VERSION "created by canmatrix"

NS_ :

BS_:

BU_: TCM iBooster HCU CIM SCM Right_Hand_Control Left_Hand_Control GPS VCM IC_2 XM GMRS Radio_CANtool Diagnostic_Tool_Digital_Wrench Information_System_Controller_1 STEERING_CONTROLLER VEHICLE_SECURITY RADIO_Hub ABS Battery_Management_Cntrl_2 Battery_Management_Cntrl_1 Auxiliary_Power_Unit_2 Auxiliary_Power_Unit_1 Electric_Propulsion_Cntrl_Unit_4 Electric_Propulsion_Cntrl_Unit_3 Electric_Propulsion_Cntrl_Unit_2 Electric_Propulsion_Cntrl_Unit_1 ECM IC

BO_ 2566687742 AFT1PSI2: 8 Vector__XXX
 SG_ HtrRes : 40|16@1+ (0.1,0) [0.0|6425.5] "ohm" Vector__XXX
 SG_ MaxRes : 32|16@1+ (250,0) [0.0|62500.0] "kohm" Vector__XXX
 SG_ Temp : 16|16@1+ (0.03125,-273) [-273.0|1734.96875] "°C" Vector__XXX
 SG_ RegenFailedCount : 8|8@1+ (1,0) [0.0|250.0] "" Vector__XXX
 SG_ PwrSupply : 4|2@1+ (1,0) [0.0|3.0] "" Vector__XXX
 SG_ DetectionStatus : 0|4@1+ (1,0) [0.0|15.0] "" Vector__XXX

BO_ 2365348350 ELS: 8 Vector__XXX
 SG_ EngLoadShareStatus : 2|4@1+ (1,0) [0.0|15.0] "" Vector__XXX
 SG_ EngUnloadStatus : 0|2@1+ (1,0) [0.0|3.0] "" Vector__XXX

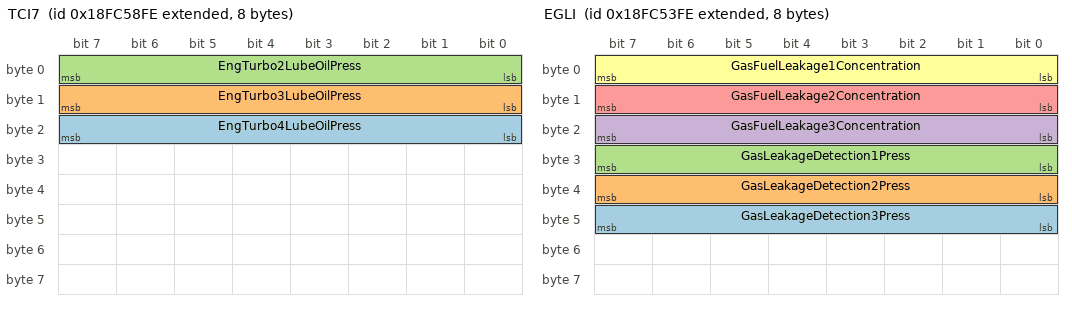
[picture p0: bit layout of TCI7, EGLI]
BO_ 2566674686 TCI7: 8 Vector__XXX
 SG_ EngTurbo4LubeOilPress : 16|8@1+ (4,0) [0.0|1000.0] "kPa" Vector__XXX
 SG_ EngTurbo3LubeOilPress : 8|8@1+ (4,0) [0.0|1000.0] "kPa" Vector__XXX
 SG_ EngTurbo2LubeOilPress : 0|8@1+ (4,0) [0.0|1000.0] "kPa" Vector__XXX

BO_ 2566674430 SCROII1: 8 Vector__XXX
 SG_ DslExhstFldQalityMalfunctionTime : 32|32@1+ (1,0) [0.0|4211081215.0] "s" Vector__XXX
 SG_ DieselExhaustFluidTank1EmptyTime : 0|32@1+ (1,0) [0.0|4211081215.0] "s" Vector__XXX

BO_ 2566674174 SCROII2: 8 Vector__XXX
 SG_ SCROperatorInducementTotalTime : 32|32@1+ (1,0) [0.0|4211081215.0] "s" Vector__XXX
 SG_ AFTSCRMalfunctionTime : 0|32@1+ (1,0) [0.0|4211081215.0] "s" Vector__XXX

BO_ 2566673406 EGLI: 8 Vector__XXX
 SG_ GasLeakageDetection3Press : 40|8@1+ (4,0) [0.0|100.0] "kPa" Vector__XXX
 SG_ GasLeakageDetection2Press : 32|8@1+ (4,0) [0.0|100.0] "kPa" Vector__XXX
 SG_ GasLeakageDetection1Press : 24|8@1+ (4,0) [0.0|100.0] "kPa" Vector__XXX
 SG_ GasFuelLeakage3Concentration : 16|8@1+ (0.5,0) [0.0|100.0] "%" Vector__XXX
 SG_ GasFuelLeakage2Concentration : 8|8@1+ (0.5,0) [0.0|100.0] "%" Vector__XXX
 SG_ GasFuelLeakage1Concentration : 0|8@1+ (0.5,0) [0.0|100.0] "%" Vector__XXX

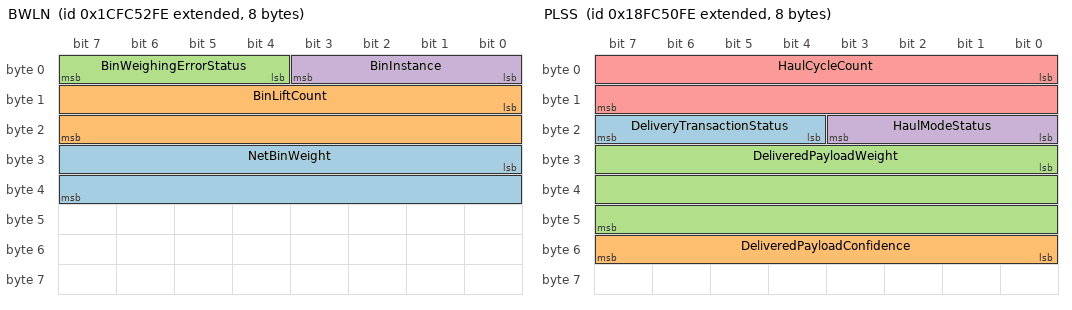
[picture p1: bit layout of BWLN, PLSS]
BO_ 2633782014 BWLN: 8 Vector__XXX
 SG_ NetBinWeight : 24|16@1+ (2,0) [0.0|128510.0] "kg" Vector__XXX
 SG_ BinLiftCount : 8|16@1+ (1,0) [0.0|64255.0] "" Vector__XXX
 SG_ BinWeighingErrorStatus : 4|4@1+ (1,0) [0.0|15.0] "" Vector__XXX
 SG_ BinInstance : 0|4@1+ (1,0) [0.0|15.0] "" Vector__XXX

BO_ 2365346302 ASC7: 8 Vector__XXX
 SG_ LiftAxle2Status : 3|3@1+ (1,0) [0.0|7.0] "" Vector__XXX
 SG_ LiftAxle1Status : 0|3@1+ (1,0) [0.0|7.0] "" Vector__XXX

BO_ 2566672638 PLSS: 8 Vector__XXX
 SG_ DeliveryTransactionStatus : 20|4@1+ (1,0) [0.0|15.0] "" Vector__XXX
 SG_ DeliveredPayloadConfidence : 48|8@1+ (0.5,0) [0.0|100.0] "%" Vector__XXX
 SG_ DeliveredPayloadWeight : 24|24@1+ (2,0) [0.0|32899070.0] "kg" Vector__XXX
 SG_ HaulModeStatus : 16|4@1+ (1,0) [0.0|15.0] "" Vector__XXX
 SG_ HaulCycleCount : 0|16@1+ (1,0) [0.0|64255.0] "" Vector__XXX

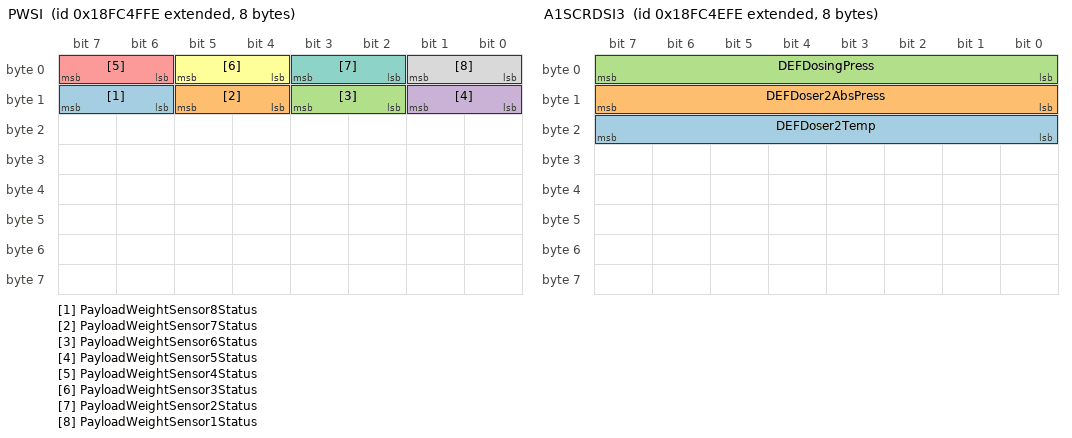
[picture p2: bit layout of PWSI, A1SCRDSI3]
BO_ 2566672382 PWSI: 8 Vector__XXX
 SG_ PayloadWeightSensor8Status : 14|2@1+ (1,0) [0.0|3.0] "" Vector__XXX
 SG_ PayloadWeightSensor7Status : 12|2@1+ (1,0) [0.0|3.0] "" Vector__XXX
 SG_ PayloadWeightSensor6Status : 10|2@1+ (1,0) [0.0|3.0] "" Vector__XXX
 SG_ PayloadWeightSensor5Status : 8|2@1+ (1,0) [0.0|3.0] "" Vector__XXX
 SG_ PayloadWeightSensor4Status : 6|2@1+ (1,0) [0.0|3.0] "" Vector__XXX
 SG_ PayloadWeightSensor3Status : 4|2@1+ (1,0) [0.0|3.0] "" Vector__XXX
 SG_ PayloadWeightSensor2Status : 2|2@1+ (1,0) [0.0|3.0] "" Vector__XXX
 SG_ PayloadWeightSensor1Status : 0|2@1+ (1,0) [0.0|3.0] "" Vector__XXX

BO_ 2566672126 A1SCRDSI3: 8 Vector__XXX
 SG_ DEFDoser2Temp : 16|8@1+ (1,-40) [-40.0|210.0] "°C" Vector__XXX
 SG_ DEFDoser2AbsPress : 8|8@1+ (8,0) [0.0|2000.0] "kPa" Vector__XXX
 SG_ DEFDosingPress : 0|8@1+ (4,0) [0.0|1000.0] "kPa" Vector__XXX

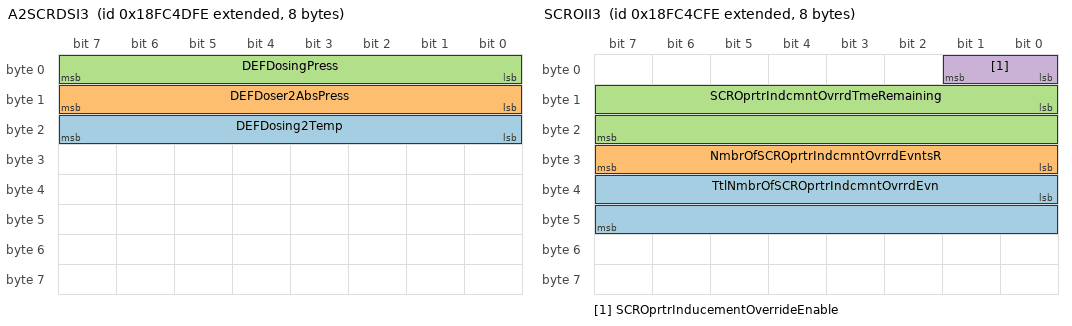
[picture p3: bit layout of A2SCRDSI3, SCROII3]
BO_ 2566671870 A2SCRDSI3: 8 Vector__XXX
 SG_ DEFDosing2Temp : 16|8@1+ (1,-40) [-40.0|210.0] "°C" Vector__XXX
 SG_ DEFDoser2AbsPress : 8|8@1+ (8,0) [0.0|2000.0] "kPa" Vector__XXX
 SG_ DEFDosingPress : 0|8@1+ (4,0) [0.0|1000.0] "kPa" Vector__XXX

BO_ 2566671614 SCROII3: 8 Vector__XXX
 SG_ TtlNmbrOfSCROprtrIndcmntOvrrdEvn : 32|16@1+ (1,0) [0.0|64255.0] "" Vector__XXX
 SG_ NmbrOfSCROprtrIndcmntOvrrdEvntsR : 24|8@1+ (1,0) [0.0|250.0] "" Vector__XXX
 SG_ SCROprtrIndcmntOvrrdTmeRemaining : 8|16@1+ (1,0) [0.0|64255.0] "s" Vector__XXX
 SG_ SCROprtrInducementOverrideEnable : 0|2@1+ (1,0) [0.0|3.0] "" Vector__XXX

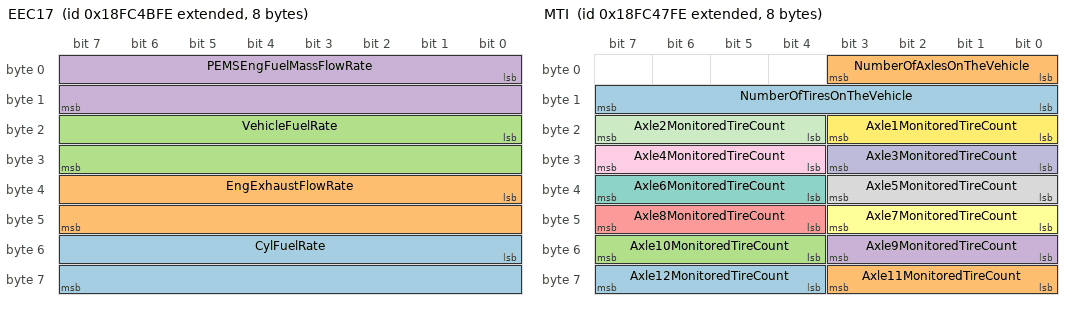
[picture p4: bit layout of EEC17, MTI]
BO_ 2566671358 EEC17: 8 Vector__XXX
 SG_ CylFuelRate : 48|16@1+ (0.03125,0) [0.0|2007.96875] "mg/stroke" Vector__XXX
 SG_ EngExhaustFlowRate : 32|16@1+ (0.2,0) [0.0|12851.0] "kg/h" Vector__XXX
 SG_ VehicleFuelRate : 16|16@1+ (0.02,0) [0.0|1285.1] "g/s" Vector__XXX
 SG_ PEMSEngFuelMassFlowRate : 0|16@1+ (0.02,0) [0.0|1285.1] "g/s" Vector__XXX

BO_ 2566671102 SCRSC: 8 Vector__XXX
 SG_ SCRSystemCleaningForcedStatus : 53|3@1+ (1,0) [0.0|7.0] "" Vector__XXX
 SG_ SCRSystmClnngAtmtcIntationConfig : 48|2@1+ (1,0) [0.0|3.0] "" Vector__XXX
 SG_ SCRSystmClnngInhbtdDTVhclSpdBlwA : 46|2@1+ (1,0) [0.0|3.0] "" Vector__XXX
 SG_ SCRSystmClnngInhbtdDTEngNtWrmdUp : 44|2@1+ (1,0) [0.0|3.0] "" Vector__XXX
 SG_ SCRSystmClnngInhbtdDTPrmnntSystm : 42|2@1+ (1,0) [0.0|3.0] "" Vector__XXX
 SG_ SCRSystmClnngInhbtdDTTmprrySystm : 40|2@1+ (1,0) [0.0|3.0] "" Vector__XXX
 SG_ SCRSystmClnngInhbtdDTSystmTmeout : 38|2@1+ (1,0) [0.0|3.0] "" Vector__XXX
 SG_ SCRSystmClnngInhbtdDTSystmFltAct : 36|2@1+ (1,0) [0.0|3.0] "" Vector__XXX
 SG_ SCRSystmClnngInhbtdDTLwExhstTemp : 34|2@1+ (1,0) [0.0|3.0] "" Vector__XXX
 SG_ SCRSystmClnngInhbtdDTPrkngBrkNtS : 32|2@1+ (1,0) [0.0|3.0] "" Vector__XXX
 SG_ SCRSystmClnngInhbtdDTVhclSpdAbvA : 30|2@1+ (1,0) [0.0|3.0] "" Vector__XXX
 SG_ SCRSystmClnngInhbtdDTOtOfNeutral : 28|2@1+ (1,0) [0.0|3.0] "" Vector__XXX
 SG_ SCRSystmClnngInhbtdDTAcclPdlOffI : 26|2@1+ (1,0) [0.0|3.0] "" Vector__XXX
 SG_ SCRSystmClnngInhbtdDeToPTOActive : 24|2@1+ (1,0) [0.0|3.0] "" Vector__XXX
 SG_ SCRSystmClnngInhbtdDTSrvcBrkActv : 22|2@1+ (1,0) [0.0|3.0] "" Vector__XXX
 SG_ SCRSystmClnngInhbtdDTCltchDsnggd : 20|2@1+ (1,0) [0.0|3.0] "" Vector__XXX
 SG_ SCRSystmClnngInhbtdDTInhbtSwitch : 18|2@1+ (1,0) [0.0|3.0] "" Vector__XXX
 SG_ SCRSystemCleaningInhibitedStatus : 16|2@1+ (1,0) [0.0|3.0] "" Vector__XXX
 SG_ SCRSystemCleaningStatus : 10|2@1+ (1,0) [0.0|3.0] "" Vector__XXX
 SG_ SCRSystemCleaningLampCmd : 0|3@1+ (1,0) [0.0|7.0] "" Vector__XXX

BO_ 2566670846 AT1HI2: 8 Vector__XXX
 SG_ SCRSysAvgDistBetweenCleanEvents : 160|32@1+ (0.125,0) [0.0|526385151.875] "km" Vector__XXX
 SG_ SCRSysAvgTimeBetweenCleanEvents : 128|32@1+ (1,0) [0.0|4211081215.0] "s" Vector__XXX
 SG_ SCRSysTotalSysCleanManReq : 96|32@1+ (1,0) [0.0|4211081215.0] "" Vector__XXX
 SG_ SCRSysTotalSysCleanInhReq : 64|32@1+ (1,0) [0.0|4211081215.0] "" Vector__XXX
 SG_ SCRSysTotalSysCleanEvents : 32|32@1+ (1,0) [0.0|4211081215.0] "" Vector__XXX
 SG_ SCRSysTotalCleanTime : 0|32@1+ (1,0) [0.0|4211081215.0] "s" Vector__XXX

BO_ 2566670590 AT2HI2: 8 Vector__XXX
 SG_ SCRSysAvgDistBetweenCleanEvents : 160|32@1+ (0.125,0) [0.0|526385151.875] "km" Vector__XXX
 SG_ SCRSysAvgTimeBetweenCleanEvents : 128|32@1+ (1,0) [0.0|4211081215.0] "s" Vector__XXX
 SG_ SCRSysTotalSysCleanManReq : 96|32@1+ (1,0) [0.0|4211081215.0] "" Vector__XXX
 SG_ SCRSysTotalSysCleanInhReq : 64|32@1+ (1,0) [0.0|4211081215.0] "" Vector__XXX
 SG_ SCRSysTotalSysCleanEvents : 32|32@1+ (1,0) [0.0|4211081215.0] "" Vector__XXX
 SG_ SCRSysTotalSysCleanTime : 0|32@1+ (1,0) [0.0|4211081215.0] "s" Vector__XXX

BO_ 2566670334 MTI: 8 Vector__XXX
 SG_ Axle12MonitoredTireCount : 60|4@1+ (1,0) [0.0|13.0] "" Vector__XXX
 SG_ Axle11MonitoredTireCount : 56|4@1+ (1,0) [0.0|13.0] "" Vector__XXX
 SG_ Axle10MonitoredTireCount : 52|4@1+ (1,0) [0.0|13.0] "" Vector__XXX
 SG_ Axle9MonitoredTireCount : 48|4@1+ (1,0) [0.0|13.0] "" Vector__XXX
 SG_ Axle8MonitoredTireCount : 44|4@1+ (1,0) [0.0|13.0] "" Vector__XXX
 SG_ Axle7MonitoredTireCount : 40|4@1+ (1,0) [0.0|13.0] "" Vector__XXX
 SG_ Axle6MonitoredTireCount : 36|4@1+ (1,0) [0.0|13.0] "" Vector__XXX
 SG_ Axle5MonitoredTireCount : 32|4@1+ (1,0) [0.0|13.0] "" Vector__XXX
 SG_ Axle4MonitoredTireCount : 28|4@1+ (1,0) [0.0|13.0] "" Vector__XXX
 SG_ Axle3MonitoredTireCount : 24|4@1+ (1,0) [0.0|13.0] "" Vector__XXX
 SG_ Axle2MonitoredTireCount : 20|4@1+ (1,0) [0.0|13.0] "" Vector__XXX
 SG_ Axle1MonitoredTireCount : 16|4@1+ (1,0) [0.0|13.0] "" Vector__XXX
 SG_ NumberOfTiresOnTheVehicle : 8|8@1+ (1,0) [0.0|250.0] "" Vector__XXX
 SG_ NumberOfAxlesOnTheVehicle : 0|4@1+ (1,0) [0.0|13.0] "" Vector__XXX

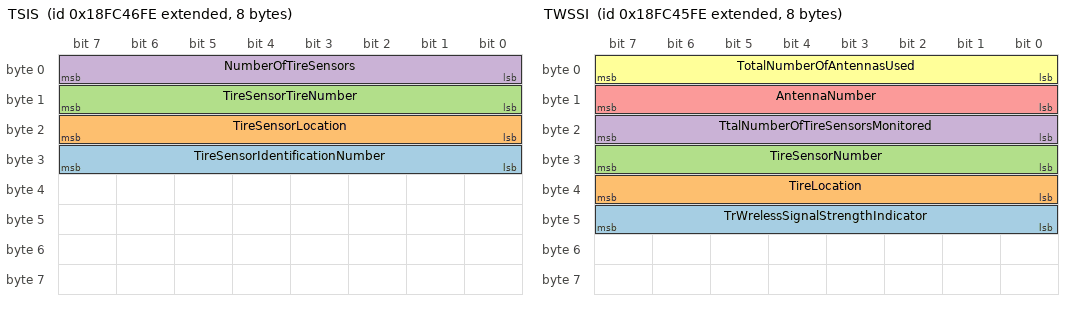
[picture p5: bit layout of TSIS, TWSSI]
BO_ 2566670078 TSIS: 8 Vector__XXX
 SG_ TireSensorIdentificationNumber : 24|8@1+ (1,0) [0.0|255.0] "" Vector__XXX
 SG_ TireSensorLocation : 16|8@1+ (1,0) [0.0|255.0] "" Vector__XXX
 SG_ TireSensorTireNumber : 8|8@1+ (1,0) [0.0|250.0] "" Vector__XXX
 SG_ NumberOfTireSensors : 0|8@1+ (1,0) [0.0|250.0] "" Vector__XXX

BO_ 2566669822 TWSSI: 8 Vector__XXX
 SG_ TrWrelessSignalStrengthIndicator : 40|8@1+ (0.5,-125) [-125.0|0.0] "dBm" Vector__XXX
 SG_ TireLocation : 32|8@1+ (1,0) [0.0|0.0] "" Vector__XXX
 SG_ TireSensorNumber : 24|8@1+ (1,0) [0.0|250.0] "" Vector__XXX
 SG_ TtalNumberOfTireSensorsMonitored : 16|8@1+ (1,0) [0.0|250.0] "" Vector__XXX
 SG_ AntennaNumber : 8|8@1+ (1,0) [0.0|250.0] "" Vector__XXX
 SG_ TotalNumberOfAntennasUsed : 0|8@1+ (1,0) [0.0|250.0] "" Vector__XXX

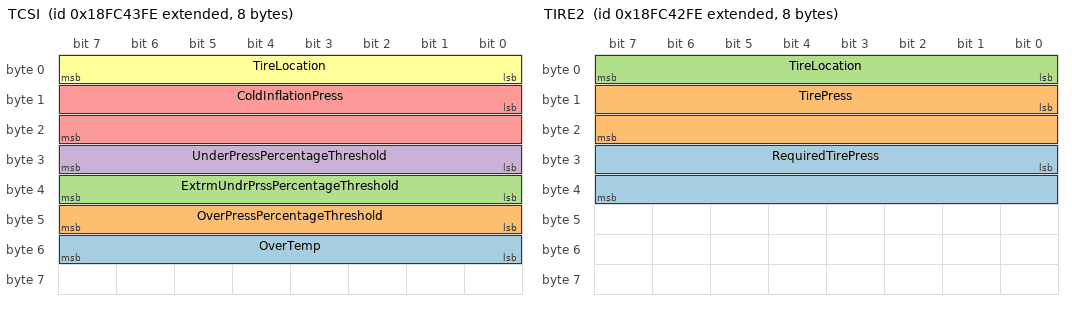
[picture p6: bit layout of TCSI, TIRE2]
BO_ 2566669310 TCSI: 8 Vector__XXX
 SG_ OverTemp : 48|8@1+ (1,-40) [-40.0|210.0] "°C" Vector__XXX
 SG_ OverPressPercentageThreshold : 40|8@1+ (0.5,0) [0.0|125.0] "%" Vector__XXX
 SG_ ExtrmUndrPrssPercentageThreshold : 32|8@1+ (0.5,0) [0.0|125.0] "%" Vector__XXX
 SG_ UnderPressPercentageThreshold : 24|8@1+ (0.5,0) [0.0|125.0] "%" Vector__XXX
 SG_ ColdInflationPress : 8|16@1+ (1,0) [0.0|64255.0] "kPa" Vector__XXX
 SG_ TireLocation : 0|8@1+ (1,0) [0.0|0.0] "" Vector__XXX

BO_ 2566669054 TIRE2: 8 Vector__XXX
 SG_ RequiredTirePress : 24|16@1+ (1,0) [0.0|64255.0] "kPa" Vector__XXX
 SG_ TirePress : 8|16@1+ (1,0) [0.0|64255.0] "kPa" Vector__XXX
 SG_ TireLocation : 0|8@1+ (1,0) [0.0|0.0] "" Vector__XXX

BO_ 2566668798 AF4: 8 Vector__XXX
 SG_ EngFl2InjctorMeteringRail1Press2 : 48|16@1+ (2,0) [0.0|128510.0] "kPa" Vector__XXX
 SG_ EngFel2InjectorMeteringRail2Temp : 40|8@1+ (1,-40) [-40.0|210.0] "°C" Vector__XXX
 SG_ EngFel2InjectorMeteringRail1Temp : 32|8@1+ (1,-40) [-40.0|210.0] "°C" Vector__XXX
 SG_ EngFl2InjectorMeteringRail2Press : 16|16@1+ (2,0) [0.0|128510.0] "kPa" Vector__XXX
 SG_ EngFl2InjectorMeteringRail1Press : 0|16@1+ (2,0) [0.0|128510.0] "kPa" Vector__XXX

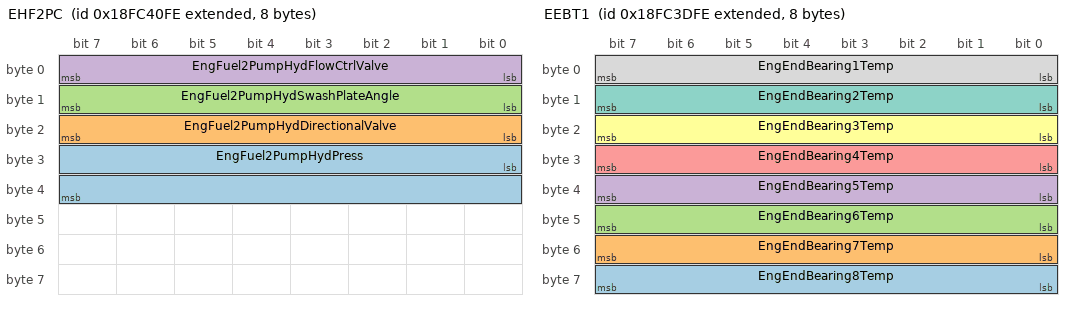
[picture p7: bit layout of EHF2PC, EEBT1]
BO_ 2566668542 EHF2PC: 8 Vector__XXX
 SG_ EngFuel2PumpHydPress : 24|16@1+ (2,0) [0.0|128510.0] "kPa" Vector__XXX
 SG_ EngFuel2PumpHydDirectionalValve : 16|8@1+ (0.4,0) [0.0|100.0] "%" Vector__XXX
 SG_ EngFuel2PumpHydSwashPlateAngle : 8|8@1+ (0.4,0) [0.0|100.0] "%" Vector__XXX
 SG_ EngFuel2PumpHydFlowCtrlValve : 0|8@1+ (0.4,0) [0.0|100.0] "%" Vector__XXX

BO_ 2566668286 ETCC2: 8 Vector__XXX
 SG_ EngStagedTurboSolenoidStatus : 0|8@1+ (0.4,0) [0.0|100.0] "%" Vector__XXX

BO_ 2566668030 HEDPI: 8 Vector__XXX
 SG_ HtExchngerDebrisPurgeApproaching : 2|2@1+ (1,0) [0.0|3.0] "" Vector__XXX
 SG_ HeatExchangerDebrisPurgeStatus : 0|2@1+ (1,0) [0.0|3.0] "" Vector__XXX

BO_ 2566667774 EEBT1: 8 Vector__XXX
 SG_ EngEndBearing8Temp : 56|8@1+ (1,-40) [-40.0|210.0] "°C" Vector__XXX
 SG_ EngEndBearing7Temp : 48|8@1+ (1,-40) [-40.0|210.0] "°C" Vector__XXX
 SG_ EngEndBearing6Temp : 40|8@1+ (1,-40) [-40.0|210.0] "°C" Vector__XXX
 SG_ EngEndBearing5Temp : 32|8@1+ (1,-40) [-40.0|210.0] "°C" Vector__XXX
 SG_ EngEndBearing4Temp : 24|8@1+ (1,-40) [-40.0|210.0] "°C" Vector__XXX
 SG_ EngEndBearing3Temp : 16|8@1+ (1,-40) [-40.0|210.0] "°C" Vector__XXX
 SG_ EngEndBearing2Temp : 8|8@1+ (1,-40) [-40.0|210.0] "°C" Vector__XXX
 SG_ EngEndBearing1Temp : 0|8@1+ (1,-40) [-40.0|210.0] "°C" Vector__XXX

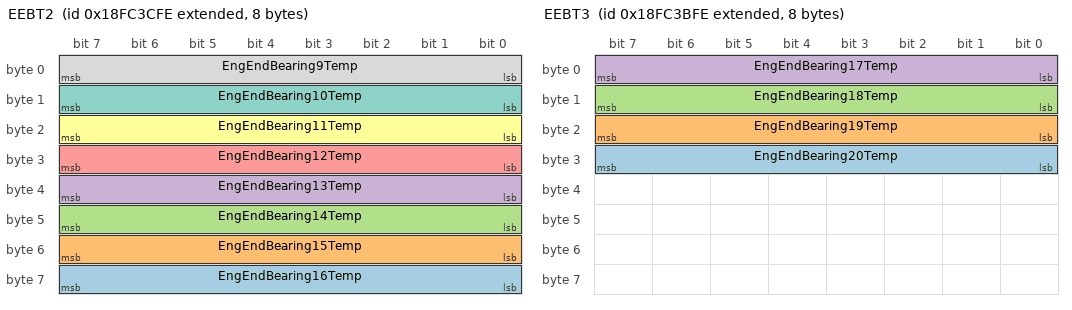
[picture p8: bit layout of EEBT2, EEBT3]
BO_ 2566667518 EEBT2: 8 Vector__XXX
 SG_ EngEndBearing16Temp : 56|8@1+ (1,-40) [-40.0|210.0] "°C" Vector__XXX
 SG_ EngEndBearing15Temp : 48|8@1+ (1,-40) [-40.0|210.0] "°C" Vector__XXX
 SG_ EngEndBearing14Temp : 40|8@1+ (1,-40) [-40.0|210.0] "°C" Vector__XXX
 SG_ EngEndBearing13Temp : 32|8@1+ (1,-40) [-40.0|210.0] "°C" Vector__XXX
 SG_ EngEndBearing12Temp : 24|8@1+ (1,-40) [-40.0|210.0] "°C" Vector__XXX
 SG_ EngEndBearing11Temp : 16|8@1+ (1,-40) [-40.0|210.0] "°C" Vector__XXX
 SG_ EngEndBearing10Temp : 8|8@1+ (1,-40) [-40.0|210.0] "°C" Vector__XXX
 SG_ EngEndBearing9Temp : 0|8@1+ (1,-40) [-40.0|210.0] "°C" Vector__XXX

BO_ 2566667262 EEBT3: 8 Vector__XXX
 SG_ EngEndBearing20Temp : 24|8@1+ (1,-40) [-40.0|210.0] "°C" Vector__XXX
 SG_ EngEndBearing19Temp : 16|8@1+ (1,-40) [-40.0|210.0] "°C" Vector__XXX
 SG_ EngEndBearing18Temp : 8|8@1+ (1,-40) [-40.0|210.0] "°C" Vector__XXX
 SG_ EngEndBearing17Temp : 0|8@1+ (1,-40) [-40.0|210.0] "°C" Vector__XXX

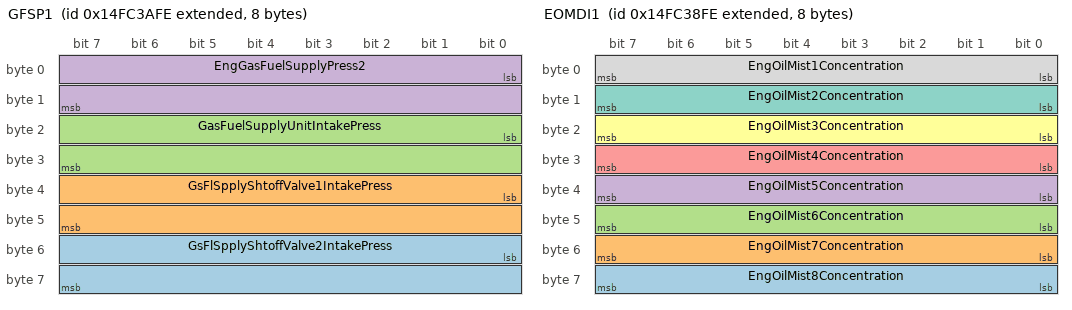
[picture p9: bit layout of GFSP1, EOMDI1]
BO_ 2499558142 GFSP1: 8 Vector__XXX
 SG_ GsFlSpplyShtoffValve2IntakePress : 48|16@1+ (0.5,0) [0.0|32127.5] "kPa" Vector__XXX
 SG_ GsFlSpplyShtoffValve1IntakePress : 32|16@1+ (0.5,0) [0.0|32127.5] "kPa" Vector__XXX
 SG_ GasFuelSupplyUnitIntakePress : 16|16@1+ (0.5,0) [0.0|32127.5] "kPa" Vector__XXX
 SG_ EngGasFuelSupplyPress2 : 0|16@1+ (0.5,0) [0.0|32127.5] "kPa" Vector__XXX

BO_ 2499557886 GFSP2: 8 Vector__XXX
 SG_ PlantInertGasSupplyOutletPress : 16|16@1+ (0.5,0) [0.0|32127.5] "kPa" Vector__XXX
 SG_ PlantGasFuelSupplyOutletPress : 0|16@1+ (0.5,0) [0.0|32127.5] "kPa" Vector__XXX

BO_ 2499557630 EOMDI1: 8 Vector__XXX
 SG_ EngOilMist8Concentration : 56|8@1+ (1,0) [0.0|250.0] "%" Vector__XXX
 SG_ EngOilMist7Concentration : 48|8@1+ (1,0) [0.0|250.0] "%" Vector__XXX
 SG_ EngOilMist6Concentration : 40|8@1+ (1,0) [0.0|250.0] "%" Vector__XXX
 SG_ EngOilMist5Concentration : 32|8@1+ (1,0) [0.0|250.0] "%" Vector__XXX
 SG_ EngOilMist4Concentration : 24|8@1+ (1,0) [0.0|250.0] "%" Vector__XXX
 SG_ EngOilMist3Concentration : 16|8@1+ (1,0) [0.0|250.0] "%" Vector__XXX
 SG_ EngOilMist2Concentration : 8|8@1+ (1,0) [0.0|250.0] "%" Vector__XXX
 SG_ EngOilMist1Concentration : 0|8@1+ (1,0) [0.0|250.0] "%" Vector__XXX

BO_ 2499557374 EOMDI2: 8 Vector__XXX
 SG_ EngOilMist10Concentration : 8|8@1+ (1,0) [0.0|250.0] "%" Vector__XXX
 SG_ EngOilMist9Concentration : 0|8@1+ (1,0) [0.0|250.0] "%" Vector__XXX

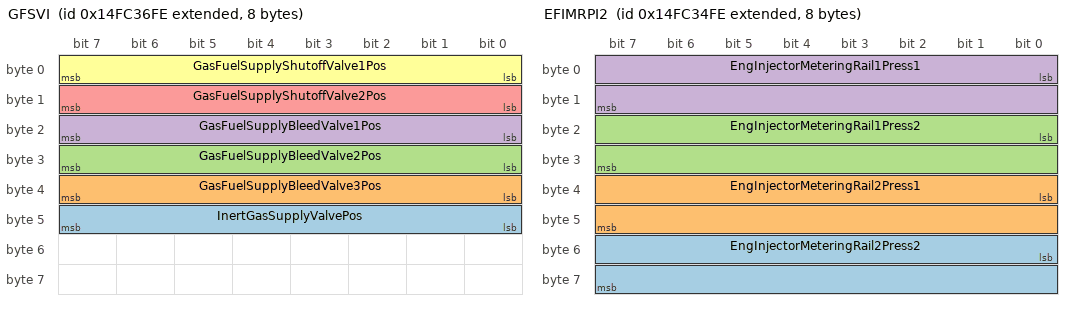
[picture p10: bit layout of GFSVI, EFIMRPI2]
BO_ 2499557118 GFSVI: 8 Vector__XXX
 SG_ InertGasSupplyValvePos : 40|8@1+ (0.4,0) [0.0|100.0] "%" Vector__XXX
 SG_ GasFuelSupplyBleedValve3Pos : 32|8@1+ (0.4,0) [0.0|100.0] "%" Vector__XXX
 SG_ GasFuelSupplyBleedValve2Pos : 24|8@1+ (0.4,0) [0.0|100.0] "%" Vector__XXX
 SG_ GasFuelSupplyBleedValve1Pos : 16|8@1+ (0.4,0) [0.0|100.0] "%" Vector__XXX
 SG_ GasFuelSupplyShutoffValve2Pos : 8|8@1+ (0.4,0) [0.0|100.0] "%" Vector__XXX
 SG_ GasFuelSupplyShutoffValve1Pos : 0|8@1+ (0.4,0) [0.0|100.0] "%" Vector__XXX

BO_ 2566665726 AT2P1I: 8 Vector__XXX
 SG_ TwoMotorSpd : 8|16@1+ (0.5,0) [0.0|32127.5] "rpm" Vector__XXX
 SG_ Htr : 0|8@1+ (0.4,0) [0.0|100.0] "%" Vector__XXX

BO_ 2499556606 EFIMRPI2: 8 Vector__XXX
 SG_ EngInjectorMeteringRail2Press2 : 48|16@1+ (5,0) [0.0|321275.0] "kPa" Vector__XXX
 SG_ EngInjectorMeteringRail2Press1 : 32|16@1+ (5,0) [0.0|321275.0] "kPa" Vector__XXX
 SG_ EngInjectorMeteringRail1Press2 : 16|16@1+ (5,0) [0.0|321275.0] "kPa" Vector__XXX
 SG_ EngInjectorMeteringRail1Press1 : 0|16@1+ (5,0) [0.0|321275.0] "kPa" Vector__XXX

BO_ 2499556350 EFIMRPI3: 8 Vector__XXX
 SG_ EngInjctrMtringRail2DesiredPress : 16|16@1+ (5,0) [0.0|321275.0] "kPa" Vector__XXX
 SG_ EngInjctrMtringRail1DesiredPress : 0|16@1+ (5,0) [0.0|321275.0] "kPa" Vector__XXX

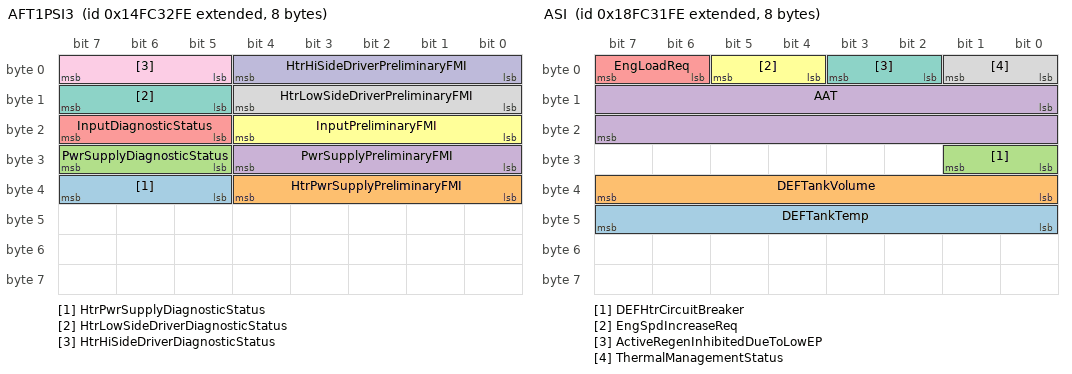
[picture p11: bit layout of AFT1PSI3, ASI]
BO_ 2499556094 AFT1PSI3: 8 Vector__XXX
 SG_ HtrPwrSupplyDiagnosticStatus : 37|3@1+ (1,0) [0.0|7.0] "" Vector__XXX
 SG_ HtrPwrSupplyPreliminaryFMI : 32|5@1+ (1,0) [0.0|31.0] "" Vector__XXX
 SG_ PwrSupplyDiagnosticStatus : 29|3@1+ (1,0) [0.0|7.0] "" Vector__XXX
 SG_ PwrSupplyPreliminaryFMI : 24|5@1+ (1,0) [0.0|31.0] "" Vector__XXX
 SG_ InputDiagnosticStatus : 21|3@1+ (1,0) [0.0|7.0] "" Vector__XXX
 SG_ InputPreliminaryFMI : 16|5@1+ (1,0) [0.0|31.0] "" Vector__XXX
 SG_ HtrLowSideDriverDiagnosticStatus : 13|3@1+ (1,0) [0.0|7.0] "" Vector__XXX
 SG_ HtrLowSideDriverPreliminaryFMI : 8|5@1+ (1,0) [0.0|31.0] "" Vector__XXX
 SG_ HtrHiSideDriverDiagnosticStatus : 5|3@1+ (1,0) [0.0|7.0] "" Vector__XXX
 SG_ HtrHiSideDriverPreliminaryFMI : 0|5@1+ (1,0) [0.0|31.0] "" Vector__XXX

BO_ 2566664702 ASI: 8 Vector__XXX
 SG_ DEFTankTemp : 40|8@1+ (1,-40) [-40.0|210.0] "°C" Vector__XXX
 SG_ DEFTankVolume : 32|8@1+ (0.4,0) [0.0|100.0] "%" Vector__XXX
 SG_ DEFHtrCircuitBreaker : 24|2@1+ (1,0) [0.0|3.0] "" Vector__XXX
 SG_ AAT : 8|16@1+ (0.03125,-273) [-273.0|1734.96875] "°C" Vector__XXX
 SG_ EngLoadReq : 6|2@1+ (1,0) [0.0|3.0] "" Vector__XXX
 SG_ EngSpdIncreaseReq : 4|2@1+ (1,0) [0.0|3.0] "" Vector__XXX
 SG_ ActiveRegenInhibitedDueToLowEP : 2|2@1+ (1,0) [0.0|3.0] "" Vector__XXX
 SG_ ThermalManagementStatus : 0|2@1+ (1,0) [0.0|3.0] "" Vector__XXX

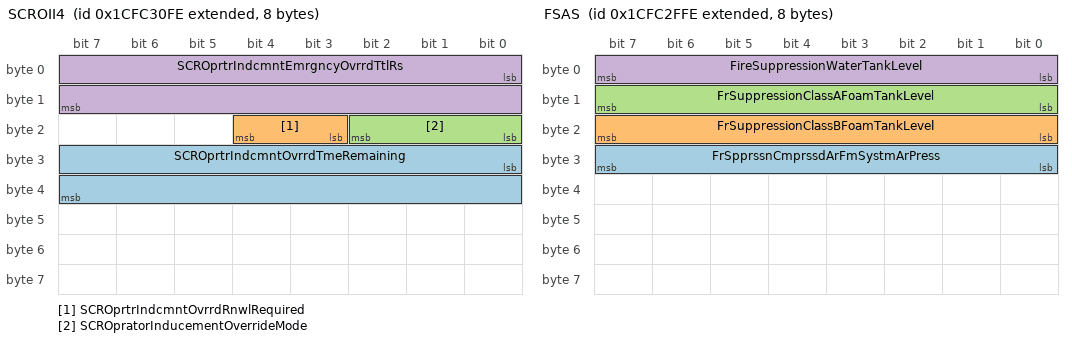
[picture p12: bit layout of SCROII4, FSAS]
BO_ 2633773310 SCROII4: 8 Vector__XXX
 SG_ SCROprtrIndcmntOvrrdTmeRemaining : 24|16@1+ (1,0) [0.0|64255.0] "min" Vector__XXX
 SG_ SCROprtrIndcmntOvrrdRnwlRequired : 19|2@1+ (1,0) [0.0|3.0] "" Vector__XXX
 SG_ SCROpratorInducementOverrideMode : 16|3@1+ (1,0) [0.0|7.0] "" Vector__XXX
 SG_ SCROprtrIndcmntEmrgncyOvrrdTtlRs : 0|16@1+ (1,0) [0.0|64255.0] "" Vector__XXX

BO_ 2633773054 FSAS: 8 Vector__XXX
 SG_ FrSpprssnCmprssdArFmSystmArPress : 24|8@1+ (8,0) [0.0|2000.0] "kPa" Vector__XXX
 SG_ FrSuppressionClassBFoamTankLevel : 16|8@1+ (0.4,0) [0.0|100.0] "%" Vector__XXX
 SG_ FrSuppressionClassAFoamTankLevel : 8|8@1+ (0.4,0) [0.0|100.0] "%" Vector__XXX
 SG_ FireSuppressionWaterTankLevel : 0|8@1+ (0.4,0) [0.0|100.0] "%" Vector__XXX

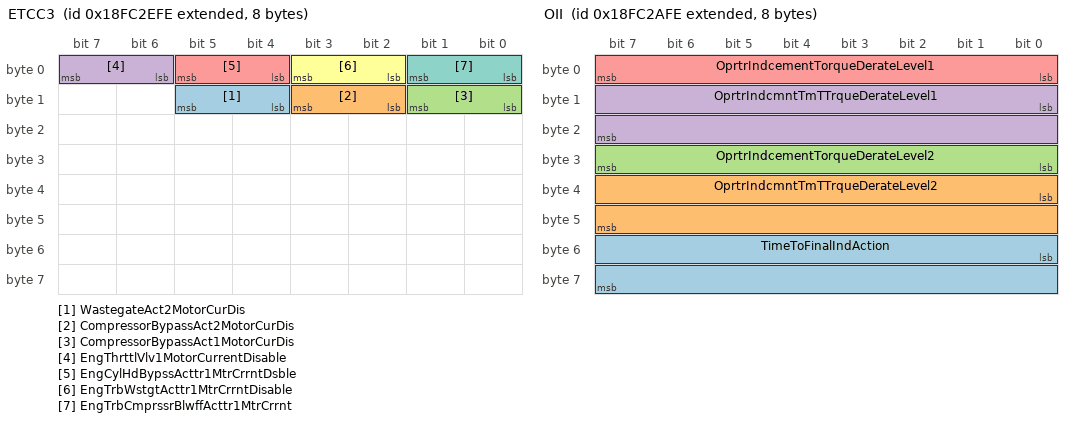
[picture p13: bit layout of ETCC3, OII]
BO_ 2566663934 ETCC3: 8 Vector__XXX
 SG_ WastegateAct2MotorCurDis : 12|2@1+ (1,0) [0.0|3.0] "" Vector__XXX
 SG_ CompressorBypassAct2MotorCurDis : 10|2@1+ (1,0) [0.0|3.0] "" Vector__XXX
 SG_ CompressorBypassAct1MotorCurDis : 8|2@1+ (1,0) [0.0|3.0] "" Vector__XXX
 SG_ EngThrttlVlv1MotorCurrentDisable : 6|2@1+ (1,0) [0.0|3.0] "" Vector__XXX
 SG_ EngCylHdBypssActtr1MtrCrrntDsble : 4|2@1+ (1,0) [0.0|3.0] "" Vector__XXX
 SG_ EngTrbWstgtActtr1MtrCrrntDisable : 2|2@1+ (1,0) [0.0|3.0] "" Vector__XXX
 SG_ EngTrbCmprssrBlwffActtr1MtrCrrnt : 0|2@1+ (1,0) [0.0|3.0] "" Vector__XXX

BO_ 2566663678 AF5: 8 Vector__XXX
 SG_ EngFl2InjectorMeteringRail1Temp2 : 32|8@1+ (1,-40) [-40.0|210.0] "°C" Vector__XXX
 SG_ LNGTank2VaporPress : 16|16@1+ (0.1,0) [0.0|6425.5] "kPa" Vector__XXX
 SG_ LNGTank1VaporPress : 0|16@1+ (0.1,0) [0.0|6425.5] "kPa" Vector__XXX

BO_ 2566663422 BCLC: 8 Vector__XXX
 SG_ TrlrBrkClprLnngClranceAxle5Right : 38|2@1+ (1,0) [0.0|3.0] "" Vector__XXX
 SG_ TrlrBrkClprLnngClaranceAxle5Left : 36|2@1+ (1,0) [0.0|3.0] "" Vector__XXX
 SG_ TrlrBrkClprLnngClranceAxle4Right : 34|2@1+ (1,0) [0.0|3.0] "" Vector__XXX
 SG_ TrlrBrkClprLnngClaranceAxle4Left : 32|2@1+ (1,0) [0.0|3.0] "" Vector__XXX
 SG_ TrlrBrkClprLnngClranceAxle3Right : 30|2@1+ (1,0) [0.0|3.0] "" Vector__XXX
 SG_ TrlrBrkClprLnngClaranceAxle3Left : 28|2@1+ (1,0) [0.0|3.0] "" Vector__XXX
 SG_ TrlrBrkClprLnngClranceAxle2Right : 26|2@1+ (1,0) [0.0|3.0] "" Vector__XXX
 SG_ TrlrBrkClprLnngClaranceAxle2Left : 24|2@1+ (1,0) [0.0|3.0] "" Vector__XXX
 SG_ TrlrBrkClprLnngClranceAxle1Right : 22|2@1+ (1,0) [0.0|3.0] "" Vector__XXX
 SG_ TrlrBrkClprLnngClaranceAxle1Left : 20|2@1+ (1,0) [0.0|3.0] "" Vector__XXX
 SG_ TrctrBrkClprLnngClrnceAxle5Right : 18|2@1+ (1,0) [0.0|3.0] "" Vector__XXX
 SG_ TrctrBrkClprLnngClranceAxle5Left : 16|2@1+ (1,0) [0.0|3.0] "" Vector__XXX
 SG_ TrctrBrkClprLnngClrnceAxle4Right : 14|2@1+ (1,0) [0.0|3.0] "" Vector__XXX
 SG_ TrctrBrkClprLnngClranceAxle4Left : 12|2@1+ (1,0) [0.0|3.0] "" Vector__XXX
 SG_ TrctrBrkClprLnngClrnceAxle3Right : 10|2@1+ (1,0) [0.0|3.0] "" Vector__XXX
 SG_ TrctrBrkClprLnngClranceAxle3Left : 8|2@1+ (1,0) [0.0|3.0] "" Vector__XXX
 SG_ TrctrBrkClprLnngClrnceAxle2Right : 6|2@1+ (1,0) [0.0|3.0] "" Vector__XXX
 SG_ TrctrBrkClprLnngClranceAxle2Left : 4|2@1+ (1,0) [0.0|3.0] "" Vector__XXX
 SG_ TrctrBrkClprLnngClrnceAxle1Right : 2|2@1+ (1,0) [0.0|3.0] "" Vector__XXX
 SG_ TrctrBrkClprLnngClranceAxle1Left : 0|2@1+ (1,0) [0.0|3.0] "" Vector__XXX

BO_ 2566663166 CCVS4: 8 Vector__XXX
 SG_ CruiseCtrlAdjustedMaxSpeed : 16|16@1+ (0.00390625,0) [0.0|250.996] "km/h" Vector__XXX
 SG_ AppliedVehicleSpeedLimit : 0|16@1+ (0.00390625,0) [0.0|250.996] "km/h" Vector__XXX

BO_ 2566662910 OII: 8 Vector__XXX
 SG_ TimeToFinalIndAction : 48|16@1+ (1,0) [0.0|64255.0] "min" Vector__XXX
 SG_ OprtrIndcmntTmTTrqueDerateLevel2 : 32|16@1+ (1,0) [0.0|64255.0] "min" Vector__XXX
 SG_ OprtrIndcementTorqueDerateLevel2 : 24|8@1+ (1,0) [0.0|250.0] "%" Vector__XXX
 SG_ OprtrIndcmntTmTTrqueDerateLevel1 : 8|16@1+ (1,0) [0.0|64255.0] "min" Vector__XXX
 SG_ OprtrIndcementTorqueDerateLevel1 : 0|8@1+ (1,0) [0.0|250.0] "%" Vector__XXX

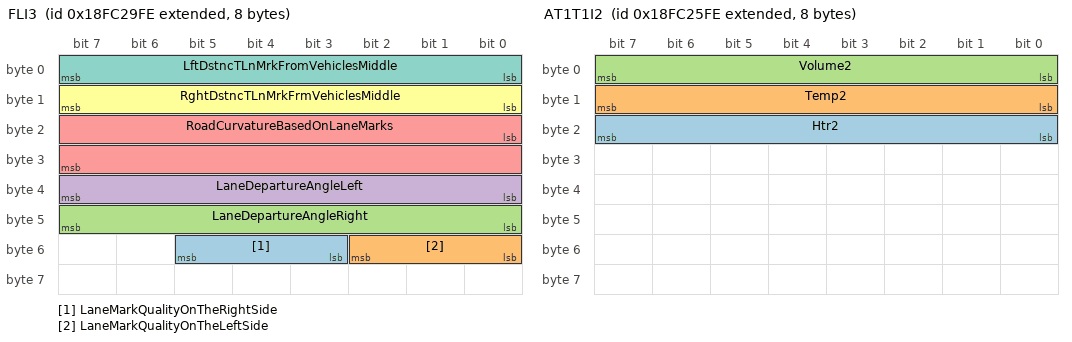
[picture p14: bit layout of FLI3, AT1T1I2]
BO_ 2566662654 FLI3: 8 Vector__XXX
 SG_ LaneMarkQualityOnTheRightSide : 51|3@1+ (1,0) [0.0|7.0] "" Vector__XXX
 SG_ LaneMarkQualityOnTheLeftSide : 48|3@1+ (1,0) [0.0|7.0] "" Vector__XXX
 SG_ LaneDepartureAngleRight : 40|8@1+ (0.1,-12.5) [-12.5|12.5] "deg" Vector__XXX
 SG_ LaneDepartureAngleLeft : 32|8@1+ (0.1,-12.5) [-12.5|12.5] "deg" Vector__XXX
 SG_ RoadCurvatureBasedOnLaneMarks : 16|16@1+ (0.0078125,-250) [-250.0|251.992] "1/km" Vector__XXX
 SG_ RghtDstncTLnMrkFrmVehiclesMiddle : 8|8@1+ (0.02,0) [0.0|5.0] "m" Vector__XXX
 SG_ LftDstncTLnMrkFromVehiclesMiddle : 0|8@1+ (0.02,0) [0.0|5.0] "m" Vector__XXX

BO_ 2566662142 A1DEFI2: 8 Vector__XXX
 SG_ Ctrl2Temp : 8|8@1+ (1,-40) [-40.0|210.0] "°C" Vector__XXX
 SG_ Ctrl1Temp : 0|8@1+ (1,-40) [-40.0|210.0] "°C" Vector__XXX

BO_ 2566661630 AT1T1I2: 8 Vector__XXX
 SG_ Htr2 : 16|8@1+ (0.4,0) [0.0|100.0] "%" Vector__XXX
 SG_ Temp2 : 8|8@1+ (1,-40) [-40.0|210.0] "°C" Vector__XXX
 SG_ Volume2 : 0|8@1+ (0.4,0) [0.0|100.0] "%" Vector__XXX

BO_ 2566661374 A2DEFT1: 8 Vector__XXX
 SG_ Ctrl2Temp : 8|8@1+ (1,-40) [-40.0|210.0] "°C" Vector__XXX
 SG_ CtrlTemp : 0|8@1+ (1,-40) [-40.0|210.0] "°C" Vector__XXX
 SG_ Htr2 : 16|8@1+ (0.4,0) [0.0|100.0] "%" Vector__XXX
 SG_ Temp2 : 8|8@1+ (1,-40) [-40.0|210.0] "°C" Vector__XXX
 SG_ Volume2 : 0|8@1+ (0.4,0) [0.0|100.0] "%" Vector__XXX

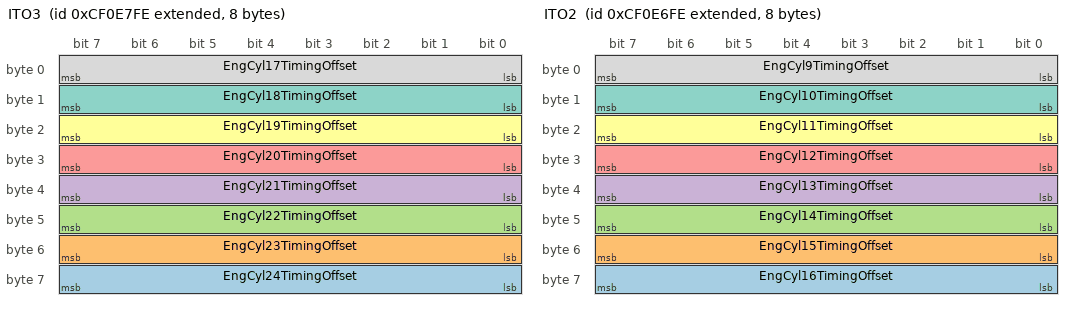
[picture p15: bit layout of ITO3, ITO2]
BO_ 2364598270 ITO3: 8 Vector__XXX
 SG_ EngCyl24TimingOffset : 56|8@1+ (0.1,-12.5) [-12.5|12.5] "deg" Vector__XXX
 SG_ EngCyl23TimingOffset : 48|8@1+ (0.1,-12.5) [-12.5|12.5] "deg" Vector__XXX
 SG_ EngCyl22TimingOffset : 40|8@1+ (0.1,-12.5) [-12.5|12.5] "deg" Vector__XXX
 SG_ EngCyl21TimingOffset : 32|8@1+ (0.1,-12.5) [-12.5|12.5] "deg" Vector__XXX
 SG_ EngCyl20TimingOffset : 24|8@1+ (0.1,-12.5) [-12.5|12.5] "deg" Vector__XXX
 SG_ EngCyl19TimingOffset : 16|8@1+ (0.1,-12.5) [-12.5|12.5] "deg" Vector__XXX
 SG_ EngCyl18TimingOffset : 8|8@1+ (0.1,-12.5) [-12.5|12.5] "deg" Vector__XXX
 SG_ EngCyl17TimingOffset : 0|8@1+ (0.1,-12.5) [-12.5|12.5] "deg" Vector__XXX

BO_ 2364598014 ITO2: 8 Vector__XXX
 SG_ EngCyl16TimingOffset : 56|8@1+ (0.1,-12.5) [-12.5|12.5] "deg" Vector__XXX
 SG_ EngCyl15TimingOffset : 48|8@1+ (0.1,-12.5) [-12.5|12.5] "deg" Vector__XXX
 SG_ EngCyl14TimingOffset : 40|8@1+ (0.1,-12.5) [-12.5|12.5] "deg" Vector__XXX
 SG_ EngCyl13TimingOffset : 32|8@1+ (0.1,-12.5) [-12.5|12.5] "deg" Vector__XXX
 SG_ EngCyl12TimingOffset : 24|8@1+ (0.1,-12.5) [-12.5|12.5] "deg" Vector__XXX
 SG_ EngCyl11TimingOffset : 16|8@1+ (0.1,-12.5) [-12.5|12.5] "deg" Vector__XXX
 SG_ EngCyl10TimingOffset : 8|8@1+ (0.1,-12.5) [-12.5|12.5] "deg" Vector__XXX
 SG_ EngCyl9TimingOffset : 0|8@1+ (0.1,-12.5) [-12.5|12.5] "deg" Vector__XXX

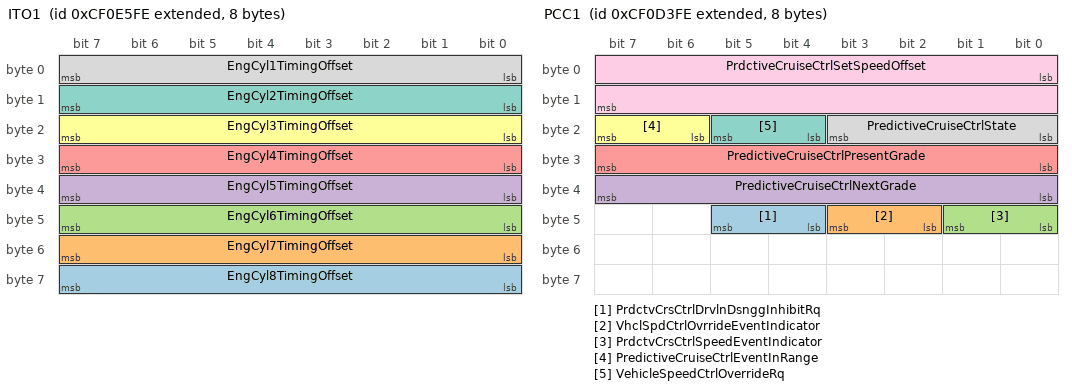
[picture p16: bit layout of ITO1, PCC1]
BO_ 2364597758 ITO1: 8 Vector__XXX
 SG_ EngCyl8TimingOffset : 56|8@1+ (0.1,-12.5) [-12.5|12.5] "deg" Vector__XXX
 SG_ EngCyl7TimingOffset : 48|8@1+ (0.1,-12.5) [-12.5|12.5] "deg" Vector__XXX
 SG_ EngCyl6TimingOffset : 40|8@1+ (0.1,-12.5) [-12.5|12.5] "deg" Vector__XXX
 SG_ EngCyl5TimingOffset : 32|8@1+ (0.1,-12.5) [-12.5|12.5] "deg" Vector__XXX
 SG_ EngCyl4TimingOffset : 24|8@1+ (0.1,-12.5) [-12.5|12.5] "deg" Vector__XXX
 SG_ EngCyl3TimingOffset : 16|8@1+ (0.1,-12.5) [-12.5|12.5] "deg" Vector__XXX
 SG_ EngCyl2TimingOffset : 8|8@1+ (0.1,-12.5) [-12.5|12.5] "deg" Vector__XXX
 SG_ EngCyl1TimingOffset : 0|8@1+ (0.1,-12.5) [-12.5|12.5] "deg" Vector__XXX

BO_ 2364593150 PCC1: 8 Vector__XXX
 SG_ PrdctvCrsCtrlDrvlnDsnggInhibitRq : 44|2@1+ (1,0) [0.0|3.0] "" Vector__XXX
 SG_ VhclSpdCtrlOvrrideEventIndicator : 42|2@1+ (1,0) [0.0|3.0] "" Vector__XXX
 SG_ PrdctvCrsCtrlSpeedEventIndicator : 40|2@1+ (1,0) [0.0|3.0] "" Vector__XXX
 SG_ PredictiveCruiseCtrlNextGrade : 32|8@1+ (0.125,-16) [-16.0|15.25] "%" Vector__XXX
 SG_ PredictiveCruiseCtrlPresentGrade : 24|8@1+ (0.125,-16) [-16.0|15.25] "%" Vector__XXX
 SG_ PredictiveCruiseCtrlEventInRange : 22|2@1+ (1,0) [0.0|3.0] "" Vector__XXX
 SG_ VehicleSpeedCtrlOverrideRq : 20|2@1+ (1,0) [0.0|3.0] "" Vector__XXX
 SG_ PredictiveCruiseCtrlState : 16|4@1+ (1,0) [0.0|15.0] "" Vector__XXX
 SG_ PrdctiveCruiseCtrlSetSpeedOffset : 0|16@1+ (0.00390625,-125) [-125.0|125.996] "km/h" Vector__XXX

BO_ 2364592894 EEC18: 8 Vector__XXX
 SG_ InAirSourceVlv : 16|2@1+ (1,0) [0.0|3.0] "" Vector__XXX
 SG_ EngCylHeadBypassActuator1Cmd : 0|16@1+ (0.0025,0) [0.0|160.6375] "%" Vector__XXX

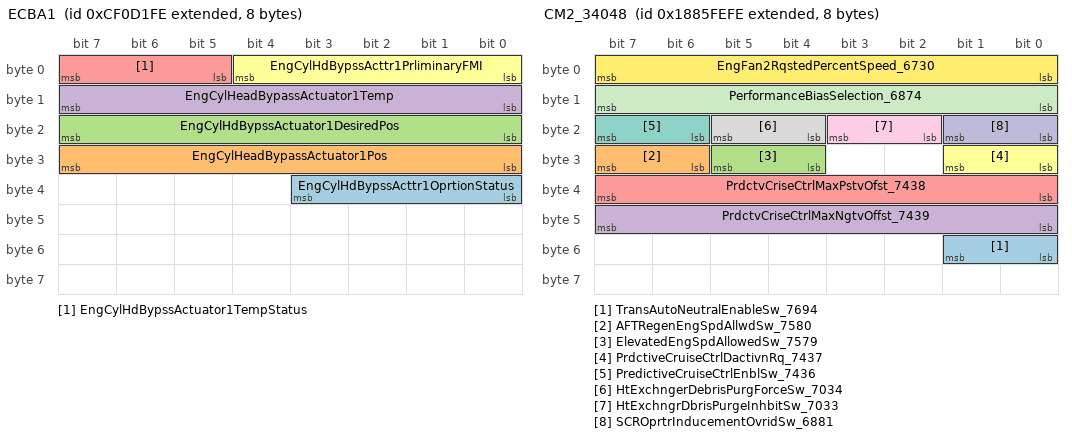
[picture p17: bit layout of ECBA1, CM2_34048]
BO_ 2364592638 ECBA1: 8 Vector__XXX
 SG_ EngCylHdBypssActtr1OprtionStatus : 32|4@1+ (1,0) [0.0|15.0] "" Vector__XXX
 SG_ EngCylHeadBypassActuator1Pos : 24|8@1+ (0.4,0) [0.0|100.0] "%" Vector__XXX
 SG_ EngCylHdBypssActuator1DesiredPos : 16|8@1+ (0.4,0) [0.0|100.0] "%" Vector__XXX
 SG_ EngCylHeadBypassActuator1Temp : 8|8@1+ (1,-40) [-40.0|210.0] "°C" Vector__XXX
 SG_ EngCylHdBypssActuator1TempStatus : 5|3@1+ (1,0) [0.0|7.0] "" Vector__XXX
 SG_ EngCylHdBypssActtr1PrliminaryFMI : 0|5@1+ (1,0) [0.0|31.0] "" Vector__XXX

BO_ 2364592382 ECCR: 8 Vector__XXX
 SG_ EngCyl24ExcludeFromCombustionRq : 54|2@1+ (1,0) [0.0|3.0] "" Vector__XXX
 SG_ EngCyl23ExcludeFromCombustionRq : 52|2@1+ (1,0) [0.0|3.0] "" Vector__XXX
 SG_ EngCyl22ExcludeFromCombustionRq : 50|2@1+ (1,0) [0.0|3.0] "" Vector__XXX
 SG_ EngCyl21ExcludeFromCombustionRq : 48|2@1+ (1,0) [0.0|3.0] "" Vector__XXX
 SG_ EngCyl20ExcludeFromCombustionRq : 46|2@1+ (1,0) [0.0|3.0] "" Vector__XXX
 SG_ EngCyl19ExcludeFromCombustionRq : 44|2@1+ (1,0) [0.0|3.0] "" Vector__XXX
 SG_ EngCyl18ExcludeFromCombustionRq : 42|2@1+ (1,0) [0.0|3.0] "" Vector__XXX
 SG_ EngCyl17ExcludeFromCombustionRq : 40|2@1+ (1,0) [0.0|3.0] "" Vector__XXX
 SG_ EngCyl16ExcludeFromCombustionRq : 38|2@1+ (1,0) [0.0|3.0] "" Vector__XXX
 SG_ EngCyl15ExcludeFromCombustionRq : 36|2@1+ (1,0) [0.0|3.0] "" Vector__XXX
 SG_ EngCyl14ExcludeFromCombustionRq : 34|2@1+ (1,0) [0.0|3.0] "" Vector__XXX
 SG_ EngCyl13ExcludeFromCombustionRq : 32|2@1+ (1,0) [0.0|3.0] "" Vector__XXX
 SG_ EngCyl12ExcludeFromCombustionRq : 30|2@1+ (1,0) [0.0|3.0] "" Vector__XXX
 SG_ EngCyl11ExcludeFromCombustionRq : 28|2@1+ (1,0) [0.0|3.0] "" Vector__XXX
 SG_ EngCyl10ExcludeFromCombustionRq : 26|2@1+ (1,0) [0.0|3.0] "" Vector__XXX
 SG_ EngCyl9ExcludeFromCombustionRq : 24|2@1+ (1,0) [0.0|3.0] "" Vector__XXX
 SG_ EngCyl8ExcludeFromCombustionRq : 22|2@1+ (1,0) [0.0|3.0] "" Vector__XXX
 SG_ EngCyl7ExcludeFromCombustionRq : 20|2@1+ (1,0) [0.0|3.0] "" Vector__XXX
 SG_ EngCyl6ExcludeFromCombustionRq : 18|2@1+ (1,0) [0.0|3.0] "" Vector__XXX
 SG_ EngCyl5ExcludeFromCombustionRq : 16|2@1+ (1,0) [0.0|3.0] "" Vector__XXX
 SG_ EngCyl4ExcludeFromCombustionRq : 14|2@1+ (1,0) [0.0|3.0] "" Vector__XXX
 SG_ EngCyl3ExcludeFromCombustionRq : 12|2@1+ (1,0) [0.0|3.0] "" Vector__XXX
 SG_ EngCyl2ExcludeFromCombustionRq : 10|2@1+ (1,0) [0.0|3.0] "" Vector__XXX
 SG_ EngCyl1ExcludeFromCombustionRq : 8|2@1+ (1,0) [0.0|3.0] "" Vector__XXX
 SG_ NmbrOfEngCylndrsTExcldFrmCmbston : 0|8@1+ (1,0) [0.0|24.0] "" Vector__XXX

BO_ 2364567294 FPAC: 8 Vector__XXX
 SG_ EngFlInjctnPump2FuelCtrlValveCmd : 16|16@1+ (0.0025,0) [0.0|100.0] "%" Vector__XXX
 SG_ EngFlInjctnPump1FuelCtrlValveCmd : 0|16@1+ (0.0025,0) [0.0|100.0] "%" Vector__XXX

BO_ 2558918398 CM2_34048: 8 Vector__XXX
 SG_ TransAutoNeutralEnableSw_7694 : 48|2@1+ (1,0) [0.0|3.0] "" Vector__XXX
 SG_ AFTRegenEngSpdAllwdSw_7580 : 30|2@1+ (1,0) [0.0|3.0] "" Vector__XXX
 SG_ ElevatedEngSpdAllowedSw_7579 : 28|2@1+ (1,0) [0.0|3.0] "" Vector__XXX
 SG_ PrdctvCriseCtrlMaxNgtvOffst_7439 : 40|8@1+ (0.125,-31.25) [-31.25|0.0] "km/h" Vector__XXX
 SG_ PrdctvCriseCtrlMaxPstvOfst_7438 : 32|8@1+ (0.125,0) [0.0|31.25] "km/h" Vector__XXX
 SG_ PrdctiveCruiseCtrlDactivnRq_7437 : 24|2@1+ (1,0) [0.0|3.0] "" Vector__XXX
 SG_ PredictiveCruiseCtrlEnblSw_7436 : 22|2@1+ (1,0) [0.0|3.0] "" Vector__XXX
 SG_ HtExchngerDebrisPurgForceSw_7034 : 20|2@1+ (1,0) [0.0|3.0] "" Vector__XXX
 SG_ HtExchngrDbrisPurgeInhbitSw_7033 : 18|2@1+ (1,0) [0.0|3.0] "" Vector__XXX
 SG_ SCROprtrInducementOvridSw_6881 : 16|2@1+ (1,0) [0.0|3.0] "" Vector__XXX
 SG_ PerformanceBiasSelection_6874 : 8|8@1+ (0.4,0) [0.0|100.0] "%" Vector__XXX
 SG_ EngFan2RqstedPercentSpeed_6730 : 0|8@1+ (0.4,0) [0.0|100.0] "%" Vector__XXX

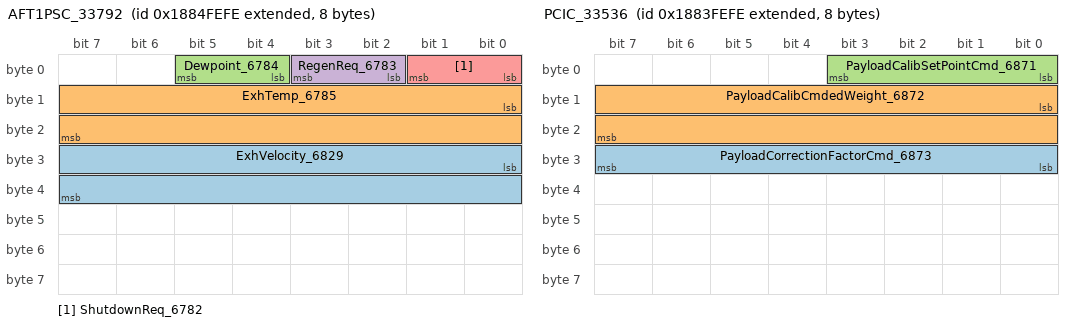
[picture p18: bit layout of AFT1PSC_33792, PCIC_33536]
BO_ 2558852862 AFT1PSC_33792: 8 Vector__XXX
 SG_ ExhVelocity_6829 : 24|16@1+ (0.00390625,0) [0.0|250.996] "km/h" Vector__XXX
 SG_ ExhTemp_6785 : 8|16@1+ (0.03125,-273) [-273.0|1734.96875] "°C" Vector__XXX
 SG_ Dewpoint_6784 : 4|2@1+ (1,0) [0.0|3.0] "" Vector__XXX
 SG_ RegenReq_6783 : 2|2@1+ (1,0) [0.0|3.0] "" Vector__XXX
 SG_ ShutdownReq_6782 : 0|2@1+ (1,0) [0.0|3.0] "" Vector__XXX

BO_ 2558787326 PCIC_33536: 8 Vector__XXX
 SG_ PayloadCorrectionFactorCmd_6873 : 24|8@1+ (1,-125) [-125.0|125.0] "%" Vector__XXX
 SG_ PayloadCalibCmdedWeight_6872 : 8|16@1+ (2,0) [0.0|128510.0] "kg" Vector__XXX
 SG_ PayloadCalibSetPointCmd_6871 : 0|4@1+ (1,0) [0.0|15.0] "" Vector__XXX

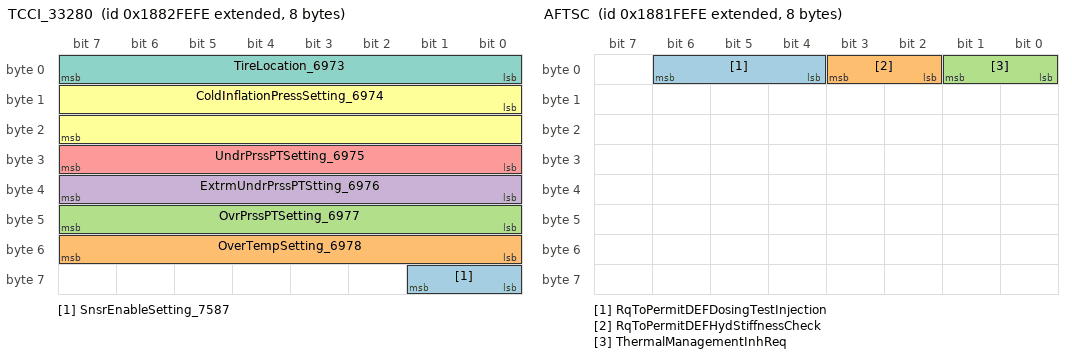
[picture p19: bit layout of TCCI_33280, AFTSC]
BO_ 2558721790 TCCI_33280: 8 Vector__XXX
 SG_ SnsrEnableSetting_7587 : 56|2@1+ (1,0) [0.0|3.0] "" Vector__XXX
 SG_ OverTempSetting_6978 : 48|8@1+ (1,-40) [-40.0|210.0] "°C" Vector__XXX
 SG_ OvrPrssPTSetting_6977 : 40|8@1+ (0.5,0) [0.0|125.0] "%" Vector__XXX
 SG_ ExtrmUndrPrssPTStting_6976 : 32|8@1+ (0.5,0) [0.0|125.0] "%" Vector__XXX
 SG_ UndrPrssPTSetting_6975 : 24|8@1+ (0.5,0) [0.0|125.0] "%" Vector__XXX
 SG_ ColdInflationPressSetting_6974 : 8|16@1+ (1,0) [0.0|64255.0] "kPa" Vector__XXX
 SG_ TireLocation_6973 : 0|8@1+ (1,0) [0.0|0.0] "" Vector__XXX

BO_ 2558656254 AFTSC: 8 Vector__XXX
 SG_ RqToPermitDEFDosingTestInjection : 4|3@1+ (1,0) [0.0|7.0] "" Vector__XXX
 SG_ RqToPermitDEFHydStiffnessCheck : 2|2@1+ (1,0) [0.0|3.0] "" Vector__XXX
 SG_ ThermalManagementInhReq : 0|2@1+ (1,0) [0.0|3.0] "" Vector__XXX

CM_ BO_ 2566687742  "Aftertreatment 1 Particulate Sensor Information 2
This message contains information for the particulate sensor in bank 1 of a 2 bank system or the particulate sensor in a single bank system.
This sensor is downstream of the DPF.";
CM_ BO_ 2365348350  "Engine Load Sharing Information
This PGN contains information relating to integrated engine load sharing status values.";
CM_ BO_ 2566674686  "Turbocharger Information 7
Turbocharger Information";
CM_ BO_ 2566674430  "SCR Operator Inducement Information 1
Contains timers that indicate how long specific causes for inducement have been active.";
CM_ BO_ 2566674174  "SCR Operator Inducement Information 2
Contains parameters that are related to SCR inducement.";
CM_ BO_ 2566673406  "Engine Gaseous Leakage Information
Used to transmit the gaseous fuel leakage information determined by the engine monitoring system.";
CM_ BO_ 2633782014  "Bin Weight and Lift Count
Used to transmit bin weights.
Note:  This PGN is transmitted for as many Bin Instances as exist on the vehicle.";
CM_ BO_ 2365346302  "Air Suspension Control 7
Used for suspension control information";
CM_ BO_ 2566672638  "Payload System Status
Status Information for Payload Measurement Systems.
This provides the last haul cycle payload information to the operator.";
CM_ BO_ 2566672382  "Payload Weight Sensor Information
Staus Information on each Payload sensor in a payload measurement system";
CM_ BO_ 2566672126  "Aftertreatment 1 SCR Dosing System Information 3
This message contains additional  SCR dosing system information for aftertreatment system 1 (or bank 1).";
CM_ BO_ 2566671870  "Aftertreatment 2 SCR Dosing System Information 3
This message contains additional  SCR dosing system information for aftertreatment system 2 (or bank 2).";
CM_ BO_ 2566671614  "SCR Operator Inducement Information 3
Contains parameters related to overriding the operator inducement.";
CM_ BO_ 2566671358  "Electronic Engine Controller 17
This message includes some parameters that are used to support PEMS.
Manufacturers that support this PGN shall support both PEMS Engine Fuel Mass Flow Rate (SPN 6893) and Vehicle Fuel Rate (SPN 6894) even if the ...";
CM_ BO_ 2566671102  "SCR System Cleaning
Contains information about cleaning the SCR system in the aftertreatment system.
If there are aftertreatment systems on two banks, this PGN represents the composite information from both banks.
NOTE: This message will be ...";
CM_ BO_ 2566670846  "Aftertreatment 1 Historical Information 2
Contains information about the history of the aftertreatment 1 system";
CM_ BO_ 2566670590  "Aftertreatment 2 Historical Information 2
Contains information about the history of the aftertreatment 2 system";
CM_ BO_ 2566670334  "Monitored Tire Information
Used by the tire monitoring system to report the number of tires, number of axles and number of tires on each axle it is monitoring on a specific vehicle. The axle number increments from front to rear of the vehicle per ...";
CM_ BO_ 2566670078  "Tire Sensor Identification Status
The tire sensor identification number for each monitored tire.
Since there are multiple tire sensors to report, the message format will be a,b,c,d,b,c,d,b,c,d,b,c,d,...etc. where
a = Number of Tire Sensors
b = ...";
CM_ BO_ 2566669822  "Tire Wireless Signal Strength Indicator
The tire wireless signal strength indicator for each monitored tire. If there are multiple tire sensors with multiple antennas to report, the message format will be ...";
CM_ BO_ 2566669310  "Tire Configuration Status Information
Details the attributes for the tire monitoring configuration status of the tires.
NOTE – Multiple instances of this message will be required to transmit data for all tire locations.  When reporting data for ...";
CM_ BO_ 2566669054  "Tire Condition Message 2
Tire Condition Message 2
NOTE – Multiple instances of this message will be required to transmit data for all tire locations.  When reporting data for multiple tire locations, each successive message, which provides data ...";
CM_ BO_ 2566668798  "Alternate Fuel 4";
CM_ BO_ 2566668542  "Engine Hydraulic Fuel 2 Pump Status
Hydraulically driven engine fuel 2 pump messages.";
CM_ BO_ 2566668286  "Engine Turbocharger Control 2
This PGN contains information on turbocharger commands.";
CM_ BO_ 2566668030  "Heat Exchanger Debris Purge Information
Contains information about purging debris from the heat exchanger.";
CM_ BO_ 2566667774  "Engine End Bearing Temperature 1
Used to transmit temperature values at end bearings for connecting rods in the engine cylinder";
CM_ BO_ 2566667518  "Engine End Bearing Temperature 2
Used to transmit temperature values at end bearings for connecting rods in the engine cylinder";
CM_ BO_ 2566667262  "Engine End Bearing Temperature 3
Used to transmit temperature values at end bearings for connecting rods in the engine cylinder";
CM_ BO_ 2499558142  "Gaseous Fuel Supply Pressure 1
Used to transmit information on pressures at various points of Gaseous fuel supplied to the engine.";
CM_ BO_ 2499557886  "Gaseous Fuel Supply Pressure 2
Used to transmit information on pressures at various points of Gaseous fuel supplied to the engine.";
CM_ BO_ 2499557630  "Engine Oil Mist Detection Information 1
Used to transmit oil mist information determined by the engine monitoring system";
CM_ BO_ 2499557374  "Engine Oil Mist Detection Information 2
Used to transmit oil mist information determined by the engine monitoring system";
CM_ BO_ 2499557118  "Gaseous Fuel Supply Valve Information
Used to transmit information on valves on the gaseous fuel supply lines.";
CM_ BO_ 2566665726  "Aftertreatment 2 Diesel Exhaust Fluid Pump 1 Information
Contains information on diesel exhaust fluid pumps for aftertreatment system 2.";
CM_ BO_ 2499556606  "Engine Fuel Injector Metering Rail Pressure Information 2
Transmits the rail pressure information as measured by different rail pressure sensors.";
CM_ BO_ 2499556350  "Engine Fuel Injector Metering Rail Pressure Information 3
Transmits rail pressure information.";
CM_ BO_ 2499556094  "Aftertreatment 1 Particulate Sensor Information 3
This message contains information for the particulate sensor in bank 1 of a 2 bank system or the particulate sensor in a single bank system.";
CM_ BO_ 2566664702  "Aftertreatment System Information
The state of the aftertreatment system.";
CM_ BO_ 2633773310  "SCR Operator Inducement Information 4
Contains parameters that are related to SCR inducement.";
CM_ BO_ 2633773054  "Fire Suppression Agent Status
Represents the status of various agents used for fire
suppression and solutions.";
CM_ BO_ 2566663934  "Engine Turbocharger Control 3
Contains command signals to Turbocharger Compressor Blowoff, Wastegate, Cylinder Head Bypass
and Throttle Valve actuators.";
CM_ BO_ 2566663678  "Alternate Fuel 5
Information on alternate fuel.";
CM_ BO_ 2566663422  "Brake Caliper Lining Clearance
Refers to disc brake caliper lining clearance condition.";
CM_ BO_ 2566663166  "Cruise Control / Vehicle Speed 4
Cruise Control / Vehicle Speed 4";
CM_ BO_ 2566662910  "Operator Inducement Information
Contains parameters related to operator inducement.";
CM_ BO_ 2566662654  "Forward Lane Image 3
Forward Lane Image message 3 for computing results outside the optical sensor (e.g., data fusion)";
CM_ BO_ 2566662142  "Aftertreatment 1 Diesel Exhaust Fluid Information 2
Sensor Information which measures temperature, concentration, and conductivity of the diesel exhaust fluid of the aftertreatment 1 system.";
CM_ BO_ 2566661630  "Aftertreatment 1 Diesel Exhaust Fluid Tank 1 Information 2
Contains information on various tank levels";
CM_ BO_ 2566661374  "Aftertreatment 2 Diesel Exhaust Fluid Tank 1 Information 2
This message contains diesel exhaust fluid tank 1 information for aftertreatment system 2 (or bank 2).  The first tank for the aftertreatment sytem is primary reagent storage tank.";
CM_ BO_ 2364598270  "Engine Ignition Timing Offset 3
This PGN contains timing offsets for cylinders 17-24.
These timing offsets are relative to the commanded engine timing advance (SPN 7355).";
CM_ BO_ 2364598014  "Engine Ignition Timing Offset 2
This PGN contains timing offsets for cylinders 9-16.
These timing offsets are relative to the commanded engine timing advance (SPN 7355).";
CM_ BO_ 2364597758  "Engine Ignition Timing Offset 1
This PGN contains timing offsets for cylinders 1-8.
These timing offsets are relative to the commanded engine timing advance (SPN 7355).";
CM_ BO_ 2364593150  "Predictive Cruise Control 1
Contains parameters related to predictive cruise control. Predictive cruise control is the process of varying the set point used by the cruise control algorithm based on external factors (e.g., anticipated road grade).";
CM_ BO_ 2364592894  "Engine Electronic Controller 18
Transmits command information for the actuators associated with engine.";
CM_ BO_ 2364592638  "Engine Cylinder Head Bypass Actuator 1
Transmits information about Engine Cylinder Head Bypass Actuator. The cylinder head bypass
valve is used to release the air at the high pressure compressor outlet into turbocharger turbine inlet
when intake ...";
CM_ BO_ 2364592382  "Engine Cylinder Combustion Request
Transmits combustion related requests";
CM_ BO_ 2364567294  "Fuel Pump Actuator Control Command
Used to transmit the commanded % position for the Fuel Pump control valve.";
CM_ BO_ 2558918398  "Cab Message 2 - Message containing parameters originating from the vehicle cab.";
CM_ BO_ 2558852862  "Aftertreatment 1 Particulate Sensor Control - This PGN contains parameters used to control the particulate sensor and to provide data that the particulate sensor needs to operate.";
CM_ BO_ 2558787326  "Payload Calibration Information Command - Calibration setting commands for the Payload Measurement System.";
CM_ BO_ 2558721790  "Tire Configuration Command Information - Details the attributes for the tire monitoring settings for the tires.";
CM_ BO_ 2558656254  "Aftertreatment System Control
Used to request the aftertreatment system to perform or inhibit certain operations.";
CM_ SG_ 2566687742 HtrRes "The resistance of the particulate sensor heater.";
CM_ SG_ 2566687742 MaxRes "This is the maximum resistance that the particulate sensor can measure.";
CM_ SG_ 2566687742 Temp "Temperature of the particulate sensor.";
CM_ SG_ 2566687742 RegenFailedCount "This is the number of times that the particulate sensor regeneration process has been attempted but failed to complete this power cycle.";
CM_ SG_ 2566687742 PwrSupply "State signal which indicates when the Aftertreatment 1 particulate sensor has power applied to it. Note that this is referring to the power supplied to the sensor, not the power supplied to the controller connected to the sensor.
00 - Off
01 - On
...";
CM_ SG_ 2566687742 DetectionStatus "Detection status of the particulate sensor
0000 - Initialization for particulate matter detection
0001 - Waiting for dew point (see SPN 6784)
0010 - Particulate matter detection
0011 - Heater is active for particulate sensor regeneration
0100 - ...";
CM_ SG_ 2365348350 EngLoadShareStatus "This signal indicates that the status of an engine load sharing feature.
0000 - Offline
0001 - Master
0010 - Slave
0011 - Loading
0100 - Unloading
0101 -1101 - Reserved
1110 - Error
1111 - Unavailable";
CM_ SG_ 2365348350 EngUnloadStatus "This signal indicates the status of an external request to unload the engine, such as the external unload request switch.
00 - Not Requested
01 - Requested
10 - Error
11 - Not Available";
CM_ SG_ 2566674686 EngTurbo4LubeOilPress "Gage pressure of oil in the lubrication system for the 4th turbocharger.";
CM_ SG_ 2566674686 EngTurbo3LubeOilPress "Gage pressure of oil in the lubrication system for the 3rd turbocharger.";
CM_ SG_ 2566674686 EngTurbo2LubeOilPress "Gage pressure of oil in the lubrication system for the 2nd turbocharger.";
CM_ SG_ 2566674430 DslExhstFldQalityMalfunctionTime "Indicates the amount of time an error has been active due to detection of low Diesel Exhaust Fluid Quality. This will accumulate over the life of the product and will never be reset.";
CM_ SG_ 2566674430 DieselExhaustFluidTank1EmptyTime "Indicates the time the Diesel Exhaust Fluid Tank 1 Level is indicated as empty. This will accumulate over the life of the product and will never be reset.";
CM_ SG_ 2566674174 SCROperatorInducementTotalTime "Indicates the time that operator inducement has been active. This will accumulate over the life of the product and will never be reset.";
CM_ SG_ 2566674174 AFTSCRMalfunctionTime "Indicates the amount of time an error condition has been active due to a malfunction in the Aftertreatment SCR system.
The source of the malfunction condition could be a component failure, detection of tampering, or other reason that prevents ...";
CM_ SG_ 2566673406 GasLeakageDetection3Press "Pressure measured in gas leakage detection point 3. Measured media is of the gas, meaning it could be air, inert gas, fuel air mixture or charge air mixture, depending on the failure mode detected. The third measurement point is in a separate leak ...";
CM_ SG_ 2566673406 GasLeakageDetection2Press "Pressure measured in gas leakage detection point 2. Measured media is of the gas, meaning it could be air, inert gas, fuel air mixture or charge air mixture, depending on the failure mode detected. The second measurement point is either another ...";
CM_ SG_ 2566673406 GasLeakageDetection1Press "Pressure measured in gas leakage detection point 1. Measured media is of the gas, meaning it could be air, inert gas, fuel air mixture or charge air mixture, depending on the failure mode detected. The measurement point is typically in the engine ...";
CM_ SG_ 2566673406 GasFuelLeakage3Concentration "Percentage of detected gaseous fuel leak compared to the lower explosion limit (LEL). 100% means the measured value is on the lower explosion limit. 0% means no detected gaseous fuel in measurement point. The third measurement point is in a separate ...";
CM_ SG_ 2566673406 GasFuelLeakage2Concentration "Percentage of detected gaseous fuel leak compared to the lower explosion limit (LEL). 100% means the measured value is on the lower explosion limit. 0% means no detected gaseous fuel in measurement point. The second  measurement point is either ...";
CM_ SG_ 2566673406 GasFuelLeakage1Concentration "Percentage of detected gaseous fuel leak compared to the lower explosion limit (LEL). 100% means the measured value is on the lower explosion limit. 0% means no detected gaseous fuel in measurement point. The measurement point is typically in the ...";
CM_ SG_ 2633782014 NetBinWeight "Mass of bin contents at most recent unload";
CM_ SG_ 2633782014 BinLiftCount "Increments with each lift, whether or not net bin weight changes.  The count rolls over at data range limit.
The count can be reset using SPN 6898 in PGN 56832.";
CM_ SG_ 2633782014 BinWeighingErrorStatus "Bin weighing error status
0 = No error
1 = Bad lift cycle
2 = Weighing error: bin lifted, not emptied
3 = Weighing error: empty bin lifted, emptied
4 - 14 = Reserved
15 = Not available / not applicable";
CM_ SG_ 2633782014 BinInstance "Gives the instance of the bin on the vehicle whose parameters are transmitted in the remainder of the PGN, with the first or only bin as instance 1.";
CM_ SG_ 2365346302 LiftAxle2Status "Indicates the status of a tag axle 2.  Numbering of lift/tag axles starts at front axle.  SPN 1822 may be used if less detail is acceptable.
000 - Down (tag axle is laden)
001 - Unloading (load is being transferred from the tag axle)
010 - ...";
CM_ SG_ 2365346302 LiftAxle1Status "Indicates the status of a tag axle 1.  Numbering of lift/tag axles starts at front axle.  SPN 1743 may be used if less detail is acceptable.
000 - Down (tag axle is laden)
001 - Unloading (load is being transferred from the tag axle)
010 - ...";
CM_ SG_ 2566672638 DeliveryTransactionStatus "The current state of the payload delivery transaction.
When a transaction is in progress, a receiving node may monitor Haul Cycle Count (SPN 6847) and Delivered Payload Weight (SPN 6849) in order to track the progress of a transaction, where the ...";
CM_ SG_ 2566672638 DeliveredPayloadConfidence "The level of confidence of the delivered payload weight measurement. Higher confidence values indicate greater probability the delivered payload weight is the actual weight and providing feedback on the potential for improving system accuracy.";
CM_ SG_ 2566672638 DeliveredPayloadWeight "The delivered payload mass during the last haul cycle. This is the amount of material moved and delivered by a machine is a key work cycle parameter.
Delivered payload weight is defined as the last loaded weight less the carry back weight (material ...";
CM_ SG_ 2566672638 HaulModeStatus "The current operating state of the haul cycle.
0000 - Not in Haul Mode
0001 - Loading -- Payload is being added to the machine
0010 - Approaching Loaded -- Machine is near its maximum capacity
0011 - Loaded -- Loading operation has been ...";
CM_ SG_ 2566672638 HaulCycleCount "A counter incremented by 1 with each instance of a new haul cycle, defined as a dump to dump cycle. The counter shall increment from 0 to 64255, rolling over to 0 on the next increment after 64255.";
CM_ SG_ 2566672382 PayloadWeightSensor8Status "Status of the payload system sensor 8 measurement.
00 = Sensor fully functional
01 = Sensor degraded
10 = Error (Sensor failed)
11 = Not available";
CM_ SG_ 2566672382 PayloadWeightSensor7Status "Status of the payload system sensor 7 measurement.
00 = Sensor fully functional
01 = Sensor degraded
10 = Error (Sensor failed)
11 = Not available";
CM_ SG_ 2566672382 PayloadWeightSensor6Status "Status of the payload system sensor 6 measurement.
00 = Sensor fully functional
01 = Sensor degraded
10 = Error (Sensor failed)
11 = Not available";
CM_ SG_ 2566672382 PayloadWeightSensor5Status "Status of the payload system sensor 5 measurement.
00 = Sensor fully functional
01 = Sensor degraded
10 = Error (Sensor failed)
11 = Not available";
CM_ SG_ 2566672382 PayloadWeightSensor4Status "Status of the payload system sensor 4 measurement.
00 = Sensor fully functional
01 = Sensor degraded
10 = Error (Sensor failed)
11 = Not available";
CM_ SG_ 2566672382 PayloadWeightSensor3Status "Status of the payload system sensor 3 measurement.
00 = Sensor fully functional
01 = Sensor degraded
10 = Error (Sensor failed)
11 = Not available";
CM_ SG_ 2566672382 PayloadWeightSensor2Status "Status of the payload system sensor 2 measurement.
00 = Sensor fully functional
01 = Sensor degraded
10 = Error (Sensor failed)
11 = Not available";
CM_ SG_ 2566672382 PayloadWeightSensor1Status "Status of the payload system sensor 1 measurement.
00 = Sensor fully functional
01 = Sensor degraded
10 = Error (Sensor failed)
11 = Not available";
CM_ SG_ 2566672126 DEFDoser2Temp "The temperature (measured closest to dosing valve) of the second DEF dosing unit for aftertreatment system 1 (exhaust bank 1).";
CM_ SG_ 2566672126 DEFDoser2AbsPress "The SCR doser 2 diesel exhaust fluid absolute pressure (measured closest to dosing valve) for aftertreatment system 1 (exhaust bank 1).";
CM_ SG_ 2566672126 DEFDosingPress "The SCR dosing diesel exhaust fluid gage pressure (measured closest to dosing valve) for aftertreatment system 1 (exhaust bank 1). This is the gage equivalent to SPN 4334.";
CM_ SG_ 2566671870 DEFDosing2Temp "The temperature (measured closest to dosing valve) of the second DEF dosing unit for aftertreatment system 2 (exhaust bank 2).";
CM_ SG_ 2566671870 DEFDoser2AbsPress "The SCR doser 2 diesel exhaust fluid absolute pressure (measured closest to dosing valve) for aftertreatment system 2 (exhaust bank 2).";
CM_ SG_ 2566671870 DEFDosingPress "The SCR dosing diesel exhaust fluid gage pressure (measured closest to dosing valve) for aftertreatment system 2 (exhaust bank 2). This is the gage equivalent to SPN 4387.";
CM_ SG_ 2566671614 TtlNmbrOfSCROprtrIndcmntOvrrdEvn "Indicates total number of operator inducement override events activated throughout the lifetime of engine operation.
This number will remain at the maximum value once it is reached.
See EU Commission directive 2012/46/EU. Appendix 1 Section 5.5 ...";
CM_ SG_ 2566671614 NmbrOfSCROprtrIndcmntOvrrdEvntsR "During an operator inducement event, the operator may be able to override the inducement multiple times. This parameter indicates the remaining number of times that the currently active inducement can be overridden during an operator inducement ...";
CM_ SG_ 2566671614 SCROprtrIndcmntOvrrdTmeRemaining "This parameter is used to indicate the time remaining during an operator inducement override event.  See also SPN 7344 for an alternate SLOT.
When an operator inducement is not active, this parameter indicates the maximum time that an operator ...";
CM_ SG_ 2566671614 SCROprtrInducementOverrideEnable "Indicates if an operator inducement derate is allowed to be overridden.
Note: Inducement override is only allowed under certain conditions approved by EPA/ARB.
00 Override not allowed
01 Override allowed
10 SAE Reserved
11 Not available";
CM_ SG_ 2566671358 CylFuelRate "Cylinder fuel rate shall indicate the amount of fuel injected into the cylinder for combustion during the most recent intake stroke of the engine.
NOTE: Cylinder fuel rate shall indicate zero mg/stroke when the engine is not running.";
CM_ SG_ 2566671358 EngExhaustFlowRate "Engine Exhaust Flow Rate shall indicate the measured/calculated exhaust gas mass flow upstream of the aftertreatment system.
Engine Exhaust Flow Rate shall be calculated as the average exhaust flow rate over the last 1000 milliseconds prior to the ...";
CM_ SG_ 2566671358 VehicleFuelRate "Vehicle Fuel Rate shall indicate the amount of fuel consumed by the engine and fuel injected directly into the aftertreatment system per unit of time, in grams per second.
Vehicle Fuel Rate shall be calculated as the sum of the fuel consumed over ...";
CM_ SG_ 2566671358 PEMSEngFuelMassFlowRate "PEMS Engine Fuel Mass Flow Rate shall indicate the amount of fuel consumed by the engine per unit of time (does not include fuel injected directly into the aftertreatment system, but does include fuel injected into the engine cylinders for the ...";
CM_ SG_ 2566671102 SCRSystemCleaningForcedStatus "Indicates the forced execution status of SCR system cleaning.
000 Not Active
001 Active - Forced by Switch (See SPN 3696)
010 Active - Forced by Service Tool
011 Reserved for SAE Assignment
100 Reserved for SAE Assignment
101 Reserved for SAE ...";
CM_ SG_ 2566671102 SCRSystmClnngAtmtcIntationConfig "Indicates the configuration of SCR system cleaning automatic initiation.
00 not enabled
01 enabled
10 reserved for SAE assignment
11 not available";
CM_ SG_ 2566671102 SCRSystmClnngInhbtdDTVhclSpdBlwA "Indicates the state of SCR system cleaning inhibition due to the vehicle speed being less than the allowed vehicle speed.
00 not inhibited
01 inhibited
10 reserved for SAE assignment
11 not available
This SPN indicates the reason for the SCR ...";
CM_ SG_ 2566671102 SCRSystmClnngInhbtdDTEngNtWrmdUp "Indicates the state of SCR system cleaning inhibition due to the engine not being warmed up.
00 not inhibited
01 inhibited
10 reserved for SAE assignment
11 not available
This SPN indicates the reason for the SCR system cleaning event not being ...";
CM_ SG_ 2566671102 SCRSystmClnngInhbtdDTPrmnntSystm "Indicates the state of SCR system cleaning inhibition due to a permanent system lockout.
00 not inhibited
01 inhibited
10 reserved for SAE assignment
11 not available
This SPN indicates the reason for the SCR system cleaning event not being ...";
CM_ SG_ 2566671102 SCRSystmClnngInhbtdDTTmprrySystm "Indicates the state of SCR system cleaning inhibition due to a temporary system lockout.
00 not inhibited
01 inhibited
10 reserved for SAE assignment
11 not available
This SPN indicates the reason for the SCR system cleaning event not being ...";
CM_ SG_ 2566671102 SCRSystmClnngInhbtdDTSystmTmeout "Indicates the state of SCR system cleaning inhibition due to a system timeout.
00 not inhibited
01 inhibited
10 reserved for SAE assignment
11 not available
This SPN indicates the reason for the SCR system cleaning event not being initiated or ...";
CM_ SG_ 2566671102 SCRSystmClnngInhbtdDTSystmFltAct "Indicates the state of SCR system cleaning inhibition due to a system fault being active.
00 not inhibited
01 inhibited
10 reserved for SAE assignment
11 not available
This SPN indicates the reason for the SCR system cleaning event not being ...";
CM_ SG_ 2566671102 SCRSystmClnngInhbtdDTLwExhstTemp "Indicates the state of SCR system cleaning inhibition due to the exhaust temperature being too low.  This implies that the SCR system is too cold for cleaning.
00 not inhibited
01 inhibited
10 reserved for SAE assignment
11 not available
This ...";
CM_ SG_ 2566671102 SCRSystmClnngInhbtdDTPrkngBrkNtS "Indicates the state of SCR system cleaning inhibition due to the parking brake being not set.
00 not inhibited
01 inhibited
10 reserved for SAE assignment
11 not available
This SPN indicates the reason for the SCR system cleaning event not ...";
CM_ SG_ 2566671102 SCRSystmClnngInhbtdDTVhclSpdAbvA "Indicates the state of SCR system cleaning inhibition due to the vehicle speed being above an allowed limit.
00 not inhibited
01 inhibited
10 reserved for SAE assignment
11 not available
This SPN indicates the reason for the SCR system cleaning ...";
CM_ SG_ 2566671102 SCRSystmClnngInhbtdDTOtOfNeutral "Indicates the state of SCR system cleaning inhibition due to the accelerator pedal being out of neutral.
00 not inhibited
01 inhibited
10 reserved for SAE assignment
11 not available
This SPN indicates the reason for the SCR system cleaning ...";
CM_ SG_ 2566671102 SCRSystmClnngInhbtdDTAcclPdlOffI "Indicates the state of SCR system cleaning inhibition due to the accelerator pedal being off idle.
00 not inhibited
01 inhibited
10 reserved for SAE assignment
11 not available
This SPN indicates the reason for the SCR system cleaning event not ...";
CM_ SG_ 2566671102 SCRSystmClnngInhbtdDeToPTOActive "Indicates the state of SCR system cleaning inhibition due to the PTO being active.
00 not inhibited
01 inhibited
10 reserved for SAE assignment
11 not available
This SPN indicates the reason for the SCR system cleaning event not being initiated ...";
CM_ SG_ 2566671102 SCRSystmClnngInhbtdDTSrvcBrkActv "Indicates the state of SCR system cleaning inhibition due to the service brake being active.
00 not inhibited
01 inhibited
10 reserved for SAE assignment
11 not available
This SPN indicates the reason for the SCR system cleaning event not being ...";
CM_ SG_ 2566671102 SCRSystmClnngInhbtdDTCltchDsnggd "Indicates the state of SCR system cleaning event inhibition due to the clutch being disengaged.
00 not inhibited
01 inhibited
10 reserved for SAE assignment
11 not available
This SPN indicates the reason for the SCR system cleaning event not ...";
CM_ SG_ 2566671102 SCRSystmClnngInhbtdDTInhbtSwitch "Indicates the state of SCR system cleaning inhibition due to the SCR system cleaning Inhibit Switch.
00 not inhibited
01 inhibited
10 reserved for SAE assignment
11 not available
This SPN indicates the reason for the SCR system cleaning event ...";
CM_ SG_ 2566671102 SCRSystemCleaningInhibitedStatus "Indicates the state of SCR system cleaning inhibition.
00 not inhibited
01 inhibited
10 reserved for SAE assignment
11 not available
This SPN indicates the reason for the SCR system cleaning event not being initiated or being exited prior to ...";
CM_ SG_ 2566671102 SCRSystemCleaningStatus "Indicates the state of SCR system cleaning.  This is an aggregate of bank 1 and bank 2.  It is a system status and not individual bank status.
00 not active
01 active
10 SCR system cleaning is needed - automatically initiated SCR system cleaning ...";
CM_ SG_ 2566671102 SCRSystemCleaningLampCmd "Command to control the SCR system cleaning lamp.
000 Off
001 On - solid
010 reserved for SAE assignment
011 reserved for SAE assignment
100 On - fast blink (1 HZ)
101 reserved for SAE assignment
110 reserved for SAE assignment
111 not ...";
CM_ SG_ 2566670846 SCRSysAvgDistBetweenCleanEvents "Indicates the average distance since last reset between cleaning events for the SCR system in bank 1.
If the manufacturer allows this parameter to be reset, this distance is the average since last reset.";
CM_ SG_ 2566670846 SCRSysAvgTimeBetweenCleanEvents "Indicates the average time since last reset between cleaning events for the SCR system in bank 1.
If the manufacturer allows this parameter to be reset, this time is the average since last reset.";
CM_ SG_ 2566670846 SCRSysTotalSysCleanManReq "Total number of manual cleaning requests on the SCR system in bank 1 by the operator over the lifetime of the device.";
CM_ SG_ 2566670846 SCRSysTotalSysCleanInhReq "Total number of cleaning inhibit requests on the SCR system in bank 1 by the operator over the lifetime of the device.";
CM_ SG_ 2566670846 SCRSysTotalSysCleanEvents "Total number of cleaning events that have occurred on the SCR system in bank 1 over the lifetime of the device.";
CM_ SG_ 2566670846 SCRSysTotalCleanTime "Total amount of time that a cleaning event has been active in the SCR system in bank 1 over the lifetime of the device.";
CM_ SG_ 2566670590 SCRSysAvgDistBetweenCleanEvents "Indicates the average distance since last reset between cleaning events for the SCR system in bank 2.
If the manufacturer allows this parameter to be reset, this distance is the average since last reset.";
CM_ SG_ 2566670590 SCRSysAvgTimeBetweenCleanEvents "Indicates the average time since last reset between cleaning events for the SCR system in bank 2.
If the manufacturer allows this parameter to be reset, this time is the average since last reset.";
CM_ SG_ 2566670590 SCRSysTotalSysCleanManReq "Total number of manual cleaning requests on the SCR system in bank 2 by the operator over the lifetime of the device.";
CM_ SG_ 2566670590 SCRSysTotalSysCleanInhReq "Total number of cleaning inhibit requests on the SCR system in bank 2 by the operator over the lifetime of the device.";
CM_ SG_ 2566670590 SCRSysTotalSysCleanEvents "Total number of cleaning events that have occurred on the SCR system in bank 2 over the lifetime of the device.";
CM_ SG_ 2566670590 SCRSysTotalSysCleanTime "Total amount of time that a cleaning event has been active in the SCR system in bank 2 over the lifetime of the device.";
CM_ SG_ 2566670334 Axle12MonitoredTireCount "The number of tires on Axle 12 which are monitored by the tire monitor controller. The axle number increments from front to rear of the vehicle when facing the vehicle in the forward vehicle travel orientation. If the axle is not monitored by the ...";
CM_ SG_ 2566670334 Axle11MonitoredTireCount "The number of tires on Axle 11 which are monitored by the tire monitor controller. The axle number increments from front to rear of the vehicle when facing the vehicle in the forward vehicle travel orientation. If the axle is not monitored by the ...";
CM_ SG_ 2566670334 Axle10MonitoredTireCount "The number of tires on Axle 10 which are monitored by the tire monitor controller. The axle number increments from front to rear of the vehicle when facing the vehicle in the forward vehicle travel orientation. If the axle is not monitored by the ...";
CM_ SG_ 2566670334 Axle9MonitoredTireCount "The number of tires on Axle 9 which are monitored by the tire monitor controller. The axle number increments from front to rear of the vehicle when facing the vehicle in the forward vehicle travel orientation. If the axle is not monitored by the ...";
CM_ SG_ 2566670334 Axle8MonitoredTireCount "The number of tires on Axle 8 which are monitored by the tire monitor controller. The axle number increments from front to rear of the vehicle when facing the vehicle in the forward vehicle travel orientation. If the axle is not monitored by the ...";
CM_ SG_ 2566670334 Axle7MonitoredTireCount "The number of tires on Axle 7 which are monitored by the tire monitor controller. The axle number increments from front to rear of the vehicle when facing the vehicle in the forward vehicle travel orientation. If the axle is not monitored by the ...";
CM_ SG_ 2566670334 Axle6MonitoredTireCount "The number of tires on Axle 6 which are monitored by the tire monitor controller. The axle number increments from front to rear of the vehicle when facing the vehicle in the forward vehicle travel orientation. If the axle is not monitored by the ...";
CM_ SG_ 2566670334 Axle5MonitoredTireCount "The number of tires on Axle 5 which are monitored by the tire monitor controller. The axle number increments from front to rear of the vehicle when facing the vehicle in the forward vehicle travel orientation. If the axle is not monitored by the ...";
CM_ SG_ 2566670334 Axle4MonitoredTireCount "The number of tires on Axle 4 which are monitored by the tire monitor controller. The axle number increments from front to rear of the vehicle when facing the vehicle in the forward vehicle travel orientation. If the axle is not monitored by the ...";
CM_ SG_ 2566670334 Axle3MonitoredTireCount "The number of tires on Axle 3 which are monitored by the tire monitor controller. The axle number increments from front to rear of the vehicle when facing the vehicle in the forward vehicle travel orientation. If the axle is not monitored by the ...";
CM_ SG_ 2566670334 Axle2MonitoredTireCount "The number of tires on Axle 2 which are monitored by the tire monitor controller. The axle number increments from front to rear of the vehicle when facing the vehicle in the forward vehicle travel orientation. If the axle is not monitored by the ...";
CM_ SG_ 2566670334 Axle1MonitoredTireCount "The number of tires on Axle 1 which are monitored by the tire monitor controller. The axle number increments from front to rear of the vehicle when facing the vehicle in the forward vehicle travel orientation. If the axle is not monitored by the ...";
CM_ SG_ 2566670334 NumberOfTiresOnTheVehicle "The total number of tires monitored for tire parameters. A maximum of 250 tires is defined.";
CM_ SG_ 2566670334 NumberOfAxlesOnTheVehicle "The number of axles monitored for tire parameters. A maximum of 12 axles is defined.";
CM_ SG_ 2566670078 TireSensorIdentificationNumber "The identification number of the tire specified in the tire number (SPN 6964) or tire location (SPN 6965).";
CM_ SG_ 2566670078 TireSensorLocation "The location of monitored tire that corresponds with the Tire Sensor Identification Number (SPN 6966). In order to specify the monitored tire by tire number, use the Tire Number SPN 6964.
The high order 4 bits indicate the vehicle axle position of ...";
CM_ SG_ 2566670078 TireSensorTireNumber "The number of the monitored tire that corresponds with the Tire Sensor Identification Number (SPN 6966).  In order to specify the monitored tire by location, use the Tire Location SPN 6965.
The value 0xFF indicates this SPN is not used.";
CM_ SG_ 2566670078 NumberOfTireSensors "Total count of monitored tire sensor identification numbers represented in this instance of the parameter group.";
CM_ SG_ 2566669822 TrWrelessSignalStrengthIndicator "The wireless signal strength between the tire pressure sensor and the specified antenna, for the tire specified in the tire sensor number or tire sensor Location.";
CM_ SG_ 2566669822 TireLocation "The location of monitored tire on the vehicle.
The high order 4 bits indicate the vehicle axle position of the tire sensor, counting front to back on the vehicle, with the value 0 representing the front axle on the vehicle.
The low order 4 bits ...";
CM_ SG_ 2566669822 TireSensorNumber "The number of the monitored tire sensor that corresponds with the tire wireless signal strength indicator. The location of the numbered tire is reported in the tire sensor location SPN (SPN 6965). The value 0xFF indicates this SPN is not used.";
CM_ SG_ 2566669822 TtalNumberOfTireSensorsMonitored "Total number of tire sensors monitored for the specified antenna in this instance of the parameter group.";
CM_ SG_ 2566669822 AntennaNumber "Number of the antenna used to communicate signal strength of a group of sensors.  If a single antenna is used this will default to 0x01. When multiple antennas are used, the first antenna will have a value of 1, 2nd antenna will be 2, 3rd antenna ...";
CM_ SG_ 2566669822 TotalNumberOfAntennasUsed "Total count of antennas used in the specified vehicle system.";
CM_ SG_ 2566669310 OverTemp "The temperature above which the over temperature alert will trigger.";
CM_ SG_ 2566669310 OverPressPercentageThreshold "The percentage deviation from the set cold inflation pressure, for the over tire pressure alert.";
CM_ SG_ 2566669310 ExtrmUndrPrssPercentageThreshold "The percentage deviation from the set cold inflation pressure, for the extreme under tire pressure alert.";
CM_ SG_ 2566669310 UnderPressPercentageThreshold "The percentage deviation from the set cold inflation pressure, for the under tire pressure alert.";
CM_ SG_ 2566669310 ColdInflationPress "The cold inflation pressure of the tire. Cold inflation pressure is the default/reference inflation pressure suggested by the manufacturer for a specific tire.";
CM_ SG_ 2566669310 TireLocation "The location of monitored tire on the vehicle.
The high order 4 bits indicate the vehicle axle position of the tire sensor, counting front to back on the vehicle, with the value 0 representing the front axle on the vehicle.
The low order 4 bits ...";
CM_ SG_ 2566669054 RequiredTirePress "The required tire pressure at which air is contained in cavity formed by tire and rim.
This pressure of the tire is compensated to meet the specific physical environmental conditions (temperature) of the vehicle.";
CM_ SG_ 2566669054 TirePress "Pressure at which air is contained in cavity formed by tire and rim. See SPN 241 for alternate tire pressure with a lower range and coarser resolution.";
CM_ SG_ 2566669054 TireLocation "Identifies which tire is associated with the parametric data in PGN 64578. Refer to SPN 929 for further details and examples. The low order 4 bits represent a position number, counting left to right when facing in the direction of normal vehicle ...";
CM_ SG_ 2566668798 EngFl2InjctorMeteringRail1Press2 "The second pressure of fuel 2 measured by first rail pressure sensor in the primary, or first, metering rail as delivered from the supply pump to the injector metering intake.";
CM_ SG_ 2566668798 EngFel2InjectorMeteringRail2Temp "The temperature of fuel 2 measured by first rail temperature sensor in the metering rail 2 as delivered from the supply pump to the injector metering intake.";
CM_ SG_ 2566668798 EngFel2InjectorMeteringRail1Temp "The temperature of fuel 2 measured by first rail temperature sensor in the primary, or first, metering rail as delivered from the supply pump to the injector metering intake.";
CM_ SG_ 2566668798 EngFl2InjectorMeteringRail2Press "The pressure of fuel 2 measured by first rail pressure sensor in the metering rail 2 as delivered from the supply pump to the injector metering intake.";
CM_ SG_ 2566668798 EngFl2InjectorMeteringRail1Press "The pressure of fuel 2 measured by first rail pressure sensor in the primary, or first, metering rail as delivered from the supply pump to the injector metering intake.";
CM_ SG_ 2566668542 EngFuel2PumpHydPress "Hydraulic pressure in the lines of the hydraulically driven fuel 2 pump.";
CM_ SG_ 2566668542 EngFuel2PumpHydDirectionalValve "Position of hydraulic directional valve to control application of hydraulic oil flow.  0% is no flow to the appliance; 100% is full flow to the appliance.";
CM_ SG_ 2566668542 EngFuel2PumpHydSwashPlateAngle "Position of hydraulic swash plate angle within hydraulic pump.  0% represents the lowest possible flow, 100% represents the maximum flow.";
CM_ SG_ 2566668542 EngFuel2PumpHydFlowCtrlValve "Position of hydraulic pump flow control valve opening; 0% = fully closed, 100% = fully open.";
CM_ SG_ 2566668286 EngStagedTurboSolenoidStatus "Current state of the staged turbocharger solenoid, normalized to percent, 0% represents not actuated and 100% represents fully actuated.";
CM_ SG_ 2566668030 HtExchngerDebrisPurgeApproaching "Status signal which indicates that purging the debris from the heat exchanger is imminent.
00     Not approaching
01     Approaching
10     SAE reserved
11     Not available";
CM_ SG_ 2566668030 HeatExchangerDebrisPurgeStatus "Indicates whether the system is currently purging debris from the heat exchanger.
00    Inactive
01    Active
10    SAE reserved
11    Not available";
CM_ SG_ 2566667774 EngEndBearing8Temp "Temperature of end bearing of the connecting rod for cylinder 8 on the engine";
CM_ SG_ 2566667774 EngEndBearing7Temp "Temperature of end bearing of the connecting rod for cylinder 7 on the engine";
CM_ SG_ 2566667774 EngEndBearing6Temp "Temperature of end bearing of the connecting rod for cylinder 6 on the engine";
CM_ SG_ 2566667774 EngEndBearing5Temp "Temperature of end bearing of the connecting rod for cylinder 5 on the engine";
CM_ SG_ 2566667774 EngEndBearing4Temp "Temperature of end bearing of the connecting rod for cylinder 4 on the engine";
CM_ SG_ 2566667774 EngEndBearing3Temp "Temperature of end bearing of the connecting rod for cylinder 3 on the engine";
CM_ SG_ 2566667774 EngEndBearing2Temp "Temperature of end bearing of the connecting rod for cylinder 2 on the engine";
CM_ SG_ 2566667774 EngEndBearing1Temp "Temperature of end bearing of the connecting rod for cylinder 1 on the engine";
CM_ SG_ 2566667518 EngEndBearing16Temp "Temperature of end bearing of the connecting rod for cylinder 16 on the engine";
CM_ SG_ 2566667518 EngEndBearing15Temp "Temperature of end bearing of the connecting rod for cylinder 15 on the engine";
CM_ SG_ 2566667518 EngEndBearing14Temp "Temperature of end bearing of the connecting rod for cylinder 14 on the engine";
CM_ SG_ 2566667518 EngEndBearing13Temp "Temperature of end bearing of the connecting rod for cylinder 13 on the engine";
CM_ SG_ 2566667518 EngEndBearing12Temp "Temperature of end bearing of the connecting rod for cylinder 12 on the engine";
CM_ SG_ 2566667518 EngEndBearing11Temp "Temperature of end bearing of the connecting rod for cylinder 11 on the engine";
CM_ SG_ 2566667518 EngEndBearing10Temp "Temperature of end bearing of the connecting rod for cylinder 10 on the engine";
CM_ SG_ 2566667518 EngEndBearing9Temp "Temperature of end bearing of the connecting rod for cylinder 9 on the engine";
CM_ SG_ 2566667262 EngEndBearing20Temp "Temperature of end bearing of the connecting rod for cylinder 20 on the engine";
CM_ SG_ 2566667262 EngEndBearing19Temp "Temperature of end bearing of the connecting rod for cylinder 19 on the engine";
CM_ SG_ 2566667262 EngEndBearing18Temp "Temperature of end bearing of the connecting rod for cylinder 18 on the engine";
CM_ SG_ 2566667262 EngEndBearing17Temp "Temperature of end bearing of the connecting rod for cylinder 17 on the engine";
CM_ SG_ 2499558142 GsFlSpplyShtoffValve2IntakePress "Pressure of gaseous fuel supply measured at shutoff valve 2 in gaseous fuel supply unit. Shutoff valves are used to regulate gaseous fuel supply to engine.";
CM_ SG_ 2499558142 GsFlSpplyShtoffValve1IntakePress "Pressure of gaseous fuel supply measured at shutoff valve 1 in gaseous fuel supply unit. Shutoff valves are used to regulate gaseous fuel supply to engine.";
CM_ SG_ 2499558142 GasFuelSupplyUnitIntakePress "Pressure of gaseous fuel supply measured at the intake of gaseous fuel supply unit. Gaseous fuel valve unit contains block and bleed valves to regulate the flow of gaseous fuel from the plant to engine.
Gas Supply Unit Intake Pressure";
CM_ SG_ 2499558142 EngGasFuelSupplyPress2 "Second gage pressure measurement of gaseous fuel supply to fuel metering device. If only one sensor is used for gas supply pressure measurement, use SPN 159 instead.";
CM_ SG_ 2499557886 PlantInertGasSupplyOutletPress "Pressure of the purge gas supplied to the engine. Inert gas is used to remove gaseous fuel build-up in the engines and in the fuel supply lines when gaseous fuel is not in operation.";
CM_ SG_ 2499557886 PlantGasFuelSupplyOutletPress "Pressure of the gaseous fuel supplied from the plant room for one or more engines.  Based on the application, plant room will contain fuel tank for gas, vaporizer and heater and cooler compartments.";
CM_ SG_ 2499557630 EngOilMist8Concentration "Percentage of detected oil mist in compartment 8 compared to the lower explosion limit (LEL). 100% means the measured value is on the lower explosion limit,whereas 0% means no detected oil mist in the air.";
CM_ SG_ 2499557630 EngOilMist7Concentration "Percentage of detected oil mist in compartment 7 compared to the lower explosion limit (LEL). 100% means the measured value is on the lower explosion limit,whereas 0% means no detected oil mist in the air.";
CM_ SG_ 2499557630 EngOilMist6Concentration "Percentage of detected oil mist in compartment 6 compared to the lower explosion limit (LEL). 100% means the measured value is on the lower explosion limit,whereas 0% means no detected oil mist in the air.";
CM_ SG_ 2499557630 EngOilMist5Concentration "Percentage of detected oil mist in compartment 5 compared to the lower explosion limit (LEL). 100% means the measured value is on the lower explosion limit,whereas 0% means no detected oil mist in the air.";
CM_ SG_ 2499557630 EngOilMist4Concentration "Percentage of detected oil mist in compartment 4 compared to the lower explosion limit (LEL). 100% means the measured value is on the lower explosion limit,whereas 0% means no detected oil mist in the air.";
CM_ SG_ 2499557630 EngOilMist3Concentration "Percentage of detected oil mist in compartment 3 compared to the lower explosion limit (LEL). 100% means the measured value is on the lower explosion limit,whereas 0% means no detected oil mist in the air.";
CM_ SG_ 2499557630 EngOilMist2Concentration "Percentage of detected oil mist in compartment 2 compared to the lower explosion limit (LEL). 100% means the measured value is on the lower explosion limit,whereas 0% means no detected oil mist in the air.";
CM_ SG_ 2499557630 EngOilMist1Concentration "Percentage of detected oil mist in compartment 1 compared to the lower explosion limit (LEL). 100% means the measured value is on the lower explosion limit, whereas 0% means no detected oil mist in the air. This measurement is typically taken in ...";
CM_ SG_ 2499557374 EngOilMist10Concentration "Percentage of detected oil mist in compartment 10 compared to the lower explosion limit (LEL). 100% means the measured value is on the lower explosion limit,whereas 0% means no detected oil mist in the air.";
CM_ SG_ 2499557374 EngOilMist9Concentration "Percentage of detected oil mist in compartment 9 compared to the lower explosion limit (LEL). 100% means the measured value is on the lower explosion limit,whereas 0% means no detected oil mist in the air.";
CM_ SG_ 2499557118 InertGasSupplyValvePos "Position of inert gas supply valve used to control the flow of inert gas into the engine to purge the system.
0% represents valve fully closed and 100% represents valve fully open.";
CM_ SG_ 2499557118 GasFuelSupplyBleedValve3Pos "Position of bleed valve 3, which is used to control the flow of gaseous fuel through the fuel supply unit. 0% represents valve fully closed and 100% represents valve fully open.";
CM_ SG_ 2499557118 GasFuelSupplyBleedValve2Pos "Position of bleed valve 2, which is used to control the flow of gaseous fuel through the fuel supply unit. 0% represents valve fully closed and 100% represents valve fully open.";
CM_ SG_ 2499557118 GasFuelSupplyBleedValve1Pos "Position of bleed valve 1, which is used to control the flow of gaseous fuel through the fuel supply unit. 0% represents valve fully closed and 100% represents valve fully open.";
CM_ SG_ 2499557118 GasFuelSupplyShutoffValve2Pos "Position of shutoff valve 2, which is used to control the flow of gaseous fuel through the fuel supply unit. 0% represents valve fully closed and 100% represents valve fully open.";
CM_ SG_ 2499557118 GasFuelSupplyShutoffValve1Pos "Position of shutoff valve 1, which is used to control the flow of gaseous fuel through the fuel supply unit. 0% represents valve fully closed and 100% represents valve fully open.";
CM_ SG_ 2566665726 TwoMotorSpd "Rotational speed of the motor driving the second pump for the diesel exhaust fluid used in aftertreatment system 2 (exhaust bank 2).";
CM_ SG_ 2566665726 Htr "Percentage of heating applied to the aftertreatment 2 diesel exhaust fluid pump heater.  A value of 0% means no heating applied, a value of 100% means full heating applied. The diesel exhaust fluid pump heater warms the diesel exhaust fluid in the ...";
CM_ SG_ 2499556606 EngInjectorMeteringRail2Press2 "The pressure of fuel measured by second rail pressure sensor in the metering rail 2 as delivered from the supply pump to the injector metering intake.";
CM_ SG_ 2499556606 EngInjectorMeteringRail2Press1 "The pressure of fuel measured by first rail pressure sensor in the metering rail 2 as delivered from the supply pump to the injector metering intake.";
CM_ SG_ 2499556606 EngInjectorMeteringRail1Press2 "The pressure of fuel measured by the second rail pressure sensor in the primary, or first, metering rail as delivered from the supply pump to the injector metering intake.";
CM_ SG_ 2499556606 EngInjectorMeteringRail1Press1 "The pressure of fuel measured by first rail pressure sensor in the primary, or first, metering rail as delivered from the supply pump to the injector metering intake.";
CM_ SG_ 2499556350 EngInjctrMtringRail2DesiredPress "The desired pressure of fuel in metering rail 2 as delivered from the supply pump to the injector metering intake.";
CM_ SG_ 2499556350 EngInjctrMtringRail1DesiredPress "The desired pressure of fuel in the primary, or first, metering rail as delivered from the supply pump to the injector metering intake.";
CM_ SG_ 2499556094 HtrPwrSupplyDiagnosticStatus "The value of this parameter is not retained when power is removed from the particulate sensor.
000 - Tests monitored continuously. There are no enable or pause conditions. See Aftertreatment 1 Particulate Sensor Heater Power Supply Preliminary FMI ...";
CM_ SG_ 2499556094 HtrPwrSupplyPreliminaryFMI "Used to identify the applicable J1939-73 FMI detected in the aftertreatment particulate sensor heater power supply by the manufacturer’s sensor control software in exhaust bank 1. When there is no failure FMI 31 is sent. In the case of multiple ...";
CM_ SG_ 2499556094 PwrSupplyDiagnosticStatus "The value of this parameter is not retained when power is removed from the particulate sensor.
000 - Tests monitored continuously. There are no enable or pause conditions. See Aftertreatment 1 Particulate Sensor Power Supply Preliminary FMI (SPN ...";
CM_ SG_ 2499556094 PwrSupplyPreliminaryFMI "Used to identify the applicable J1939-73 FMI detected in the aftertreatment particulate sensor power supply by the manufacturer’s sensor control software in exhaust bank 1. When there is no failure FMI 31 is sent. In the case of multiple failures ...";
CM_ SG_ 2499556094 InputDiagnosticStatus "The value of this parameter is not retained when power is removed from the particulate sensor.
000 - Tests monitored continuously. There are no enable or pause conditions. See Aftertreatment 1 Particulate Sensor Input Preliminary FMI (SPN 7325) for ...";
CM_ SG_ 2499556094 InputPreliminaryFMI "Used to identify the applicable J1939-73 FMI detected in the aftertreatment particulate sensor input by the manufacturer’s sensor control software in exhaust bank 1. When there is no failure FMI 31 is sent. In the case of multiple failures the most ...";
CM_ SG_ 2499556094 HtrLowSideDriverDiagnosticStatus "The value of this parameter is not retained when power is removed from the particulate sensor.
000 - Tests monitored continuously. There are no enable or pause conditions. See Aftertreatment 1 Particulate Sensor Heater Low Side Driver Preliminary ...";
CM_ SG_ 2499556094 HtrLowSideDriverPreliminaryFMI "Used to identify the applicable J1939-73 FMI detected in the aftertreatment particulate sensor heater high side driver by the manufacturer’s sensor control software in exhaust bank 1. When there is no failure FMI 31 is sent. In the case of multiple ...";
CM_ SG_ 2499556094 HtrHiSideDriverDiagnosticStatus "The value of this parameter is not retained when power is removed from the particulate sensor.
000 - Tests monitored continuously. There are no enable or pause conditions. See Aftertreatment 1 Particulate Sensor Heater High Side Driver Preliminary ...";
CM_ SG_ 2499556094 HtrHiSideDriverPreliminaryFMI "Used to identify the applicable J1939-73 FMI detected in the aftertreatment particulate sensor heater high side driver by the manufacturer’s sensor control software in exhaust bank 1. When there is no failure FMI 31 is sent. In the case of multiple ...";
CM_ SG_ 2566664702 DEFTankTemp "The derived diesel exhaust fluid tank temperature in applications with multiple temperature sensors in a single tank. The SPN data will be derived from all temperature sensors in the tank.
Note: This SPN can be derived from any of the ...";
CM_ SG_ 2566664702 DEFTankVolume "The derived diesel exhaust fluid tank volume in applications with multiple level sensors in a single tank. The SPN data will be derived from all level sensors in the tank.
Note: This SPN can be derived from any of the aftertreatment tank level ...";
CM_ SG_ 2566664702 DEFHtrCircuitBreaker "The status of the circuit breaker that is used to heat the diesel exhaust fluid.
00 off
01 on
10 error
11 not available";
CM_ SG_ 2566664702 AAT "Temperature of ambient air near the aftertreatment components such as DEF tank and DEF lines.";
CM_ SG_ 2566664702 EngLoadReq "Indicates whether the aftertreatment desires engine load to be applied. This is meant to notify the operator that the aftertreatment is requesting engine load for thermal purposes.
The operator is expected to add load to the engine to satisfy this ...";
CM_ SG_ 2566664702 EngSpdIncreaseReq "Indicates whether the aftertreatment desires engine speed control in order to increase the engine speed. This is meant to notify the operator that the aftertreatment is requesting an increase in engine speed for thermal purposes.
The operator is ...";
CM_ SG_ 2566664702 ActiveRegenInhibitedDueToLowEP "The state of aftertreatment active regeneration inhibition due to low exhaust pressure.
Aftertreatment Regeneration is a process of increasing the temperature at the exhaust and thereby removing the deposits on aftertreatment components such as DPF ...";
CM_ SG_ 2566664702 ThermalManagementStatus "Indicates whether Aftertreatment Thermal Management process is active.
Aftertreatment Thermal Management indicates that the exhaust temperatures have been controlled for the normal functioning of the aftertreatment system - This is not just limited ...";
CM_ SG_ 2633773310 SCROprtrIndcmntOvrrdTmeRemaining "Used to indicate the time remaining during an operator inducement override event.  When an operator inducement is active this parameter indicates the remaining time that the currently active operator inducement may be overridden.
See also SPN 6878 ...";
CM_ SG_ 2633773310 SCROprtrIndcmntOvrrdRnwlRequired "Indicates the required operator inducement override renewal state.
00 = Not Required
01 = Required
10 = Error
11 = Not Available";
CM_ SG_ 2633773310 SCROpratorInducementOverrideMode "Indicates the functional mode of SCR operator inducement override.
000          Not Available
001          Available - Not Active
010          Active
011          Active Extended
100          Expired
101-110  Not Defined
111          Not ...";
CM_ SG_ 2633773310 SCROprtrIndcmntEmrgncyOvrrdTtlRs "The total number of times the feature, which allows the operator to override the inducement strategies (as described in SPN 6880) during emergencies, such as hurricanes, has been reset.
This counter can not be reset.";
CM_ SG_ 2633773054 FrSpprssnCmprssdArFmSystmArPress "Compressed Air Foam System (CAFS) air compressor pressure.";
CM_ SG_ 2633773054 FrSuppressionClassBFoamTankLevel "Liquid level of the Class-B foam agent tank.";
CM_ SG_ 2633773054 FrSuppressionClassAFoamTankLevel "Liquid level of the Class-A foam agent tank.";
CM_ SG_ 2633773054 FireSuppressionWaterTankLevel "Liquid level of the fire apparatus water tank.";
CM_ SG_ 2566663934 WastegateAct2MotorCurDis "Command to disable power to motor in wastegate actuator 2 to prevent unnecessary load on the component.
00 - Do Not Disable
01 - Disable
10 - Reserved
11 - Don't Care/Take No Action";
CM_ SG_ 2566663934 CompressorBypassAct2MotorCurDis "Command to disable power to motor in bypass actuator 2 to prevent unnecessary load on the component.
00 - Do Not Disable
01 - Disable
10 - Reserved
11 - Don't Care/Take No Action";
CM_ SG_ 2566663934 CompressorBypassAct1MotorCurDis "Command to disable power to motor in bypass actuator 1 to prevent unnecessary load on the component.
00 - Do Not Disable
01 - Disable
10 - Reserved
11 - Don't Care/Take No Action";
CM_ SG_ 2566663934 EngThrttlVlv1MotorCurrentDisable "Command to disable power to motor in the actuator to prevent unnecessary load on the component.
00 - Do Not Disable
01 - Disable
10 - Reserved
11 - Don't Care/Take No Action";
CM_ SG_ 2566663934 EngCylHdBypssActtr1MtrCrrntDsble "Command to disable power to motor in the actuator to prevent unnecessary load on the component.
00 - Do Not Disable
01 - Disable
10 - Reserved
11 - Don't Care/Take No Action";
CM_ SG_ 2566663934 EngTrbWstgtActtr1MtrCrrntDisable "Command to disable power to motor in the actuator to prevent unnecessary load on the component.
00 - Do Not Disable
01 - Disable
10 - Reserved
11 - Don't Care/Take No Action";
CM_ SG_ 2566663934 EngTrbCmprssrBlwffActtr1MtrCrrnt "Command to disable power to motor in the actuator to prevent unnecessary load on the component.
00 - Do Not Disable
01 - Disable
10 - Reserved
11 - Don't Care/Take No Action";
CM_ SG_ 2566663678 EngFl2InjectorMeteringRail1Temp2 "The second temperature of fuel 2 measured by first rail temperature sensor in the primary, or first, metering rail as delivered from the supply pump to the injector metering intake.";
CM_ SG_ 2566663678 LNGTank2VaporPress "Gage pressure of the vapor in the second tank in a multi-tank system.";
CM_ SG_ 2566663678 LNGTank1VaporPress "Gage pressure of the vapor in the first tank in a multi-tank system (or unique tank if single-tank system).";
CM_ SG_ 2566663422 TrlrBrkClprLnngClranceAxle5Right "Brake caliper lining clearance for right brake on trailer axle 5.
00 - Caliper lining clearance is adequate
01 - Caliper lining clearance is low
10 - Error
11 - Not available / not applicable";
CM_ SG_ 2566663422 TrlrBrkClprLnngClaranceAxle5Left "Brake caliper lining clearance for left brake on trailer axle 5.
00 - Caliper lining clearance is adequate
01 - Caliper lining clearance is low
10 - Error
11 - Not available / not applicable";
CM_ SG_ 2566663422 TrlrBrkClprLnngClranceAxle4Right "Brake caliper lining clearance for right brake on trailer axle 4.
00 - Caliper lining clearance is adequate
01 - Caliper lining clearance is low
10 - Error
11 - Not available / not applicable";
CM_ SG_ 2566663422 TrlrBrkClprLnngClaranceAxle4Left "Brake caliper lining clearance for left brake on trailer axle 4.
00 - Caliper lining clearance is adequate
01 - Caliper lining clearance is low
10 - Error
11 - Not available / not applicable";
CM_ SG_ 2566663422 TrlrBrkClprLnngClranceAxle3Right "Brake caliper lining clearance for right brake on trailer axle 3.
00 - Caliper lining clearance is adequate
01 - Caliper lining clearance is low
10 - Error
11 - Not available / not applicable";
CM_ SG_ 2566663422 TrlrBrkClprLnngClaranceAxle3Left "Brake caliper lining clearance for left brake on trailer axle 3.
00 - Caliper lining clearance is adequate
01 - Caliper lining clearance is low
10 - Error
11 - Not available / not applicable";
CM_ SG_ 2566663422 TrlrBrkClprLnngClranceAxle2Right "Brake caliper lining clearance for right brake on trailer axle 2.
00 - Caliper lining clearance is adequate
01 - Caliper lining clearance is low
10 - Error
11 - Not available / not applicable";
CM_ SG_ 2566663422 TrlrBrkClprLnngClaranceAxle2Left "Brake caliper lining clearance for left brake on trailer axle 2.
00 - Caliper lining clearance is adequate
01 - Caliper lining clearance is low
10 - Error
11 - Not available / not applicable";
CM_ SG_ 2566663422 TrlrBrkClprLnngClranceAxle1Right "Brake caliper lining clearance for right brake on trailer axle 1.
00 - Caliper lining clearance is adequate
01 - Caliper lining clearance is low
10 - Error
11 - Not available / not applicable";
CM_ SG_ 2566663422 TrlrBrkClprLnngClaranceAxle1Left "Brake caliper lining clearance for left brake on trailer axle 1.
00 - Caliper lining clearance is adequate
01 - Caliper lining clearance is low
10 - Error
11 - Not available / not applicable";
CM_ SG_ 2566663422 TrctrBrkClprLnngClrnceAxle5Right "Brake caliper lining clearance for right brake on tractor axle 5.
00 - Caliper lining clearance is adequate
01 - Caliper lining clearance is low
10 - Error
11 - Not available / not applicable";
CM_ SG_ 2566663422 TrctrBrkClprLnngClranceAxle5Left "Brake caliper lining clearance for left brake on tractor axle 5.
00 - Caliper lining clearance is adequate
01 - Caliper lining clearance is low
10 - Error
11 - Not available / not applicable";
CM_ SG_ 2566663422 TrctrBrkClprLnngClrnceAxle4Right "Brake caliper lining clearance for right brake on tractor axle 4.
00 - Caliper lining clearance is adequate
01 - Caliper lining clearance is low
10 - Error
11 - Not available / not applicable";
CM_ SG_ 2566663422 TrctrBrkClprLnngClranceAxle4Left "Brake caliper lining clearance for left brake on tractor axle 4.
00 - Caliper lining clearance is adequate
01 - Caliper lining clearance is low
10 - Error
11 - Not available / not applicable";
CM_ SG_ 2566663422 TrctrBrkClprLnngClrnceAxle3Right "Brake caliper lining clearance for right brake on tractor axle 3.
00 - Caliper lining clearance is adequate
01 - Caliper lining clearance is low
10 - Error
11 - Not available / not applicable";
CM_ SG_ 2566663422 TrctrBrkClprLnngClranceAxle3Left "Brake caliper lining clearance for left brake on tractor axle 3.
00 - Caliper lining clearance is adequate
01 - Caliper lining clearance is low
10 - Error
11 - Not available / not applicable";
CM_ SG_ 2566663422 TrctrBrkClprLnngClrnceAxle2Right "Brake caliper lining clearance for right brake on tractor axle 2.
00 - Caliper lining clearance is adequate
01 - Caliper lining clearance is low
10 - Error
11 - Not available / not applicable";
CM_ SG_ 2566663422 TrctrBrkClprLnngClranceAxle2Left "Brake caliper lining clearance for left brake on tractor axle 2.
00 - Caliper lining clearance is adequate
01 - Caliper lining clearance is low
10 - Error
11 - Not available / not applicable";
CM_ SG_ 2566663422 TrctrBrkClprLnngClrnceAxle1Right "Brake caliper lining clearance for right brake on tractor axle 1.
00 - Caliper lining clearance is adequate
01 - Caliper lining clearance is low
10 - Error
11 - Not available / not applicable";
CM_ SG_ 2566663422 TrctrBrkClprLnngClranceAxle1Left "Brake caliper lining clearance for left brake on tractor axle 1.
00 - Caliper lining clearance is adequate
01 - Caliper lining clearance is low
10 - Error
11 - Not available / not applicable";
CM_ SG_ 2566663166 CruiseCtrlAdjustedMaxSpeed "Present maximum vehicle velocity at which cruise can be set. This parameter is expected to change during run-time due to functionality that could influence the behavior of the cruise control algorithm. This functionality may include, but is not ...";
CM_ SG_ 2566663166 AppliedVehicleSpeedLimit "The vehicle speed limit in effect.
See SPN 2595 for alternate resolution.
Note:  If a maximum vehicle speed limit is not selected, then the first byte of this parameter will be equal to 0xFB.";
CM_ SG_ 2566662910 TimeToFinalIndAction "Indicates the time until the inducement strategy enforces the final level of engine emissions operator inducement. The final level of inducement can include derating the engine, shutting down the engine, or restricting the engine to low idle.
See ...";
CM_ SG_ 2566662910 OprtrIndcmntTmTTrqueDerateLevel2 "This parameter provides the time until Operator Inducement Torque Derate Level 2 (SPN 7427) is activated.
When operator inducement is not active (SPN 5826 is 000), this parameter will be set to 0xFB00.  If this parameter decrements to 0, it will ...";
CM_ SG_ 2566662910 OprtrIndcementTorqueDerateLevel2 "The next torque derate that will be applied to the engine operation due to operator inducement after the torque derate specified in Operator Inducement Torque Derate Level 1 (SPN 7425) becomes active.
This parameter is a percentage of how much the ...";
CM_ SG_ 2566662910 OprtrIndcmntTmTTrqueDerateLevel1 "This parameter provides the time until Operator Inducement Torque Derate Level 1 (SPN 7425) is activated.
When operator inducement is not active (SPN 5826 is 000), this parameter will be set to 0xFB00.  If this parameter decrements to 0, it will ...";
CM_ SG_ 2566662910 OprtrIndcementTorqueDerateLevel1 "This is the first torque derate that will be applied to the engine operation due to operator inducement.  The torque derate indicated in this parameter will be applied when the value in Operator Inducement Time to Torque Derate Level 1 (SPN 7426) ...";
CM_ SG_ 2566662654 LaneMarkQualityOnTheRightSide "The quality of the nearest lane mark on the right side of the vehicle.
000 = no lane marks detected
001 = low reliablity of detected lane marks
010 = good reliablity of detected lane marks
011 = perfect recognition of lane marks
100 - 101 = ...";
CM_ SG_ 2566662654 LaneMarkQualityOnTheLeftSide "The quality of the nearest lane mark on the left side of the vehicle.
000 = no lane marks detected
001 = low reliablity of detected lane marks
010 = good reliablity of detected lane marks
011 = perfect recognition of lane marks
100 - 101 = ...";
CM_ SG_ 2566662654 LaneDepartureAngleRight "Angle between right lane mark and vehicle driving direction. The angle is positive while vehicle is moving towards the lane marks, and negative if not. Measured values outside the limits are represented by signal value 251.
Parameter specific ...";
CM_ SG_ 2566662654 LaneDepartureAngleLeft "Angle between left lane mark and vehicle driving direction. The angle is positive while vehicle is moving towards the lane marks, and negative if not. Measured values outside the limits are represented by signal value 251.
Parameter specific values ...";
CM_ SG_ 2566662654 RoadCurvatureBasedOnLaneMarks "The road curvature parameter is based on lane marks as measured by the FLI.  It is the mean value of the road curvature of the lane marks on the left and right side of the lane. In case one of the lane mark is not recognized anymore, the value is ...";
CM_ SG_ 2566662654 RghtDstncTLnMrkFrmVehiclesMiddle "Distance between middle of the vehicle front and the inner/left edge of the nearest lane mark on the right side as measured from the Forward Lane Imager. The value represents the lane width at camera position. Measured values greater than 5 m ...";
CM_ SG_ 2566662654 LftDstncTLnMrkFromVehiclesMiddle "Distance between middle of the vehicle front and the inner/right edge of the nearest lane mark on the left side as measured from the Forward Lane Imager. The value represents the lane width at camera position. Measured values greater than 5 m ...";
CM_ SG_ 2566662142 Ctrl2Temp "Temperature of the diesel exhaust fluid at the aftertreatment 1 diesel exhaust fluid controller 2.";
CM_ SG_ 2566662142 Ctrl1Temp "Temperature of the diesel exhaust fluid at the aftertreatment 1 diesel exhaust fluid controller.
For controllers that have more exhaust emissions control functions than only diesel exhaust fluid control, see SPN 5486 - exhaust emission control ECU ...";
CM_ SG_ 2566661630 Htr2 "Percentage of heating applied to the second diesel exhaust fluid tank heater on aftertreatment 1. A value of 0% means no heating applied, a value of 100% means full heating applied. The diesel exhaust fluid tank heater warms the diesel exhaust fluid ...";
CM_ SG_ 2566661630 Temp2 "The second temperature of aftertreatment 1 diesel exhaust fluid in the storage tank.";
CM_ SG_ 2566661630 Volume2 "Second measurement of the ratio of volume of diesel exhaust fluid to the total volume of the diesel exhaust fluid storage container for aftertreatment system 1 (exhaust bank 1).  0% is empty and 100% is full.  See SPN 1761 and SPN 3517 for alternate ...";
CM_ SG_ 2566661374 Ctrl2Temp "Temperature of the diesel exhaust fluid at the aftertreatment 2 diesel exhaust fluid controller 2.";
CM_ SG_ 2566661374 CtrlTemp "Temperature of the diesel exhaust fluid at the aftertreatment 2 diesel exhaust fluid controller.";
CM_ SG_ 2566661374 Htr2 "Percentage of heating applied to the second diesel exhaust fluid tank heater on aftertreatment 2. A value of 0% means no heating applied, a value of 100% means full heating applied. The diesel exhaust fluid tank heater warms the diesel exhaust fluid ...";
CM_ SG_ 2566661374 Temp2 "The second temperature of aftertreatment 2 diesel exhaust fluid in the storage tank.";
CM_ SG_ 2566661374 Volume2 "Second measurement of the ratio of volume of diesel exhaust fluid to the total volume of the diesel exhaust fluid storage container for aftertreatment system 2 (exhaust bank 2).  0% is empty and 100% is full.  See SPN 4426 and SPN 4428 for alternate ...";
CM_ SG_ 2364598270 EngCyl24TimingOffset "The ignition timing offset for Cylinder 24 from the engine timing advance (SPN 7355) as a command to the ignition control module. Positive values command an increasingly advanced timing.";
CM_ SG_ 2364598270 EngCyl23TimingOffset "The ignition timing offset for Cylinder 23 from the engine timing advance (SPN 7355) as a command to the ignition control module. Positive values command an increasingly advanced timing.";
CM_ SG_ 2364598270 EngCyl22TimingOffset "The ignition timing offset for Cylinder 22 from the engine timing advance (SPN 7355) as a command to the ignition control module. Positive values command an increasingly advanced timing.";
CM_ SG_ 2364598270 EngCyl21TimingOffset "The ignition timing offset for Cylinder 21 from the engine timing advance (SPN 7355) as a command to the ignition control module. Positive values command an increasingly advanced timing.";
CM_ SG_ 2364598270 EngCyl20TimingOffset "The ignition timing offset for Cylinder 20 from the engine timing advance (SPN 7355) as a command to the ignition control module. Positive values command an increasingly advanced timing.";
CM_ SG_ 2364598270 EngCyl19TimingOffset "The ignition timing offset for Cylinder 19 from the engine timing advance (SPN 7355) as a command to the ignition control module. Positive values command an increasingly advanced timing.";
CM_ SG_ 2364598270 EngCyl18TimingOffset "The ignition timing offset for Cylinder 18 from the engine timing advance (SPN 7355) as a command to the ignition control module. Positive values command an increasingly advanced timing.";
CM_ SG_ 2364598270 EngCyl17TimingOffset "The ignition timing offset for Cylinder 17 from the engine timing advance (SPN 7355) as a command to the ignition control module. Positive values command an increasingly advanced timing.";
CM_ SG_ 2364598014 EngCyl16TimingOffset "The ignition timing offset for Cylinder 16 from the engine timing advance (SPN 7355) as a command to the ignition control module. Positive values command an increasingly advanced timing.";
CM_ SG_ 2364598014 EngCyl15TimingOffset "The ignition timing offset for Cylinder 15 from the engine timing advance (SPN 7355) as a command to the ignition control module. Positive values command an increasingly advanced timing.";
CM_ SG_ 2364598014 EngCyl14TimingOffset "The ignition timing offset for Cylinder 14 from the engine timing advance (SPN 7355) as a command to the ignition control module. Positive values command an increasingly advanced timing.";
CM_ SG_ 2364598014 EngCyl13TimingOffset "The ignition timing offset for Cylinder 13 from the engine timing advance (SPN 7355) as a command to the ignition control module. Positive values command an increasingly advanced timing.";
CM_ SG_ 2364598014 EngCyl12TimingOffset "The ignition timing offset for Cylinder 12 from the engine timing advance (SPN 7355) as a command to the ignition control module. Positive values command an increasingly advanced timing.";
CM_ SG_ 2364598014 EngCyl11TimingOffset "The ignition timing offset for Cylinder 11 from the engine timing advance (SPN 7355) as a command to the ignition control module. Positive values command an increasingly advanced timing.";
CM_ SG_ 2364598014 EngCyl10TimingOffset "The ignition timing offset for Cylinder 10 from the engine timing advance (SPN 7355) as a command to the ignition control module. Positive values command an increasingly advanced timing.";
CM_ SG_ 2364598014 EngCyl9TimingOffset "The ignition timing offset for Cylinder 9 from the engine timing advance (SPN 7355) as a command to the ignition control module. Positive values command an increasingly advanced timing.";
CM_ SG_ 2364597758 EngCyl8TimingOffset "The ignition timing offset for Cylinder 8 from the engine timing advance (SPN 7355) as a command to the ignition control module. Positive values command an increasingly advanced timing.";
CM_ SG_ 2364597758 EngCyl7TimingOffset "The ignition timing offset for Cylinder 7 from the engine timing advance (SPN 7355) as a command to the ignition control module. Positive values command an increasingly advanced timing.";
CM_ SG_ 2364597758 EngCyl6TimingOffset "The ignition timing offset for Cylinder 6 from the engine timing advance (SPN 7355) as a command to the ignition control module. Positive values command an increasingly advanced timing.";
CM_ SG_ 2364597758 EngCyl5TimingOffset "The ignition timing offset for Cylinder 5 from the engine timing advance (SPN 7355) as a command to the ignition control module. Positive values command an increasingly advanced timing.";
CM_ SG_ 2364597758 EngCyl4TimingOffset "The ignition timing offset for Cylinder 4 from the engine timing advance (SPN 7355) as a command to the ignition control module. Positive values command an increasingly advanced timing.";
CM_ SG_ 2364597758 EngCyl3TimingOffset "The ignition timing offset for Cylinder 3 from the engine timing advance (SPN 7355) as a command to the ignition control module. Positive values command an increasingly advanced timing.";
CM_ SG_ 2364597758 EngCyl2TimingOffset "The ignition timing offset for Cylinder 2 from the engine timing advance (SPN 7355) as a command to the ignition control module. Positive values command an increasingly advanced timing.";
CM_ SG_ 2364597758 EngCyl1TimingOffset "The ignition timing offset for Cylinder 1 from the engine timing advance (SPN 7355) as a command to the ignition control module. Positive values command an increasingly advanced timing.";
CM_ SG_ 2364593150 PrdctvCrsCtrlDrvlnDsnggInhibitRq "Request to temporarily inhibit a fuel saving feature that would normally open the driveline. Under certain conditions and with knowledge of the terrain, inhibiting this feature may improve fuel economy.
SPN 683 Disengage Driveline Request has ...";
CM_ SG_ 2364593150 VhclSpdCtrlOvrrideEventIndicator "Indicates to the operator that a Speed Control override event is active.  \"Speed Control\" refers to retarders or methods of automatically limiting vehicle speed, for instance on downhill grades.  An active event indicates that vehicle speed may ...";
CM_ SG_ 2364593150 PrdctvCrsCtrlSpeedEventIndicator "Indicates to the operator that a predictive cruise control (PCC) speed event is active. Typically, this will correspond to a Predictive Cruise Control Set Speed Offset (SPN 7316) request to increase or decrease vehicle speed from the nominal cruise ...";
CM_ SG_ 2364593150 PredictiveCruiseCtrlNextGrade "Road grade at next predictive cruise control (PCC) event. Positive numbers indicate uphill grade, negative are downhill for vehicle direction of travel. For grades beyond the limits of the parameter, the limit value shall be reported.";
CM_ SG_ 2364593150 PredictiveCruiseCtrlPresentGrade "Road grade at present vehicle position. Positive numbers indicate uphill grade, negative are downhill for present vehicle direction of travel. For grades beyond the limits of the parameter, the limit value shall be reported.";
CM_ SG_ 2364593150 PredictiveCruiseCtrlEventInRange "Indicates that an event, such as a grade, is detected within the range of the predictive cruise control (PCC) look-ahead distance.
00 - No PCC event in range
01 - PCC event in range
10 - Error
11 - Not available
Note:  Intended to be sent ...";
CM_ SG_ 2364593150 VehicleSpeedCtrlOverrideRq "Speed control override requested. Indicates that the minimum restriction of speed is desired, for instance when travelling downhill towards an impending uphill grade. This is not a request to inhibit engine brakes (or other speed limiting device) ...";
CM_ SG_ 2364593150 PredictiveCruiseCtrlState "Indicates the state of the PCC controller.
If this parameter is 0001, the cruise control set point may be modified by the Predictive Cruise Control Set Speed Offset (SPN 7316) . For states other than 0001, the value in Predictive Cruise Control Set ...";
CM_ SG_ 2364593150 PrdctiveCruiseCtrlSetSpeedOffset "The amount by which the actual set point used by the cruise control algorithm should be changed as determined by external factors (e.g., anticipated road grade).
If SPN 7317 indicates Enabled (0001b) and if the cruise control algorithm determines ...";
CM_ SG_ 2364592894 InAirSourceVlv "Status of the actuator/valve in the airbox used to source engine intake air from either the engine compartment or external to the vehicle.
00 - Off
01 - On
10 - Error
11 - Not available";
CM_ SG_ 2364592894 EngCylHeadBypassActuator1Cmd "Command to cylinder head bypass actuator 1, normalized to percent, where 0% nominally represents fully closed (No Flow) and 100% represents fully open (Max Flow). The purpose of the cylinder bypass valve is to release the air at the high pressure ...";
CM_ SG_ 2364592638 EngCylHdBypssActtr1OprtionStatus "Identifies the status of Engine Cylinder Head Bypass Actuator 1.
Cylinder head bypass valve is used to release the air at the high pressure compressor outlet into turbocharger turbine inlet when intake pressure exceeds exhaust pressure at lower ...";
CM_ SG_ 2364592638 EngCylHeadBypassActuator1Pos "Actual position of Engine Cylinder Head Bypass actuator, where 0% represents fully closed and 100% represents fully open.
Cylinder Head bypass valve is used to release the air at the high pressure compressor outlet into turbocharger turbine inlet ...";
CM_ SG_ 2364592638 EngCylHdBypssActuator1DesiredPos "Requested position of Engine Cylinder Head Bypass actuator by engine ECM, where 0% represents bypass fully closed and 100% represents fully open. This is the position that the device is attempting to achieve.
Cylinder Head bypass valve is used to ...";
CM_ SG_ 2364592638 EngCylHeadBypassActuator1Temp "Temperature of the Engine Cylinder Head Bypass Actuator 1 drive circuitry. Temperature excursions may affect the torque output.
Cylinder Head bypass valve is used to release the air at the high pressure compressor outlet into turbocharger turbine ...";
CM_ SG_ 2364592638 EngCylHdBypssActuator1TempStatus "Identifies the status of the Engine Cylinder Head Bypass Blowoff Actuator 1 drive circuitry temperature. Temperature excursions may affect the torque output.
Cylinder Head bypass valve is used to release the air at the high pressure compressor ...";
CM_ SG_ 2364592638 EngCylHdBypssActtr1PrliminaryFMI "Identifies the applicable J1939-73 FMI detected in Engine Cylinder Head Bypass Actuator 1 by the manufacturer's software. When there is no failure FMI 31 is transmitted. When there are multiple failures, the most severe is transmitted.
Cylinder ...";
CM_ SG_ 2364592382 EngCyl24ExcludeFromCombustionRq "Request to the engine ECU to exclude (skip or cut-out) cylinder 24 from combustion.
00 Exclude from Combustion
01 Include for Combustion
10 Reserved
11 Not available/Do not care";
CM_ SG_ 2364592382 EngCyl23ExcludeFromCombustionRq "Request to the engine ECU to exclude (skip or cut-out) cylinder 23 from combustion.
00 Exclude from Combustion
01 Include for Combustion
10 Reserved
11 Not available/Do not care";
CM_ SG_ 2364592382 EngCyl22ExcludeFromCombustionRq "Request to the engine ECU to exclude (skip or cut-out) cylinder 22 from combustion.
00 Exclude from Combustion
01 Include for Combustion
10 Reserved
11 Not available/Do not care";
CM_ SG_ 2364592382 EngCyl21ExcludeFromCombustionRq "Request to the engine ECU to exclude (skip or cut-out) cylinder 21 from combustion.
00 Exclude from Combustion
01 Include for Combustion
10 Reserved
11 Not available/Do not care";
CM_ SG_ 2364592382 EngCyl20ExcludeFromCombustionRq "Request to the engine ECU to exclude (skip or cut-out) cylinder 20 from combustion.
00 Exclude from Combustion
01 Include for Combustion
10 Reserved
11 Not available/Do not care";
CM_ SG_ 2364592382 EngCyl19ExcludeFromCombustionRq "Request to the engine ECU to exclude (skip or cut-out) cylinder 19 from combustion.
00 Exclude from Combustion
01 Include for Combustion
10 Reserved
11 Not available/Do not care";
CM_ SG_ 2364592382 EngCyl18ExcludeFromCombustionRq "Request to the engine ECU to exclude (skip or cut-out) cylinder 18 from combustion.
00 Exclude from Combustion
01 Include for Combustion
10 Reserved
11 Not available/Do not care";
CM_ SG_ 2364592382 EngCyl17ExcludeFromCombustionRq "Request to the engine ECU to exclude (skip or cut-out) cylinder 17 from combustion.
00 Exclude from Combustion
01 Include for Combustion
10 Reserved
11 Not available/Do not care";
CM_ SG_ 2364592382 EngCyl16ExcludeFromCombustionRq "Request to the engine ECU to exclude (skip or cut-out) cylinder 16 from combustion.
00 Exclude from Combustion
01 Include for Combustion
10 Reserved
11 Not available/Do not care";
CM_ SG_ 2364592382 EngCyl15ExcludeFromCombustionRq "Request to the engine ECU to exclude (skip or cut-out) cylinder 15 from combustion.
00 Exclude from Combustion
01 Include for Combustion
10 Reserved
11 Not available/Do not care";
CM_ SG_ 2364592382 EngCyl14ExcludeFromCombustionRq "Request to the engine ECU to exclude (skip or cut-out) cylinder 14 from combustion.
00 Exclude from Combustion
01 Include for Combustion
10 Reserved
11 Not available/Do not care";
CM_ SG_ 2364592382 EngCyl13ExcludeFromCombustionRq "Request to the engine ECU to exclude (skip or cut-out) cylinder 13 from combustion.
00 Exclude from Combustion
01 Include for Combustion
10 Reserved
11 Not available/Do not care";
CM_ SG_ 2364592382 EngCyl12ExcludeFromCombustionRq "Request to the engine ECU to exclude (skip or cut-out) cylinder 12 from combustion.
00 Exclude from Combustion
01 Include for Combustion
10 Reserved
11 Not available/Do not care";
CM_ SG_ 2364592382 EngCyl11ExcludeFromCombustionRq "Request to the engine ECU to exclude (skip or cut-out) cylinder 11 from combustion.
00 Exclude from Combustion
01 Include for Combustion
10 Reserved
11 Not available/Do not care";
CM_ SG_ 2364592382 EngCyl10ExcludeFromCombustionRq "Request to the engine ECU to exclude (skip or cut-out) cylinder 10 from combustion.
00 Exclude from Combustion
01 Include for Combustion
10 Reserved
11 Not available/Do not care";
CM_ SG_ 2364592382 EngCyl9ExcludeFromCombustionRq "Request to the engine ECU to exclude (skip or cut-out) cylinder 9 from combustion.
00 Exclude from Combustion
01 Include for Combustion
10 Reserved
11 Not available/Do not care";
CM_ SG_ 2364592382 EngCyl8ExcludeFromCombustionRq "Request to the engine ECU to exclude (skip or cut-out) cylinder 8 from combustion.
00 Exclude from Combustion
01 Include for Combustion
10 Reserved
11 Not available/Do not care";
CM_ SG_ 2364592382 EngCyl7ExcludeFromCombustionRq "Request to the engine ECU to exclude (skip or cut-out) cylinder 7 from combustion.
00 Exclude from Combustion
01 Include for Combustion
10 Reserved
11 Not available/Do not care";
CM_ SG_ 2364592382 EngCyl6ExcludeFromCombustionRq "Request to the engine ECU to exclude (skip or cut-out) cylinder 6 from combustion.
00 Exclude from Combustion
01 Include for Combustion
10 Reserved
11 Not available/Do not care";
CM_ SG_ 2364592382 EngCyl5ExcludeFromCombustionRq "Request to the engine ECU to exclude (skip or cut-out) cylinder 5 from combustion.
00 Exclude from Combustion
01 Include for Combustion
10 Reserved
11 Not available/Do not care";
CM_ SG_ 2364592382 EngCyl4ExcludeFromCombustionRq "Request to the engine ECU to exclude (skip or cut-out) cylinder 4 from combustion.
00 Exclude from Combustion
01 Include for Combustion
10 Reserved
11 Not available/Do not care";
CM_ SG_ 2364592382 EngCyl3ExcludeFromCombustionRq "Request to the engine ECU to exclude (skip or cut-out) cylinder 3 from combustion.
00 Exclude from Combustion
01 Include for Combustion
10 Reserved
11 Not available/Do not care";
CM_ SG_ 2364592382 EngCyl2ExcludeFromCombustionRq "Request to the engine ECU to exclude (skip or cut-out) cylinder 2 from combustion.
00 Exclude from Combustion
01 Include for Combustion
10 Reserved
11 Not available/Do not care";
CM_ SG_ 2364592382 EngCyl1ExcludeFromCombustionRq "Request to the engine ECU to exclude (skip or cut-out) cylinder 1 from combustion.
00 Exclude from Combustion
01 Include for Combustion
10 Reserved
11 Not available/Do not care";
CM_ SG_ 2364592382 NmbrOfEngCylndrsTExcldFrmCmbston "Request to the engine ECU for the number of cylinders to exclude from combustion (cut-out or skip) for a given instance in time.  The engine ECU can decide on the cylinders to exclude from combustion.  One of the use cases would be sending this ...";
CM_ SG_ 2364567294 EngFlInjctnPump2FuelCtrlValveCmd "The control command to fuel control valve in fuel pump 2, normalized to percent, where 0% represents fully closed and 100% represents fully open.";
CM_ SG_ 2364567294 EngFlInjctnPump1FuelCtrlValveCmd "The control command to fuel control valve in fuel pump 1, normalized to percent, where 0% represents fully closed and 100% represents fully open.";
CM_ SG_ 2558918398 TransAutoNeutralEnableSw_7694 "This enable switch is for optional use with interfaces using SPN 7695 [Transmission Auto-Neutral (Manual Return) Request] or another vehicle input configured for Auto-Neutral (Manual Return) functionality. When supported by the vehicle system and ...";
CM_ SG_ 2558918398 AFTRegenEngSpdAllwdSw_7580 "If this parameter is 01, then the aftertreatment control system is permitted to perform an aftertreatment regeneration, but the aftertreatment control system is not allowed to take control of the engine speed for the purposes of regeneration. A ...";
CM_ SG_ 2558918398 ElevatedEngSpdAllowedSw_7579 "Indicates the state of a switch to indicate the control system is permitted to automatically elevate the engine speed as needed for strategies such as cold mode, aftertreatment regeneration, etc. This is not a direct command to increase the engine ...";
CM_ SG_ 2558918398 PrdctvCriseCtrlMaxNgtvOffst_7439 "Maximum speed decrease that the predictive cruise control (PCC) is allowed to request. This may be adjusted by the operator (either directly or indirectly) to tailor the performance of the PCC system.
This parameter is used in conjunction with ...";
CM_ SG_ 2558918398 PrdctvCriseCtrlMaxPstvOfst_7438 "Maximum speed increase that the predictive cruise control (PCC) is allowed to request. This may be adjusted by the operator (either directly or indirectly) to tailor the performance of the PCC system.
This parameter is used in conjunction with ...";
CM_ SG_ 2558918398 PrdctiveCruiseCtrlDactivnRq_7437 "Indicates that the operator has requested to deactivate the predictive cruise control (PCC) function.
If enabled, the PCC device may still provide notification of events in range, road grade, and other information. But if requested to be ...";
CM_ SG_ 2558918398 PredictiveCruiseCtrlEnblSw_7436 "Indicates whether predictive cruise control (PCC) is enabled. When not enabled, the predictive cruise control does not calculate a speed offset or identify predictive cruise events, and the predictive cruise control state (SPN 7317) shall not be ...";
CM_ SG_ 2558918398 HtExchngerDebrisPurgForceSw_7034 "Indicates the state of a switch available to the operator that forces the system to purge the debris from the heat exchanger.
00   not active
01   active
10   error
11   not available
This SPN would be “not active” when purging the debris from ...";
CM_ SG_ 2558918398 HtExchngrDbrisPurgeInhbitSw_7033 "Indicates the state of a switch available to the operator that will inhibit the system from purging the debris from the heat exchanger.
00   not active
01   active
10   error
11   not available
This SPN would be “not active” when purging the ...";
CM_ SG_ 2558918398 SCROprtrInducementOvridSw_6881 "The position of the operator inducement override switch. This switch function allows the operator to override an operator inducement derate.
See EU Commission directive 2012/46/EU. Appendix 1 Section 5.5 for more information.
00 Off
01 On
10 ...";
CM_ SG_ 2558918398 PerformanceBiasSelection_6874 "Indicates the operating bias toward performance of the power source.
0% Functionality is biased toward fuel economy as much as possible.
50% Functionality is biased toward neither fuel economy or performance.
100% Functionality is biased toward ...";
CM_ SG_ 2558918398 EngFan2RqstedPercentSpeed_6730 "Fan speed of the second fan in the system as a ratio of the actual fan drive (current speed) to the fully engaged fan drive (maximum fan speed). A two state fan (off/on) will use 0% and 100% respectively.  A three state fan (off/intermediate/on) ...";
CM_ SG_ 2558852862 ExhVelocity_6829 "Velocity of the exhaust gas near the particulate sensor.";
CM_ SG_ 2558852862 ExhTemp_6785 "This is the temperature in the exhaust stream that is closest to the particulate sensor. This could be a calculated value or read from another sensor. The ECU transmitting this message to the particulate sensor controller will be aware of the ...";
CM_ SG_ 2558852862 Dewpoint_6784 "Indicates that the temperature near the particulate sensor has exceeded the dew point.
00 - Dewpoint has not been reached
01 - Dewpoint has been reached
10 - SAE reserved
11 - Not available";
CM_ SG_ 2558852862 RegenReq_6783 "Another ECU would send this to request that the particulate sensor perform a regeneration of the sensor.  A request would be considered active when this parameter transitions from 00 to 01.
00 - Regeneration not requested
01 - Regeneration ...";
CM_ SG_ 2558852862 ShutdownReq_6782 "Aftertreatment 1 particulate sensor shutdown request.
00 - Shutdown request not active
01 - Shutdown request active
10 - SAE reserved
11 - Not available";
CM_ SG_ 2558787326 PayloadCorrectionFactorCmd_6873 "The payload correction factor is used to fine tune the sensor gain value.
Correction factor calibration of the Payload Measurement system is performed through a Payload Calibration Set Point SPN value of Correction Point and the Payload Correction ...";
CM_ SG_ 2558787326 PayloadCalibCmdedWeight_6872 "The true known mass of real load weight applicable for the calibration point specified in SPN 6871 and used for calibrating Payload system.
Multipoint calibration of the Payload Measurement system is perfomed by loading the machine with up to 10 ...";
CM_ SG_ 2558787326 PayloadCalibSetPointCmd_6871 "Specifies the current payload point being calibrated. The data specified in the 'Payload Calibration Commanded Weight' SPN (SPN 6872) or 'Payload Correction Factor Command' SPN (SPN 6873) shall be used for calibrating this specified payload point ...";
CM_ SG_ 2558721790 SnsrEnableSetting_7587 "Command signal used to enable/disable the tire sensor. On receipt of this command, the tire sensor may either be enabled or disabled.
00 Off / Isolate / Disable
01 On / Enable
10 Reserved / Not Defined
11 Don’t Care / Take No Action";
CM_ SG_ 2558721790 OverTempSetting_6978 "Configurable constant temperature above which an over temperature alert will trigger.";
CM_ SG_ 2558721790 OvrPrssPTSetting_6977 "Configurable percentage deviation from the set cold inflation pressure, for the over tire pressure alert.";
CM_ SG_ 2558721790 ExtrmUndrPrssPTStting_6976 "Configurable percent deviation from the set cold inflation pressure, for the extreme under tire pressure alert.";
CM_ SG_ 2558721790 UndrPrssPTSetting_6975 "Configurable percent deviation from the set cold inflation pressure, for the under tire pressure alert.";
CM_ SG_ 2558721790 ColdInflationPressSetting_6974 "Configurable value of the cold inflation pressure of the tire. Cold inflation pressure is the default/reference inflation pressure suggested by the manufacturer for a specific tire.";
CM_ SG_ 2558721790 TireLocation_6973 "The location of monitored tire on the vehicle.
The high order 4 bits indicate the vehicle axle position of the tire, counting front to back on the vehicle, with the value 0 representing the front axle on the vehicle. If the upper 4 bits have a ...";
CM_ SG_ 2558656254 RqToPermitDEFDosingTestInjection "A request to permit the DEF dosing test injection. The request continues to be broadcast until the test injection is finished or the corresponding permission status indicates an error.
000 = no request
001 = request to permit DEF Dosing Test ...";
CM_ SG_ 2558656254 RqToPermitDEFHydStiffnessCheck "A request to permit the DEF hydraulic stiffness check. The request continues to be broadcast until the stiffness check is finished or the corresponding permission status indicates an error.
00 = no request
01 = request to permit DEF hydraulic ...";
CM_ SG_ 2558656254 ThermalManagementInhReq "Provides state of inhibit request for Aftertreatment thermal management from external system.
Aftertreatment Thermal Management indicates that the exhaust temperatures have been controlled for expected functioning of the aftertreatment system - ...";

BA_DEF_ BO_ "GenMsgCycleTime" INT 0 3600000;
BA_DEF_ BO_ "GenMsgCycleTimeFast" INT 0 3600000;
BA_DEF_ BO_ "GenMsgDelayTime" INT 0 1000;
BA_DEF_ BO_ "GenMsgILSupport" ENUM  "No","Yes";
BA_DEF_ BO_ "GenMsgRequestable" INT 0 1;
BA_DEF_ BO_ "GenMsgSendType" ENUM  "cyclic","spontaneous","cyclicIfActive","spontaneousWithDelay","cyclicAndSpontaneous","cyclicAndSpontaneousWithDelay","spontaneousWithRepetition","cyclicIfActiveAndSpontaneousWD";
BA_DEF_ BO_ "GenMsgStartDelayTime" INT 0 100000;
BA_DEF_ BO_ "J1939PGNameSecSrc0Dest3" STRING;
BA_DEF_ BO_ "J1939PGPrio" INT 0 7;
BA_DEF_ BO_ "J1939PGPrioSrc0Dest3" INT 0 7;
BA_DEF_ BO_ "J1939PGRelationDest3Src0" INT 0 254;
BA_DEF_ BO_ "J1939PGRelationSrc0Dest3" INT 0 254;
BA_DEF_ BO_ "J1939PGRepCycleSrc0Dest3" INT -1 65535;
BA_DEF_ BO_ "J1939PGRepTypeSrc0Dest3" INT 0 4;
BA_DEF_ BO_ "J1939PGRepetitionCycle" INT 0 65535;
BA_DEF_ BO_ "J1939PGRepetitionType" ENUM  "always","when active","on request";
BA_DEF_ BO_ "J1939PGtoECUSrc0Dest3" INT 0 254;
BA_DEF_ BO_ "J1939PGtoWSMSrc0Dest3" INT 0 254;
BA_DEF_ BO_ "TpJ1939VarDlc" ENUM  "No","Yes";
BA_DEF_ BO_ "VFrameFormat" ENUM  "StandardCAN","ExtendedCAN","reserved","J1939PG";
BA_DEF_ SG_ "GenSigEVName" STRING;
BA_DEF_ SG_ "GenSigILSupport" ENUM  "No","Yes";
BA_DEF_ SG_ "GenSigSendType" ENUM  "Cyclic","OnWrite","OnWriteWithRepetition","OnChange","OnChangeWithRepetition","IfActive","IfActiveWithRepetition","NoSigSendType";
BA_DEF_ SG_ "GenSigStartValue" INT 0 10000;
BA_DEF_ SG_ "SPN" INT 0 524287;
BA_DEF_ SG_ "SigType" ENUM  "Default","Range","RangeSigned","ASCII","Discrete","Control","ReferencePGN","DTC","StringDelimiter","StringLength","StringLengthControl","MessageCounter","MessageChecksum";
BA_DEF_ SG_ "SystemSignalLongSymbol" STRING;
BA_DEF_DEF_ "GenMsgCycleTime" 0;
BA_DEF_DEF_ "GenMsgCycleTimeFast" 0;
BA_DEF_DEF_ "GenMsgDelayTime" 0;
BA_DEF_DEF_ "GenMsgILSupport" "Yes";
BA_DEF_DEF_ "GenMsgRequestable" 1;
BA_DEF_DEF_ "GenMsgSendType" "noMsgSendType";
BA_DEF_DEF_ "GenMsgStartDelayTime" 0;
BA_DEF_DEF_ "GenSigEVName" "Env@Nodename_@Signame";
BA_DEF_DEF_ "GenSigILSupport" "Yes";
BA_DEF_DEF_ "GenSigSendType" "NoSigSendType";
BA_DEF_DEF_ "GenSigStartValue" 0;
BA_DEF_DEF_ "J1939PGNameSecSrc0Dest3" "(null)";
BA_DEF_DEF_ "J1939PGPrio" 6;
BA_DEF_DEF_ "J1939PGPrioSrc0Dest3" 6;
BA_DEF_DEF_ "J1939PGRelationDest3Src0" 254;
BA_DEF_DEF_ "J1939PGRelationSrc0Dest3" 254;
BA_DEF_DEF_ "J1939PGRepCycleSrc0Dest3" -1;
BA_DEF_DEF_ "J1939PGRepTypeSrc0Dest3" 3;
BA_DEF_DEF_ "J1939PGRepetitionCycle" 100;
BA_DEF_DEF_ "J1939PGRepetitionType" "always";
BA_DEF_DEF_ "J1939PGtoECUSrc0Dest3" -1;
BA_DEF_DEF_ "J1939PGtoWSMSrc0Dest3" -1;
BA_DEF_DEF_ "SPN" 0;
BA_DEF_DEF_ "SigType" "Default";
BA_DEF_DEF_ "SystemSignalLongSymbol" "";
BA_DEF_DEF_ "TpJ1939VarDlc" "No";
BA_DEF_DEF_ "VFrameFormat" "J1939PG";
BA_ "GenMsgCycleTime" BO_ 2566687742 200;
BA_ "GenMsgSendType" BO_ 2566687742 0;
BA_ "GenMsgCycleTime" BO_ 2365348350 500;
BA_ "GenMsgDelayTime" BO_ 2365348350 50;
BA_ "GenMsgSendType" BO_ 2365348350 0;
BA_ "GenMsgCycleTime" BO_ 2566674686 1000;
BA_ "GenMsgSendType" BO_ 2566674686 0;
BA_ "GenMsgCycleTime" BO_ 2566674430 10000;
BA_ "GenMsgDelayTime" BO_ 2566674430 1000;
BA_ "GenMsgSendType" BO_ 2566674430 0;
BA_ "GenMsgCycleTime" BO_ 2566674174 10000;
BA_ "GenMsgDelayTime" BO_ 2566674174 1000;
BA_ "GenMsgSendType" BO_ 2566674174 0;
BA_ "GenMsgCycleTime" BO_ 2566673406 500;
BA_ "GenMsgSendType" BO_ 2566673406 0;
BA_ "GenMsgCycleTime" BO_ 2633782014 10000;
BA_ "GenMsgDelayTime" BO_ 2633782014 1000;
BA_ "GenMsgSendType" BO_ 2633782014 0;
BA_ "GenMsgCycleTime" BO_ 2365346302 100;
BA_ "GenMsgSendType" BO_ 2365346302 0;
BA_ "GenMsgCycleTime" BO_ 2566672638 1000;
BA_ "GenMsgSendType" BO_ 2566672638 0;
BA_ "GenMsgCycleTime" BO_ 2566672382 1000;
BA_ "GenMsgSendType" BO_ 2566672382 0;
BA_ "GenMsgCycleTime" BO_ 2566672126 500;
BA_ "GenMsgSendType" BO_ 2566672126 0;
BA_ "GenMsgCycleTime" BO_ 2566671870 500;
BA_ "GenMsgSendType" BO_ 2566671870 0;
BA_ "GenMsgCycleTime" BO_ 2566671102 1000;
BA_ "GenMsgDelayTime" BO_ 2566671102 100;
BA_ "GenMsgSendType" BO_ 2566671102 0;
BA_ "TpJ1939VarDlc" BO_ 2566670078 1;
BA_ "GenMsgCycleTime" BO_ 2566669054 10000;
BA_ "GenMsgSendType" BO_ 2566669054 0;
BA_ "GenMsgCycleTime" BO_ 2566668798 500;
BA_ "GenMsgSendType" BO_ 2566668798 0;
BA_ "GenMsgCycleTime" BO_ 2566668542 500;
BA_ "GenMsgSendType" BO_ 2566668542 0;
BA_ "GenMsgCycleTime" BO_ 2566668030 1000;
BA_ "GenMsgSendType" BO_ 2566668030 0;
BA_ "GenMsgCycleTime" BO_ 2566667774 1000;
BA_ "GenMsgSendType" BO_ 2566667774 0;
BA_ "GenMsgCycleTime" BO_ 2566667518 1000;
BA_ "GenMsgSendType" BO_ 2566667518 0;
BA_ "GenMsgCycleTime" BO_ 2566667262 1000;
BA_ "GenMsgSendType" BO_ 2566667262 0;
BA_ "GenMsgCycleTime" BO_ 2499558142 500;
BA_ "GenMsgSendType" BO_ 2499558142 0;
BA_ "GenMsgCycleTime" BO_ 2499557886 500;
BA_ "GenMsgSendType" BO_ 2499557886 0;
BA_ "GenMsgCycleTime" BO_ 2499557630 500;
BA_ "GenMsgSendType" BO_ 2499557630 0;
BA_ "GenMsgCycleTime" BO_ 2499557374 500;
BA_ "GenMsgSendType" BO_ 2499557374 0;
BA_ "GenMsgCycleTime" BO_ 2499557118 500;
BA_ "GenMsgSendType" BO_ 2499557118 0;
BA_ "GenMsgCycleTime" BO_ 2566665726 500;
BA_ "GenMsgSendType" BO_ 2566665726 0;
BA_ "GenMsgCycleTime" BO_ 2499556606 500;
BA_ "GenMsgSendType" BO_ 2499556606 0;
BA_ "GenMsgCycleTime" BO_ 2499556350 500;
BA_ "GenMsgSendType" BO_ 2499556350 0;
BA_ "GenMsgCycleTime" BO_ 2499556094 250;
BA_ "GenMsgSendType" BO_ 2499556094 0;
BA_ "GenMsgCycleTime" BO_ 2566664702 1000;
BA_ "GenMsgDelayTime" BO_ 2566664702 100;
BA_ "GenMsgSendType" BO_ 2566664702 0;
BA_ "GenMsgCycleTime" BO_ 2633773054 1000;
BA_ "GenMsgSendType" BO_ 2633773054 0;
BA_ "GenMsgCycleTime" BO_ 2566663934 500;
BA_ "GenMsgSendType" BO_ 2566663934 0;
BA_ "GenMsgCycleTime" BO_ 2566663678 500;
BA_ "GenMsgSendType" BO_ 2566663678 0;
BA_ "GenMsgCycleTime" BO_ 2566663422 1000;
BA_ "GenMsgSendType" BO_ 2566663422 0;
BA_ "GenMsgCycleTime" BO_ 2566663166 1000;
BA_ "GenMsgSendType" BO_ 2566663166 0;
BA_ "GenMsgCycleTime" BO_ 2566662910 10000;
BA_ "GenMsgSendType" BO_ 2566662910 0;
BA_ "GenMsgCycleTime" BO_ 2566662654 100;
BA_ "GenMsgSendType" BO_ 2566662654 0;
BA_ "GenMsgCycleTime" BO_ 2566662142 1000;
BA_ "GenMsgSendType" BO_ 2566662142 0;
BA_ "GenMsgCycleTime" BO_ 2566661630 1000;
BA_ "GenMsgSendType" BO_ 2566661630 0;
BA_ "GenMsgCycleTime" BO_ 2566661374 1000;
BA_ "GenMsgSendType" BO_ 2566661374 0;
BA_ "GenMsgCycleTime" BO_ 2364593150 100;
BA_ "GenMsgSendType" BO_ 2364593150 0;
BA_ "GenMsgCycleTime" BO_ 2364592894 100;
BA_ "GenMsgSendType" BO_ 2364592894 0;
BA_ "GenMsgCycleTime" BO_ 2364592638 100;
BA_ "GenMsgSendType" BO_ 2364592638 0;
BA_ "GenMsgCycleTime" BO_ 2364592382 1000;
BA_ "GenMsgSendType" BO_ 2364592382 0;
BA_ "GenMsgCycleTime" BO_ 2364567294 50;
BA_ "GenMsgSendType" BO_ 2364567294 0;
BA_ "GenMsgCycleTime" BO_ 2558918398 1000;
BA_ "GenMsgDelayTime" BO_ 2558918398 100;
BA_ "GenMsgSendType" BO_ 2558918398 0;
BA_ "GenMsgCycleTime" BO_ 2558852862 200;
BA_ "GenMsgSendType" BO_ 2558852862 0;
BA_ "GenMsgCycleTime" BO_ 2558656254 1000;
BA_ "GenMsgDelayTime" BO_ 2558656254 100;
BA_ "GenMsgSendType" BO_ 2558656254 0;
BA_ "SPN" SG_ 2566687742 HtrRes 7070;
BA_ "SigType" SG_ 2566687742 HtrRes 1;
BA_ "SPN" SG_ 2566687742 MaxRes 6781;
BA_ "SigType" SG_ 2566687742 MaxRes 1;
BA_ "SPN" SG_ 2566687742 Temp 6780;
BA_ "SigType" SG_ 2566687742 Temp 1;
BA_ "SPN" SG_ 2566687742 RegenFailedCount 6779;
BA_ "SigType" SG_ 2566687742 RegenFailedCount 1;
BA_ "SPN" SG_ 2566687742 PwrSupply 6778;
BA_ "SigType" SG_ 2566687742 PwrSupply 4;
BA_ "SPN" SG_ 2566687742 DetectionStatus 6777;
BA_ "SPN" SG_ 2365348350 EngLoadShareStatus 6794;
BA_ "SPN" SG_ 2365348350 EngUnloadStatus 6793;
BA_ "SigType" SG_ 2365348350 EngUnloadStatus 4;
BA_ "SPN" SG_ 2566674686 EngTurbo4LubeOilPress 6813;
BA_ "SigType" SG_ 2566674686 EngTurbo4LubeOilPress 1;
BA_ "SPN" SG_ 2566674686 EngTurbo3LubeOilPress 6812;
BA_ "SigType" SG_ 2566674686 EngTurbo3LubeOilPress 1;
BA_ "SPN" SG_ 2566674686 EngTurbo2LubeOilPress 6811;
BA_ "SigType" SG_ 2566674686 EngTurbo2LubeOilPress 1;
BA_ "SPN" SG_ 2566674430 DslExhstFldQalityMalfunctionTime 6818;
BA_ "SigType" SG_ 2566674430 DslExhstFldQalityMalfunctionTime 1;
BA_ "SPN" SG_ 2566674430 DieselExhaustFluidTank1EmptyTime 6817;
BA_ "SigType" SG_ 2566674430 DieselExhaustFluidTank1EmptyTime 1;
BA_ "SPN" SG_ 2566674174 SCROperatorInducementTotalTime 7095;
BA_ "SigType" SG_ 2566674174 SCROperatorInducementTotalTime 1;
BA_ "SPN" SG_ 2566674174 AFTSCRMalfunctionTime 6819;
BA_ "SigType" SG_ 2566674174 AFTSCRMalfunctionTime 1;
BA_ "SPN" SG_ 2566673406 GasLeakageDetection3Press 6839;
BA_ "SigType" SG_ 2566673406 GasLeakageDetection3Press 1;
BA_ "SPN" SG_ 2566673406 GasLeakageDetection2Press 6838;
BA_ "SigType" SG_ 2566673406 GasLeakageDetection2Press 1;
BA_ "SPN" SG_ 2566673406 GasLeakageDetection1Press 6837;
BA_ "SigType" SG_ 2566673406 GasLeakageDetection1Press 1;
BA_ "SPN" SG_ 2566673406 GasFuelLeakage3Concentration 6836;
BA_ "SigType" SG_ 2566673406 GasFuelLeakage3Concentration 1;
BA_ "SPN" SG_ 2566673406 GasFuelLeakage2Concentration 6835;
BA_ "SigType" SG_ 2566673406 GasFuelLeakage2Concentration 1;
BA_ "SPN" SG_ 2566673406 GasFuelLeakage1Concentration 6834;
BA_ "SigType" SG_ 2566673406 GasFuelLeakage1Concentration 1;
BA_ "SPN" SG_ 2633782014 NetBinWeight 6841;
BA_ "SigType" SG_ 2633782014 NetBinWeight 1;
BA_ "SPN" SG_ 2633782014 BinLiftCount 6840;
BA_ "SigType" SG_ 2633782014 BinLiftCount 1;
BA_ "SPN" SG_ 2633782014 BinWeighingErrorStatus 6842;
BA_ "SPN" SG_ 2633782014 BinInstance 6845;
BA_ "SPN" SG_ 2365346302 LiftAxle2Status 6844;
BA_ "SPN" SG_ 2365346302 LiftAxle1Status 6843;
BA_ "SPN" SG_ 2566672638 DeliveryTransactionStatus 7702;
BA_ "SPN" SG_ 2566672638 DeliveredPayloadConfidence 6850;
BA_ "SigType" SG_ 2566672638 DeliveredPayloadConfidence 1;
BA_ "SPN" SG_ 2566672638 DeliveredPayloadWeight 6849;
BA_ "SPN" SG_ 2566672638 HaulModeStatus 6848;
BA_ "SPN" SG_ 2566672638 HaulCycleCount 6847;
BA_ "SigType" SG_ 2566672638 HaulCycleCount 1;
BA_ "SPN" SG_ 2566672382 PayloadWeightSensor8Status 6862;
BA_ "SigType" SG_ 2566672382 PayloadWeightSensor8Status 5;
BA_ "SPN" SG_ 2566672382 PayloadWeightSensor7Status 6861;
BA_ "SigType" SG_ 2566672382 PayloadWeightSensor7Status 5;
BA_ "SPN" SG_ 2566672382 PayloadWeightSensor6Status 6860;
BA_ "SigType" SG_ 2566672382 PayloadWeightSensor6Status 5;
BA_ "SPN" SG_ 2566672382 PayloadWeightSensor5Status 6859;
BA_ "SigType" SG_ 2566672382 PayloadWeightSensor5Status 5;
BA_ "SPN" SG_ 2566672382 PayloadWeightSensor4Status 6858;
BA_ "SigType" SG_ 2566672382 PayloadWeightSensor4Status 5;
BA_ "SPN" SG_ 2566672382 PayloadWeightSensor3Status 6857;
BA_ "SigType" SG_ 2566672382 PayloadWeightSensor3Status 5;
BA_ "SPN" SG_ 2566672382 PayloadWeightSensor2Status 6856;
BA_ "SigType" SG_ 2566672382 PayloadWeightSensor2Status 5;
BA_ "SPN" SG_ 2566672382 PayloadWeightSensor1Status 6855;
BA_ "SigType" SG_ 2566672382 PayloadWeightSensor1Status 5;
BA_ "SPN" SG_ 2566672126 DEFDoser2Temp 7460;
BA_ "SigType" SG_ 2566672126 DEFDoser2Temp 1;
BA_ "SPN" SG_ 2566672126 DEFDoser2AbsPress 7459;
BA_ "SigType" SG_ 2566672126 DEFDoser2AbsPress 1;
BA_ "SPN" SG_ 2566672126 DEFDosingPress 6875;
BA_ "SigType" SG_ 2566672126 DEFDosingPress 1;
BA_ "SPN" SG_ 2566671870 DEFDosing2Temp 7465;
BA_ "SigType" SG_ 2566671870 DEFDosing2Temp 1;
BA_ "SPN" SG_ 2566671870 DEFDoser2AbsPress 7464;
BA_ "SigType" SG_ 2566671870 DEFDoser2AbsPress 1;
BA_ "SPN" SG_ 2566671870 DEFDosingPress 6876;
BA_ "SigType" SG_ 2566671870 DEFDosingPress 1;
BA_ "SPN" SG_ 2566671614 TtlNmbrOfSCROprtrIndcmntOvrrdEvn 6880;
BA_ "SigType" SG_ 2566671614 TtlNmbrOfSCROprtrIndcmntOvrrdEvn 1;
BA_ "SPN" SG_ 2566671614 NmbrOfSCROprtrIndcmntOvrrdEvntsR 6879;
BA_ "SigType" SG_ 2566671614 NmbrOfSCROprtrIndcmntOvrrdEvntsR 1;
BA_ "SPN" SG_ 2566671614 SCROprtrIndcmntOvrrdTmeRemaining 6878;
BA_ "SigType" SG_ 2566671614 SCROprtrIndcmntOvrrdTmeRemaining 1;
BA_ "SPN" SG_ 2566671614 SCROprtrInducementOverrideEnable 6877;
BA_ "SigType" SG_ 2566671614 SCROprtrInducementOverrideEnable 5;
BA_ "SPN" SG_ 2566671358 CylFuelRate 7333;
BA_ "SigType" SG_ 2566671358 CylFuelRate 1;
BA_ "SPN" SG_ 2566671358 EngExhaustFlowRate 6895;
BA_ "SigType" SG_ 2566671358 EngExhaustFlowRate 1;
BA_ "SPN" SG_ 2566671358 VehicleFuelRate 6894;
BA_ "SigType" SG_ 2566671358 VehicleFuelRate 1;
BA_ "SPN" SG_ 2566671358 PEMSEngFuelMassFlowRate 6893;
BA_ "SigType" SG_ 2566671358 PEMSEngFuelMassFlowRate 1;
BA_ "SPN" SG_ 2566671102 SCRSystemCleaningForcedStatus 6934;
BA_ "SPN" SG_ 2566671102 SCRSystmClnngAtmtcIntationConfig 6933;
BA_ "SigType" SG_ 2566671102 SCRSystmClnngAtmtcIntationConfig 5;
BA_ "SPN" SG_ 2566671102 SCRSystmClnngInhbtdDTVhclSpdBlwA 6932;
BA_ "SigType" SG_ 2566671102 SCRSystmClnngInhbtdDTVhclSpdBlwA 5;
BA_ "SPN" SG_ 2566671102 SCRSystmClnngInhbtdDTEngNtWrmdUp 6931;
BA_ "SigType" SG_ 2566671102 SCRSystmClnngInhbtdDTEngNtWrmdUp 5;
BA_ "SPN" SG_ 2566671102 SCRSystmClnngInhbtdDTPrmnntSystm 6930;
BA_ "SigType" SG_ 2566671102 SCRSystmClnngInhbtdDTPrmnntSystm 5;
BA_ "SPN" SG_ 2566671102 SCRSystmClnngInhbtdDTTmprrySystm 6929;
BA_ "SigType" SG_ 2566671102 SCRSystmClnngInhbtdDTTmprrySystm 5;
BA_ "SPN" SG_ 2566671102 SCRSystmClnngInhbtdDTSystmTmeout 6928;
BA_ "SigType" SG_ 2566671102 SCRSystmClnngInhbtdDTSystmTmeout 5;
BA_ "SPN" SG_ 2566671102 SCRSystmClnngInhbtdDTSystmFltAct 6927;
BA_ "SigType" SG_ 2566671102 SCRSystmClnngInhbtdDTSystmFltAct 5;
BA_ "SPN" SG_ 2566671102 SCRSystmClnngInhbtdDTLwExhstTemp 6926;
BA_ "SigType" SG_ 2566671102 SCRSystmClnngInhbtdDTLwExhstTemp 5;
BA_ "SPN" SG_ 2566671102 SCRSystmClnngInhbtdDTPrkngBrkNtS 6925;
BA_ "SigType" SG_ 2566671102 SCRSystmClnngInhbtdDTPrkngBrkNtS 5;
BA_ "SPN" SG_ 2566671102 SCRSystmClnngInhbtdDTVhclSpdAbvA 6924;
BA_ "SigType" SG_ 2566671102 SCRSystmClnngInhbtdDTVhclSpdAbvA 5;
BA_ "SPN" SG_ 2566671102 SCRSystmClnngInhbtdDTOtOfNeutral 6923;
BA_ "SigType" SG_ 2566671102 SCRSystmClnngInhbtdDTOtOfNeutral 5;
BA_ "SPN" SG_ 2566671102 SCRSystmClnngInhbtdDTAcclPdlOffI 6922;
BA_ "SigType" SG_ 2566671102 SCRSystmClnngInhbtdDTAcclPdlOffI 5;
BA_ "SPN" SG_ 2566671102 SCRSystmClnngInhbtdDeToPTOActive 6921;
BA_ "SigType" SG_ 2566671102 SCRSystmClnngInhbtdDeToPTOActive 5;
BA_ "SPN" SG_ 2566671102 SCRSystmClnngInhbtdDTSrvcBrkActv 6920;
BA_ "SigType" SG_ 2566671102 SCRSystmClnngInhbtdDTSrvcBrkActv 5;
BA_ "SPN" SG_ 2566671102 SCRSystmClnngInhbtdDTCltchDsnggd 6919;
BA_ "SigType" SG_ 2566671102 SCRSystmClnngInhbtdDTCltchDsnggd 5;
BA_ "SPN" SG_ 2566671102 SCRSystmClnngInhbtdDTInhbtSwitch 6918;
BA_ "SigType" SG_ 2566671102 SCRSystmClnngInhbtdDTInhbtSwitch 5;
BA_ "SPN" SG_ 2566671102 SCRSystemCleaningInhibitedStatus 6917;
BA_ "SigType" SG_ 2566671102 SCRSystemCleaningInhibitedStatus 5;
BA_ "SPN" SG_ 2566671102 SCRSystemCleaningStatus 6916;
BA_ "SigType" SG_ 2566671102 SCRSystemCleaningStatus 5;
BA_ "SPN" SG_ 2566671102 SCRSystemCleaningLampCmd 6915;
BA_ "SPN" SG_ 2566670846 SCRSysAvgDistBetweenCleanEvents 6940;
BA_ "SigType" SG_ 2566670846 SCRSysAvgDistBetweenCleanEvents 1;
BA_ "SPN" SG_ 2566670846 SCRSysAvgTimeBetweenCleanEvents 6939;
BA_ "SigType" SG_ 2566670846 SCRSysAvgTimeBetweenCleanEvents 1;
BA_ "SPN" SG_ 2566670846 SCRSysTotalSysCleanManReq 6938;
BA_ "SigType" SG_ 2566670846 SCRSysTotalSysCleanManReq 1;
BA_ "SPN" SG_ 2566670846 SCRSysTotalSysCleanInhReq 6937;
BA_ "SigType" SG_ 2566670846 SCRSysTotalSysCleanInhReq 1;
BA_ "SPN" SG_ 2566670846 SCRSysTotalSysCleanEvents 6936;
BA_ "SigType" SG_ 2566670846 SCRSysTotalSysCleanEvents 1;
BA_ "SPN" SG_ 2566670846 SCRSysTotalCleanTime 6935;
BA_ "SigType" SG_ 2566670846 SCRSysTotalCleanTime 1;
BA_ "SPN" SG_ 2566670590 SCRSysAvgDistBetweenCleanEvents 6947;
BA_ "SigType" SG_ 2566670590 SCRSysAvgDistBetweenCleanEvents 1;
BA_ "SPN" SG_ 2566670590 SCRSysAvgTimeBetweenCleanEvents 6946;
BA_ "SigType" SG_ 2566670590 SCRSysAvgTimeBetweenCleanEvents 1;
BA_ "SPN" SG_ 2566670590 SCRSysTotalSysCleanManReq 6945;
BA_ "SigType" SG_ 2566670590 SCRSysTotalSysCleanManReq 1;
BA_ "SPN" SG_ 2566670590 SCRSysTotalSysCleanInhReq 6944;
BA_ "SigType" SG_ 2566670590 SCRSysTotalSysCleanInhReq 1;
BA_ "SPN" SG_ 2566670590 SCRSysTotalSysCleanEvents 6943;
BA_ "SigType" SG_ 2566670590 SCRSysTotalSysCleanEvents 1;
BA_ "SPN" SG_ 2566670590 SCRSysTotalSysCleanTime 6942;
BA_ "SigType" SG_ 2566670590 SCRSysTotalSysCleanTime 1;
BA_ "SPN" SG_ 2566670334 Axle12MonitoredTireCount 6962;
BA_ "SPN" SG_ 2566670334 Axle11MonitoredTireCount 6961;
BA_ "SPN" SG_ 2566670334 Axle10MonitoredTireCount 6960;
BA_ "SPN" SG_ 2566670334 Axle9MonitoredTireCount 6959;
BA_ "SPN" SG_ 2566670334 Axle8MonitoredTireCount 6958;
BA_ "SPN" SG_ 2566670334 Axle7MonitoredTireCount 6957;
BA_ "SPN" SG_ 2566670334 Axle6MonitoredTireCount 6956;
BA_ "SPN" SG_ 2566670334 Axle5MonitoredTireCount 6955;
BA_ "SPN" SG_ 2566670334 Axle4MonitoredTireCount 6954;
BA_ "SPN" SG_ 2566670334 Axle3MonitoredTireCount 6953;
BA_ "SPN" SG_ 2566670334 Axle2MonitoredTireCount 6952;
BA_ "SPN" SG_ 2566670334 Axle1MonitoredTireCount 6951;
BA_ "SPN" SG_ 2566670334 NumberOfTiresOnTheVehicle 6950;
BA_ "SigType" SG_ 2566670334 NumberOfTiresOnTheVehicle 1;
BA_ "SPN" SG_ 2566670334 NumberOfAxlesOnTheVehicle 6949;
BA_ "SPN" SG_ 2566670078 TireSensorIdentificationNumber 6966;
BA_ "SigType" SG_ 2566670078 TireSensorIdentificationNumber 8;
BA_ "SPN" SG_ 2566670078 TireSensorLocation 6965;
BA_ "SPN" SG_ 2566670078 TireSensorTireNumber 6964;
BA_ "SigType" SG_ 2566670078 TireSensorTireNumber 1;
BA_ "SPN" SG_ 2566670078 NumberOfTireSensors 6963;
BA_ "SigType" SG_ 2566670078 NumberOfTireSensors 1;
BA_ "SPN" SG_ 2566669822 TrWrelessSignalStrengthIndicator 6972;
BA_ "SigType" SG_ 2566669822 TrWrelessSignalStrengthIndicator 1;
BA_ "SPN" SG_ 2566669822 TireLocation 6971;
BA_ "SPN" SG_ 2566669822 TireSensorNumber 6970;
BA_ "SigType" SG_ 2566669822 TireSensorNumber 1;
BA_ "SPN" SG_ 2566669822 TtalNumberOfTireSensorsMonitored 6969;
BA_ "SigType" SG_ 2566669822 TtalNumberOfTireSensorsMonitored 1;
BA_ "SPN" SG_ 2566669822 AntennaNumber 6968;
BA_ "SigType" SG_ 2566669822 AntennaNumber 1;
BA_ "SPN" SG_ 2566669822 TotalNumberOfAntennasUsed 6967;
BA_ "SigType" SG_ 2566669822 TotalNumberOfAntennasUsed 1;
BA_ "SPN" SG_ 2566669310 OverTemp 6984;
BA_ "SigType" SG_ 2566669310 OverTemp 1;
BA_ "SPN" SG_ 2566669310 OverPressPercentageThreshold 6983;
BA_ "SigType" SG_ 2566669310 OverPressPercentageThreshold 1;
BA_ "SPN" SG_ 2566669310 ExtrmUndrPrssPercentageThreshold 6982;
BA_ "SigType" SG_ 2566669310 ExtrmUndrPrssPercentageThreshold 1;
BA_ "SPN" SG_ 2566669310 UnderPressPercentageThreshold 6981;
BA_ "SigType" SG_ 2566669310 UnderPressPercentageThreshold 1;
BA_ "SPN" SG_ 2566669310 ColdInflationPress 6980;
BA_ "SigType" SG_ 2566669310 ColdInflationPress 1;
BA_ "SPN" SG_ 2566669310 TireLocation 6979;
BA_ "SPN" SG_ 2566669054 RequiredTirePress 6989;
BA_ "SigType" SG_ 2566669054 RequiredTirePress 1;
BA_ "SPN" SG_ 2566669054 TirePress 6988;
BA_ "SigType" SG_ 2566669054 TirePress 1;
BA_ "SPN" SG_ 2566669054 TireLocation 6987;
BA_ "SPN" SG_ 2566668798 EngFl2InjctorMeteringRail1Press2 7513;
BA_ "SigType" SG_ 2566668798 EngFl2InjctorMeteringRail1Press2 1;
BA_ "SPN" SG_ 2566668798 EngFel2InjectorMeteringRail2Temp 7024;
BA_ "SigType" SG_ 2566668798 EngFel2InjectorMeteringRail2Temp 1;
BA_ "SPN" SG_ 2566668798 EngFel2InjectorMeteringRail1Temp 7023;
BA_ "SigType" SG_ 2566668798 EngFel2InjectorMeteringRail1Temp 1;
BA_ "SPN" SG_ 2566668798 EngFl2InjectorMeteringRail2Press 7022;
BA_ "SigType" SG_ 2566668798 EngFl2InjectorMeteringRail2Press 1;
BA_ "SPN" SG_ 2566668798 EngFl2InjectorMeteringRail1Press 7021;
BA_ "SigType" SG_ 2566668798 EngFl2InjectorMeteringRail1Press 1;
BA_ "SPN" SG_ 2566668542 EngFuel2PumpHydPress 7019;
BA_ "SigType" SG_ 2566668542 EngFuel2PumpHydPress 1;
BA_ "SPN" SG_ 2566668542 EngFuel2PumpHydDirectionalValve 7018;
BA_ "SigType" SG_ 2566668542 EngFuel2PumpHydDirectionalValve 1;
BA_ "SPN" SG_ 2566668542 EngFuel2PumpHydSwashPlateAngle 7017;
BA_ "SigType" SG_ 2566668542 EngFuel2PumpHydSwashPlateAngle 1;
BA_ "SPN" SG_ 2566668542 EngFuel2PumpHydFlowCtrlValve 7016;
BA_ "SigType" SG_ 2566668542 EngFuel2PumpHydFlowCtrlValve 1;
BA_ "SPN" SG_ 2566668286 EngStagedTurboSolenoidStatus 7025;
BA_ "SigType" SG_ 2566668286 EngStagedTurboSolenoidStatus 1;
BA_ "SPN" SG_ 2566668030 HtExchngerDebrisPurgeApproaching 7036;
BA_ "SigType" SG_ 2566668030 HtExchngerDebrisPurgeApproaching 5;
BA_ "SPN" SG_ 2566668030 HeatExchangerDebrisPurgeStatus 7035;
BA_ "SigType" SG_ 2566668030 HeatExchangerDebrisPurgeStatus 5;
BA_ "SPN" SG_ 2566667774 EngEndBearing8Temp 7050;
BA_ "SigType" SG_ 2566667774 EngEndBearing8Temp 1;
BA_ "SPN" SG_ 2566667774 EngEndBearing7Temp 7049;
BA_ "SigType" SG_ 2566667774 EngEndBearing7Temp 1;
BA_ "SPN" SG_ 2566667774 EngEndBearing6Temp 7048;
BA_ "SigType" SG_ 2566667774 EngEndBearing6Temp 1;
BA_ "SPN" SG_ 2566667774 EngEndBearing5Temp 7047;
BA_ "SigType" SG_ 2566667774 EngEndBearing5Temp 1;
BA_ "SPN" SG_ 2566667774 EngEndBearing4Temp 7046;
BA_ "SigType" SG_ 2566667774 EngEndBearing4Temp 1;
BA_ "SPN" SG_ 2566667774 EngEndBearing3Temp 7045;
BA_ "SigType" SG_ 2566667774 EngEndBearing3Temp 1;
BA_ "SPN" SG_ 2566667774 EngEndBearing2Temp 7044;
BA_ "SigType" SG_ 2566667774 EngEndBearing2Temp 1;
BA_ "SPN" SG_ 2566667774 EngEndBearing1Temp 7043;
BA_ "SigType" SG_ 2566667774 EngEndBearing1Temp 1;
BA_ "SPN" SG_ 2566667518 EngEndBearing16Temp 7058;
BA_ "SigType" SG_ 2566667518 EngEndBearing16Temp 1;
BA_ "SPN" SG_ 2566667518 EngEndBearing15Temp 7057;
BA_ "SigType" SG_ 2566667518 EngEndBearing15Temp 1;
BA_ "SPN" SG_ 2566667518 EngEndBearing14Temp 7056;
BA_ "SigType" SG_ 2566667518 EngEndBearing14Temp 1;
BA_ "SPN" SG_ 2566667518 EngEndBearing13Temp 7055;
BA_ "SigType" SG_ 2566667518 EngEndBearing13Temp 1;
BA_ "SPN" SG_ 2566667518 EngEndBearing12Temp 7054;
BA_ "SigType" SG_ 2566667518 EngEndBearing12Temp 1;
BA_ "SPN" SG_ 2566667518 EngEndBearing11Temp 7053;
BA_ "SigType" SG_ 2566667518 EngEndBearing11Temp 1;
BA_ "SPN" SG_ 2566667518 EngEndBearing10Temp 7052;
BA_ "SigType" SG_ 2566667518 EngEndBearing10Temp 1;
BA_ "SPN" SG_ 2566667518 EngEndBearing9Temp 7051;
BA_ "SigType" SG_ 2566667518 EngEndBearing9Temp 1;
BA_ "SPN" SG_ 2566667262 EngEndBearing20Temp 7062;
BA_ "SigType" SG_ 2566667262 EngEndBearing20Temp 1;
BA_ "SPN" SG_ 2566667262 EngEndBearing19Temp 7061;
BA_ "SigType" SG_ 2566667262 EngEndBearing19Temp 1;
BA_ "SPN" SG_ 2566667262 EngEndBearing18Temp 7060;
BA_ "SigType" SG_ 2566667262 EngEndBearing18Temp 1;
BA_ "SPN" SG_ 2566667262 EngEndBearing17Temp 7059;
BA_ "SigType" SG_ 2566667262 EngEndBearing17Temp 1;
BA_ "SPN" SG_ 2499558142 GsFlSpplyShtoffValve2IntakePress 7066;
BA_ "SigType" SG_ 2499558142 GsFlSpplyShtoffValve2IntakePress 1;
BA_ "SPN" SG_ 2499558142 GsFlSpplyShtoffValve1IntakePress 7065;
BA_ "SigType" SG_ 2499558142 GsFlSpplyShtoffValve1IntakePress 1;
BA_ "SPN" SG_ 2499558142 GasFuelSupplyUnitIntakePress 7064;
BA_ "SigType" SG_ 2499558142 GasFuelSupplyUnitIntakePress 1;
BA_ "SPN" SG_ 2499558142 EngGasFuelSupplyPress2 7063;
BA_ "SigType" SG_ 2499558142 EngGasFuelSupplyPress2 1;
BA_ "SPN" SG_ 2499557886 PlantInertGasSupplyOutletPress 7068;
BA_ "SigType" SG_ 2499557886 PlantInertGasSupplyOutletPress 1;
BA_ "SPN" SG_ 2499557886 PlantGasFuelSupplyOutletPress 7067;
BA_ "SigType" SG_ 2499557886 PlantGasFuelSupplyOutletPress 1;
BA_ "SPN" SG_ 2499557630 EngOilMist8Concentration 7078;
BA_ "SigType" SG_ 2499557630 EngOilMist8Concentration 1;
BA_ "SPN" SG_ 2499557630 EngOilMist7Concentration 7077;
BA_ "SigType" SG_ 2499557630 EngOilMist7Concentration 1;
BA_ "SPN" SG_ 2499557630 EngOilMist6Concentration 7076;
BA_ "SigType" SG_ 2499557630 EngOilMist6Concentration 1;
BA_ "SPN" SG_ 2499557630 EngOilMist5Concentration 7075;
BA_ "SigType" SG_ 2499557630 EngOilMist5Concentration 1;
BA_ "SPN" SG_ 2499557630 EngOilMist4Concentration 7074;
BA_ "SigType" SG_ 2499557630 EngOilMist4Concentration 1;
BA_ "SPN" SG_ 2499557630 EngOilMist3Concentration 7073;
BA_ "SigType" SG_ 2499557630 EngOilMist3Concentration 1;
BA_ "SPN" SG_ 2499557630 EngOilMist2Concentration 7072;
BA_ "SigType" SG_ 2499557630 EngOilMist2Concentration 1;
BA_ "SPN" SG_ 2499557630 EngOilMist1Concentration 7071;
BA_ "SigType" SG_ 2499557630 EngOilMist1Concentration 1;
BA_ "SPN" SG_ 2499557374 EngOilMist10Concentration 7080;
BA_ "SigType" SG_ 2499557374 EngOilMist10Concentration 1;
BA_ "SPN" SG_ 2499557374 EngOilMist9Concentration 7079;
BA_ "SigType" SG_ 2499557374 EngOilMist9Concentration 1;
BA_ "SPN" SG_ 2499557118 InertGasSupplyValvePos 7442;
BA_ "SigType" SG_ 2499557118 InertGasSupplyValvePos 1;
BA_ "SPN" SG_ 2499557118 GasFuelSupplyBleedValve3Pos 7085;
BA_ "SigType" SG_ 2499557118 GasFuelSupplyBleedValve3Pos 1;
BA_ "SPN" SG_ 2499557118 GasFuelSupplyBleedValve2Pos 7084;
BA_ "SigType" SG_ 2499557118 GasFuelSupplyBleedValve2Pos 1;
BA_ "SPN" SG_ 2499557118 GasFuelSupplyBleedValve1Pos 7083;
BA_ "SigType" SG_ 2499557118 GasFuelSupplyBleedValve1Pos 1;
BA_ "SPN" SG_ 2499557118 GasFuelSupplyShutoffValve2Pos 7082;
BA_ "SigType" SG_ 2499557118 GasFuelSupplyShutoffValve2Pos 1;
BA_ "SPN" SG_ 2499557118 GasFuelSupplyShutoffValve1Pos 7081;
BA_ "SigType" SG_ 2499557118 GasFuelSupplyShutoffValve1Pos 1;
BA_ "SPN" SG_ 2566665726 TwoMotorSpd 7466;
BA_ "SigType" SG_ 2566665726 TwoMotorSpd 1;
BA_ "SPN" SG_ 2566665726 Htr 7086;
BA_ "SigType" SG_ 2566665726 Htr 1;
BA_ "SPN" SG_ 2499556606 EngInjectorMeteringRail2Press2 7099;
BA_ "SigType" SG_ 2499556606 EngInjectorMeteringRail2Press2 1;
BA_ "SPN" SG_ 2499556606 EngInjectorMeteringRail2Press1 7098;
BA_ "SigType" SG_ 2499556606 EngInjectorMeteringRail2Press1 1;
BA_ "SPN" SG_ 2499556606 EngInjectorMeteringRail1Press2 7097;
BA_ "SigType" SG_ 2499556606 EngInjectorMeteringRail1Press2 1;
BA_ "SPN" SG_ 2499556606 EngInjectorMeteringRail1Press1 7096;
BA_ "SigType" SG_ 2499556606 EngInjectorMeteringRail1Press1 1;
BA_ "SPN" SG_ 2499556350 EngInjctrMtringRail2DesiredPress 7101;
BA_ "SigType" SG_ 2499556350 EngInjctrMtringRail2DesiredPress 1;
BA_ "SPN" SG_ 2499556350 EngInjctrMtringRail1DesiredPress 7100;
BA_ "SigType" SG_ 2499556350 EngInjctrMtringRail1DesiredPress 1;
BA_ "SPN" SG_ 2499556094 HtrPwrSupplyDiagnosticStatus 7330;
BA_ "SPN" SG_ 2499556094 HtrPwrSupplyPreliminaryFMI 7329;
BA_ "SPN" SG_ 2499556094 PwrSupplyDiagnosticStatus 7328;
BA_ "SPN" SG_ 2499556094 PwrSupplyPreliminaryFMI 7327;
BA_ "SPN" SG_ 2499556094 InputDiagnosticStatus 7326;
BA_ "SPN" SG_ 2499556094 InputPreliminaryFMI 7325;
BA_ "SPN" SG_ 2499556094 HtrLowSideDriverDiagnosticStatus 7324;
BA_ "SPN" SG_ 2499556094 HtrLowSideDriverPreliminaryFMI 7323;
BA_ "SPN" SG_ 2499556094 HtrHiSideDriverDiagnosticStatus 7322;
BA_ "SPN" SG_ 2499556094 HtrHiSideDriverPreliminaryFMI 7321;
BA_ "SPN" SG_ 2566664702 DEFTankTemp 7607;
BA_ "SigType" SG_ 2566664702 DEFTankTemp 1;
BA_ "SPN" SG_ 2566664702 DEFTankVolume 7606;
BA_ "SigType" SG_ 2566664702 DEFTankVolume 1;
BA_ "SPN" SG_ 2566664702 DEFHtrCircuitBreaker 7588;
BA_ "SigType" SG_ 2566664702 DEFHtrCircuitBreaker 5;
BA_ "SPN" SG_ 2566664702 AAT 7441;
BA_ "SigType" SG_ 2566664702 AAT 1;
BA_ "SPN" SG_ 2566664702 EngLoadReq 7503;
BA_ "SigType" SG_ 2566664702 EngLoadReq 5;
BA_ "SPN" SG_ 2566664702 EngSpdIncreaseReq 7502;
BA_ "SigType" SG_ 2566664702 EngSpdIncreaseReq 5;
BA_ "SPN" SG_ 2566664702 ActiveRegenInhibitedDueToLowEP 7440;
BA_ "SigType" SG_ 2566664702 ActiveRegenInhibitedDueToLowEP 5;
BA_ "SPN" SG_ 2566664702 ThermalManagementStatus 7332;
BA_ "SigType" SG_ 2566664702 ThermalManagementStatus 5;
BA_ "SPN" SG_ 2633773310 SCROprtrIndcmntOvrrdTmeRemaining 7344;
BA_ "SigType" SG_ 2633773310 SCROprtrIndcmntOvrrdTmeRemaining 1;
BA_ "SPN" SG_ 2633773310 SCROprtrIndcmntOvrrdRnwlRequired 7343;
BA_ "SigType" SG_ 2633773310 SCROprtrIndcmntOvrrdRnwlRequired 5;
BA_ "SPN" SG_ 2633773310 SCROpratorInducementOverrideMode 7342;
BA_ "SPN" SG_ 2633773310 SCROprtrIndcmntEmrgncyOvrrdTtlRs 7341;
BA_ "SigType" SG_ 2633773310 SCROprtrIndcmntEmrgncyOvrrdTtlRs 1;
BA_ "SPN" SG_ 2633773054 FrSpprssnCmprssdArFmSystmArPress 7350;
BA_ "SigType" SG_ 2633773054 FrSpprssnCmprssdArFmSystmArPress 1;
BA_ "SPN" SG_ 2633773054 FrSuppressionClassBFoamTankLevel 7349;
BA_ "SigType" SG_ 2633773054 FrSuppressionClassBFoamTankLevel 1;
BA_ "SPN" SG_ 2633773054 FrSuppressionClassAFoamTankLevel 7348;
BA_ "SigType" SG_ 2633773054 FrSuppressionClassAFoamTankLevel 1;
BA_ "SPN" SG_ 2633773054 FireSuppressionWaterTankLevel 7347;
BA_ "SigType" SG_ 2633773054 FireSuppressionWaterTankLevel 1;
BA_ "SPN" SG_ 2566663934 WastegateAct2MotorCurDis 7710;
BA_ "SigType" SG_ 2566663934 WastegateAct2MotorCurDis 5;
BA_ "SPN" SG_ 2566663934 CompressorBypassAct2MotorCurDis 7709;
BA_ "SigType" SG_ 2566663934 CompressorBypassAct2MotorCurDis 5;
BA_ "SPN" SG_ 2566663934 CompressorBypassAct1MotorCurDis 7708;
BA_ "SigType" SG_ 2566663934 CompressorBypassAct1MotorCurDis 5;
BA_ "SPN" SG_ 2566663934 EngThrttlVlv1MotorCurrentDisable 7383;
BA_ "SigType" SG_ 2566663934 EngThrttlVlv1MotorCurrentDisable 5;
BA_ "SPN" SG_ 2566663934 EngCylHdBypssActtr1MtrCrrntDsble 7382;
BA_ "SigType" SG_ 2566663934 EngCylHdBypssActtr1MtrCrrntDsble 5;
BA_ "SPN" SG_ 2566663934 EngTrbWstgtActtr1MtrCrrntDisable 7381;
BA_ "SigType" SG_ 2566663934 EngTrbWstgtActtr1MtrCrrntDisable 5;
BA_ "SPN" SG_ 2566663934 EngTrbCmprssrBlwffActtr1MtrCrrnt 7380;
BA_ "SigType" SG_ 2566663934 EngTrbCmprssrBlwffActtr1MtrCrrnt 5;
BA_ "SPN" SG_ 2566663678 EngFl2InjectorMeteringRail1Temp2 7514;
BA_ "SigType" SG_ 2566663678 EngFl2InjectorMeteringRail1Temp2 1;
BA_ "SPN" SG_ 2566663678 LNGTank2VaporPress 6788;
BA_ "SigType" SG_ 2566663678 LNGTank2VaporPress 1;
BA_ "SPN" SG_ 2566663678 LNGTank1VaporPress 6787;
BA_ "SigType" SG_ 2566663678 LNGTank1VaporPress 1;
BA_ "SPN" SG_ 2566663422 TrlrBrkClprLnngClranceAxle5Right 7415;
BA_ "SigType" SG_ 2566663422 TrlrBrkClprLnngClranceAxle5Right 4;
BA_ "SPN" SG_ 2566663422 TrlrBrkClprLnngClaranceAxle5Left 7414;
BA_ "SigType" SG_ 2566663422 TrlrBrkClprLnngClaranceAxle5Left 4;
BA_ "SPN" SG_ 2566663422 TrlrBrkClprLnngClranceAxle4Right 7413;
BA_ "SigType" SG_ 2566663422 TrlrBrkClprLnngClranceAxle4Right 4;
BA_ "SPN" SG_ 2566663422 TrlrBrkClprLnngClaranceAxle4Left 7412;
BA_ "SigType" SG_ 2566663422 TrlrBrkClprLnngClaranceAxle4Left 4;
BA_ "SPN" SG_ 2566663422 TrlrBrkClprLnngClranceAxle3Right 7411;
BA_ "SigType" SG_ 2566663422 TrlrBrkClprLnngClranceAxle3Right 4;
BA_ "SPN" SG_ 2566663422 TrlrBrkClprLnngClaranceAxle3Left 7410;
BA_ "SigType" SG_ 2566663422 TrlrBrkClprLnngClaranceAxle3Left 4;
BA_ "SPN" SG_ 2566663422 TrlrBrkClprLnngClranceAxle2Right 7409;
BA_ "SigType" SG_ 2566663422 TrlrBrkClprLnngClranceAxle2Right 4;
BA_ "SPN" SG_ 2566663422 TrlrBrkClprLnngClaranceAxle2Left 7408;
BA_ "SigType" SG_ 2566663422 TrlrBrkClprLnngClaranceAxle2Left 4;
BA_ "SPN" SG_ 2566663422 TrlrBrkClprLnngClranceAxle1Right 7407;
BA_ "SigType" SG_ 2566663422 TrlrBrkClprLnngClranceAxle1Right 4;
BA_ "SPN" SG_ 2566663422 TrlrBrkClprLnngClaranceAxle1Left 7406;
BA_ "SigType" SG_ 2566663422 TrlrBrkClprLnngClaranceAxle1Left 4;
BA_ "SPN" SG_ 2566663422 TrctrBrkClprLnngClrnceAxle5Right 7405;
BA_ "SigType" SG_ 2566663422 TrctrBrkClprLnngClrnceAxle5Right 4;
BA_ "SPN" SG_ 2566663422 TrctrBrkClprLnngClranceAxle5Left 7404;
BA_ "SigType" SG_ 2566663422 TrctrBrkClprLnngClranceAxle5Left 4;
BA_ "SPN" SG_ 2566663422 TrctrBrkClprLnngClrnceAxle4Right 7403;
BA_ "SigType" SG_ 2566663422 TrctrBrkClprLnngClrnceAxle4Right 4;
BA_ "SPN" SG_ 2566663422 TrctrBrkClprLnngClranceAxle4Left 7402;
BA_ "SigType" SG_ 2566663422 TrctrBrkClprLnngClranceAxle4Left 4;
BA_ "SPN" SG_ 2566663422 TrctrBrkClprLnngClrnceAxle3Right 7401;
BA_ "SigType" SG_ 2566663422 TrctrBrkClprLnngClrnceAxle3Right 4;
BA_ "SPN" SG_ 2566663422 TrctrBrkClprLnngClranceAxle3Left 7400;
BA_ "SigType" SG_ 2566663422 TrctrBrkClprLnngClranceAxle3Left 4;
BA_ "SPN" SG_ 2566663422 TrctrBrkClprLnngClrnceAxle2Right 7399;
BA_ "SigType" SG_ 2566663422 TrctrBrkClprLnngClrnceAxle2Right 4;
BA_ "SPN" SG_ 2566663422 TrctrBrkClprLnngClranceAxle2Left 7398;
BA_ "SigType" SG_ 2566663422 TrctrBrkClprLnngClranceAxle2Left 4;
BA_ "SPN" SG_ 2566663422 TrctrBrkClprLnngClrnceAxle1Right 7397;
BA_ "SigType" SG_ 2566663422 TrctrBrkClprLnngClrnceAxle1Right 4;
BA_ "SPN" SG_ 2566663422 TrctrBrkClprLnngClranceAxle1Left 7396;
BA_ "SigType" SG_ 2566663422 TrctrBrkClprLnngClranceAxle1Left 4;
BA_ "SPN" SG_ 2566663166 CruiseCtrlAdjustedMaxSpeed 7495;
BA_ "SigType" SG_ 2566663166 CruiseCtrlAdjustedMaxSpeed 1;
BA_ "SPN" SG_ 2566663166 AppliedVehicleSpeedLimit 7420;
BA_ "SigType" SG_ 2566663166 AppliedVehicleSpeedLimit 1;
BA_ "SPN" SG_ 2566662910 TimeToFinalIndAction 7719;
BA_ "SigType" SG_ 2566662910 TimeToFinalIndAction 1;
BA_ "SPN" SG_ 2566662910 OprtrIndcmntTmTTrqueDerateLevel2 7428;
BA_ "SigType" SG_ 2566662910 OprtrIndcmntTmTTrqueDerateLevel2 1;
BA_ "SPN" SG_ 2566662910 OprtrIndcementTorqueDerateLevel2 7427;
BA_ "SigType" SG_ 2566662910 OprtrIndcementTorqueDerateLevel2 1;
BA_ "SPN" SG_ 2566662910 OprtrIndcmntTmTTrqueDerateLevel1 7426;
BA_ "SigType" SG_ 2566662910 OprtrIndcmntTmTTrqueDerateLevel1 1;
BA_ "SPN" SG_ 2566662910 OprtrIndcementTorqueDerateLevel1 7425;
BA_ "SigType" SG_ 2566662910 OprtrIndcementTorqueDerateLevel1 1;
BA_ "SPN" SG_ 2566662654 LaneMarkQualityOnTheRightSide 7482;
BA_ "SPN" SG_ 2566662654 LaneMarkQualityOnTheLeftSide 7481;
BA_ "SPN" SG_ 2566662654 LaneDepartureAngleRight 7480;
BA_ "SigType" SG_ 2566662654 LaneDepartureAngleRight 1;
BA_ "SPN" SG_ 2566662654 LaneDepartureAngleLeft 7479;
BA_ "SigType" SG_ 2566662654 LaneDepartureAngleLeft 1;
BA_ "SPN" SG_ 2566662654 RoadCurvatureBasedOnLaneMarks 7478;
BA_ "SigType" SG_ 2566662654 RoadCurvatureBasedOnLaneMarks 1;
BA_ "SPN" SG_ 2566662654 RghtDstncTLnMrkFrmVehiclesMiddle 7477;
BA_ "SigType" SG_ 2566662654 RghtDstncTLnMrkFrmVehiclesMiddle 1;
BA_ "SPN" SG_ 2566662654 LftDstncTLnMrkFromVehiclesMiddle 7476;
BA_ "SigType" SG_ 2566662654 LftDstncTLnMrkFromVehiclesMiddle 1;
BA_ "SPN" SG_ 2566662142 Ctrl2Temp 7528;
BA_ "SigType" SG_ 2566662142 Ctrl2Temp 1;
BA_ "SPN" SG_ 2566662142 Ctrl1Temp 5480;
BA_ "SigType" SG_ 2566662142 Ctrl1Temp 1;
BA_ "SPN" SG_ 2566661630 Htr2 7573;
BA_ "SigType" SG_ 2566661630 Htr2 1;
BA_ "SPN" SG_ 2566661630 Temp2 7572;
BA_ "SigType" SG_ 2566661630 Temp2 1;
BA_ "SPN" SG_ 2566661630 Volume2 7530;
BA_ "SigType" SG_ 2566661630 Volume2 1;
BA_ "SPN" SG_ 2566661374 Ctrl2Temp 7535;
BA_ "SigType" SG_ 2566661374 Ctrl2Temp 1;
BA_ "SPN" SG_ 2566661374 CtrlTemp 7529;
BA_ "SigType" SG_ 2566661374 CtrlTemp 1;
BA_ "SPN" SG_ 2566661374 Htr2 7575;
BA_ "SigType" SG_ 2566661374 Htr2 1;
BA_ "SPN" SG_ 2566661374 Temp2 7574;
BA_ "SigType" SG_ 2566661374 Temp2 1;
BA_ "SPN" SG_ 2566661374 Volume2 7531;
BA_ "SigType" SG_ 2566661374 Volume2 1;
BA_ "SPN" SG_ 2364598270 EngCyl24TimingOffset 7379;
BA_ "SigType" SG_ 2364598270 EngCyl24TimingOffset 1;
BA_ "SPN" SG_ 2364598270 EngCyl23TimingOffset 7378;
BA_ "SigType" SG_ 2364598270 EngCyl23TimingOffset 1;
BA_ "SPN" SG_ 2364598270 EngCyl22TimingOffset 7377;
BA_ "SigType" SG_ 2364598270 EngCyl22TimingOffset 1;
BA_ "SPN" SG_ 2364598270 EngCyl21TimingOffset 7376;
BA_ "SigType" SG_ 2364598270 EngCyl21TimingOffset 1;
BA_ "SPN" SG_ 2364598270 EngCyl20TimingOffset 7375;
BA_ "SigType" SG_ 2364598270 EngCyl20TimingOffset 1;
BA_ "SPN" SG_ 2364598270 EngCyl19TimingOffset 7374;
BA_ "SigType" SG_ 2364598270 EngCyl19TimingOffset 1;
BA_ "SPN" SG_ 2364598270 EngCyl18TimingOffset 7373;
BA_ "SigType" SG_ 2364598270 EngCyl18TimingOffset 1;
BA_ "SPN" SG_ 2364598270 EngCyl17TimingOffset 7372;
BA_ "SigType" SG_ 2364598270 EngCyl17TimingOffset 1;
BA_ "SPN" SG_ 2364598014 EngCyl16TimingOffset 7371;
BA_ "SigType" SG_ 2364598014 EngCyl16TimingOffset 1;
BA_ "SPN" SG_ 2364598014 EngCyl15TimingOffset 7370;
BA_ "SigType" SG_ 2364598014 EngCyl15TimingOffset 1;
BA_ "SPN" SG_ 2364598014 EngCyl14TimingOffset 7369;
BA_ "SigType" SG_ 2364598014 EngCyl14TimingOffset 1;
BA_ "SPN" SG_ 2364598014 EngCyl13TimingOffset 7368;
BA_ "SigType" SG_ 2364598014 EngCyl13TimingOffset 1;
BA_ "SPN" SG_ 2364598014 EngCyl12TimingOffset 7367;
BA_ "SigType" SG_ 2364598014 EngCyl12TimingOffset 1;
BA_ "SPN" SG_ 2364598014 EngCyl11TimingOffset 7366;
BA_ "SigType" SG_ 2364598014 EngCyl11TimingOffset 1;
BA_ "SPN" SG_ 2364598014 EngCyl10TimingOffset 7365;
BA_ "SigType" SG_ 2364598014 EngCyl10TimingOffset 1;
BA_ "SPN" SG_ 2364598014 EngCyl9TimingOffset 7364;
BA_ "SigType" SG_ 2364598014 EngCyl9TimingOffset 1;
BA_ "SPN" SG_ 2364597758 EngCyl8TimingOffset 7363;
BA_ "SigType" SG_ 2364597758 EngCyl8TimingOffset 1;
BA_ "SPN" SG_ 2364597758 EngCyl7TimingOffset 7362;
BA_ "SigType" SG_ 2364597758 EngCyl7TimingOffset 1;
BA_ "SPN" SG_ 2364597758 EngCyl6TimingOffset 7361;
BA_ "SigType" SG_ 2364597758 EngCyl6TimingOffset 1;
BA_ "SPN" SG_ 2364597758 EngCyl5TimingOffset 7360;
BA_ "SigType" SG_ 2364597758 EngCyl5TimingOffset 1;
BA_ "SPN" SG_ 2364597758 EngCyl4TimingOffset 7359;
BA_ "SigType" SG_ 2364597758 EngCyl4TimingOffset 1;
BA_ "SPN" SG_ 2364597758 EngCyl3TimingOffset 7358;
BA_ "SigType" SG_ 2364597758 EngCyl3TimingOffset 1;
BA_ "SPN" SG_ 2364597758 EngCyl2TimingOffset 7357;
BA_ "SigType" SG_ 2364597758 EngCyl2TimingOffset 1;
BA_ "SPN" SG_ 2364597758 EngCyl1TimingOffset 7356;
BA_ "SigType" SG_ 2364597758 EngCyl1TimingOffset 1;
BA_ "SPN" SG_ 2364593150 PrdctvCrsCtrlDrvlnDsnggInhibitRq 7430;
BA_ "SigType" SG_ 2364593150 PrdctvCrsCtrlDrvlnDsnggInhibitRq 5;
BA_ "SPN" SG_ 2364593150 VhclSpdCtrlOvrrideEventIndicator 7435;
BA_ "SigType" SG_ 2364593150 VhclSpdCtrlOvrrideEventIndicator 5;
BA_ "SPN" SG_ 2364593150 PrdctvCrsCtrlSpeedEventIndicator 7434;
BA_ "SigType" SG_ 2364593150 PrdctvCrsCtrlSpeedEventIndicator 5;
BA_ "SPN" SG_ 2364593150 PredictiveCruiseCtrlNextGrade 7433;
BA_ "SigType" SG_ 2364593150 PredictiveCruiseCtrlNextGrade 1;
BA_ "SPN" SG_ 2364593150 PredictiveCruiseCtrlPresentGrade 7432;
BA_ "SigType" SG_ 2364593150 PredictiveCruiseCtrlPresentGrade 1;
BA_ "SPN" SG_ 2364593150 PredictiveCruiseCtrlEventInRange 7431;
BA_ "SigType" SG_ 2364593150 PredictiveCruiseCtrlEventInRange 4;
BA_ "SPN" SG_ 2364593150 VehicleSpeedCtrlOverrideRq 7429;
BA_ "SigType" SG_ 2364593150 VehicleSpeedCtrlOverrideRq 5;
BA_ "SPN" SG_ 2364593150 PredictiveCruiseCtrlState 7317;
BA_ "SPN" SG_ 2364593150 PrdctiveCruiseCtrlSetSpeedOffset 7316;
BA_ "SigType" SG_ 2364593150 PrdctiveCruiseCtrlSetSpeedOffset 1;
BA_ "SPN" SG_ 2364592894 InAirSourceVlv 6330;
BA_ "SigType" SG_ 2364592894 InAirSourceVlv 4;
BA_ "SPN" SG_ 2364592894 EngCylHeadBypassActuator1Cmd 7094;
BA_ "SigType" SG_ 2364592894 EngCylHeadBypassActuator1Cmd 1;
BA_ "SPN" SG_ 2364592638 EngCylHdBypssActtr1OprtionStatus 7093;
BA_ "SPN" SG_ 2364592638 EngCylHeadBypassActuator1Pos 7092;
BA_ "SigType" SG_ 2364592638 EngCylHeadBypassActuator1Pos 1;
BA_ "SPN" SG_ 2364592638 EngCylHdBypssActuator1DesiredPos 7091;
BA_ "SigType" SG_ 2364592638 EngCylHdBypssActuator1DesiredPos 1;
BA_ "SPN" SG_ 2364592638 EngCylHeadBypassActuator1Temp 7090;
BA_ "SigType" SG_ 2364592638 EngCylHeadBypassActuator1Temp 1;
BA_ "SPN" SG_ 2364592638 EngCylHdBypssActuator1TempStatus 7089;
BA_ "SPN" SG_ 2364592638 EngCylHdBypssActtr1PrliminaryFMI 7088;
BA_ "SPN" SG_ 2364592382 EngCyl24ExcludeFromCombustionRq 7015;
BA_ "SigType" SG_ 2364592382 EngCyl24ExcludeFromCombustionRq 5;
BA_ "SPN" SG_ 2364592382 EngCyl23ExcludeFromCombustionRq 7014;
BA_ "SigType" SG_ 2364592382 EngCyl23ExcludeFromCombustionRq 5;
BA_ "SPN" SG_ 2364592382 EngCyl22ExcludeFromCombustionRq 7013;
BA_ "SigType" SG_ 2364592382 EngCyl22ExcludeFromCombustionRq 5;
BA_ "SPN" SG_ 2364592382 EngCyl21ExcludeFromCombustionRq 7012;
BA_ "SigType" SG_ 2364592382 EngCyl21ExcludeFromCombustionRq 5;
BA_ "SPN" SG_ 2364592382 EngCyl20ExcludeFromCombustionRq 7011;
BA_ "SigType" SG_ 2364592382 EngCyl20ExcludeFromCombustionRq 5;
BA_ "SPN" SG_ 2364592382 EngCyl19ExcludeFromCombustionRq 7010;
BA_ "SigType" SG_ 2364592382 EngCyl19ExcludeFromCombustionRq 5;
BA_ "SPN" SG_ 2364592382 EngCyl18ExcludeFromCombustionRq 7009;
BA_ "SigType" SG_ 2364592382 EngCyl18ExcludeFromCombustionRq 5;
BA_ "SPN" SG_ 2364592382 EngCyl17ExcludeFromCombustionRq 7008;
BA_ "SigType" SG_ 2364592382 EngCyl17ExcludeFromCombustionRq 5;
BA_ "SPN" SG_ 2364592382 EngCyl16ExcludeFromCombustionRq 7007;
BA_ "SigType" SG_ 2364592382 EngCyl16ExcludeFromCombustionRq 5;
BA_ "SPN" SG_ 2364592382 EngCyl15ExcludeFromCombustionRq 7006;
BA_ "SigType" SG_ 2364592382 EngCyl15ExcludeFromCombustionRq 5;
BA_ "SPN" SG_ 2364592382 EngCyl14ExcludeFromCombustionRq 7005;
BA_ "SigType" SG_ 2364592382 EngCyl14ExcludeFromCombustionRq 5;
BA_ "SPN" SG_ 2364592382 EngCyl13ExcludeFromCombustionRq 7004;
BA_ "SigType" SG_ 2364592382 EngCyl13ExcludeFromCombustionRq 5;
BA_ "SPN" SG_ 2364592382 EngCyl12ExcludeFromCombustionRq 7003;
BA_ "SigType" SG_ 2364592382 EngCyl12ExcludeFromCombustionRq 5;
BA_ "SPN" SG_ 2364592382 EngCyl11ExcludeFromCombustionRq 7002;
BA_ "SigType" SG_ 2364592382 EngCyl11ExcludeFromCombustionRq 5;
BA_ "SPN" SG_ 2364592382 EngCyl10ExcludeFromCombustionRq 7001;
BA_ "SigType" SG_ 2364592382 EngCyl10ExcludeFromCombustionRq 5;
BA_ "SPN" SG_ 2364592382 EngCyl9ExcludeFromCombustionRq 7000;
BA_ "SigType" SG_ 2364592382 EngCyl9ExcludeFromCombustionRq 5;
BA_ "SPN" SG_ 2364592382 EngCyl8ExcludeFromCombustionRq 6999;
BA_ "SigType" SG_ 2364592382 EngCyl8ExcludeFromCombustionRq 5;
BA_ "SPN" SG_ 2364592382 EngCyl7ExcludeFromCombustionRq 6998;
BA_ "SigType" SG_ 2364592382 EngCyl7ExcludeFromCombustionRq 5;
BA_ "SPN" SG_ 2364592382 EngCyl6ExcludeFromCombustionRq 6997;
BA_ "SigType" SG_ 2364592382 EngCyl6ExcludeFromCombustionRq 5;
BA_ "SPN" SG_ 2364592382 EngCyl5ExcludeFromCombustionRq 6996;
BA_ "SigType" SG_ 2364592382 EngCyl5ExcludeFromCombustionRq 5;
BA_ "SPN" SG_ 2364592382 EngCyl4ExcludeFromCombustionRq 6995;
BA_ "SigType" SG_ 2364592382 EngCyl4ExcludeFromCombustionRq 5;
BA_ "SPN" SG_ 2364592382 EngCyl3ExcludeFromCombustionRq 6994;
BA_ "SigType" SG_ 2364592382 EngCyl3ExcludeFromCombustionRq 5;
BA_ "SPN" SG_ 2364592382 EngCyl2ExcludeFromCombustionRq 6993;
BA_ "SigType" SG_ 2364592382 EngCyl2ExcludeFromCombustionRq 5;
BA_ "SPN" SG_ 2364592382 EngCyl1ExcludeFromCombustionRq 6992;
BA_ "SigType" SG_ 2364592382 EngCyl1ExcludeFromCombustionRq 5;
BA_ "SPN" SG_ 2364592382 NmbrOfEngCylndrsTExcldFrmCmbston 6991;
BA_ "SigType" SG_ 2364592382 NmbrOfEngCylndrsTExcldFrmCmbston 1;
BA_ "SPN" SG_ 2364567294 EngFlInjctnPump2FuelCtrlValveCmd 6720;
BA_ "SigType" SG_ 2364567294 EngFlInjctnPump2FuelCtrlValveCmd 1;
BA_ "SPN" SG_ 2364567294 EngFlInjctnPump1FuelCtrlValveCmd 6719;
BA_ "SigType" SG_ 2364567294 EngFlInjctnPump1FuelCtrlValveCmd 1;
BA_ "SPN" SG_ 2558918398 TransAutoNeutralEnableSw_7694 7694;
BA_ "SigType" SG_ 2558918398 TransAutoNeutralEnableSw_7694 5;
BA_ "SPN" SG_ 2558918398 AFTRegenEngSpdAllwdSw_7580 7580;
BA_ "SigType" SG_ 2558918398 AFTRegenEngSpdAllwdSw_7580 4;
BA_ "SPN" SG_ 2558918398 ElevatedEngSpdAllowedSw_7579 7579;
BA_ "SigType" SG_ 2558918398 ElevatedEngSpdAllowedSw_7579 4;
BA_ "SPN" SG_ 2558918398 PrdctvCriseCtrlMaxNgtvOffst_7439 7439;
BA_ "SigType" SG_ 2558918398 PrdctvCriseCtrlMaxNgtvOffst_7439 1;
BA_ "SPN" SG_ 2558918398 PrdctvCriseCtrlMaxPstvOfst_7438 7438;
BA_ "SigType" SG_ 2558918398 PrdctvCriseCtrlMaxPstvOfst_7438 1;
BA_ "SPN" SG_ 2558918398 PrdctiveCruiseCtrlDactivnRq_7437 7437;
BA_ "SigType" SG_ 2558918398 PrdctiveCruiseCtrlDactivnRq_7437 4;
BA_ "SPN" SG_ 2558918398 PredictiveCruiseCtrlEnblSw_7436 7436;
BA_ "SigType" SG_ 2558918398 PredictiveCruiseCtrlEnblSw_7436 4;
BA_ "SPN" SG_ 2558918398 HtExchngerDebrisPurgForceSw_7034 7034;
BA_ "SigType" SG_ 2558918398 HtExchngerDebrisPurgForceSw_7034 4;
BA_ "SPN" SG_ 2558918398 HtExchngrDbrisPurgeInhbitSw_7033 7033;
BA_ "SigType" SG_ 2558918398 HtExchngrDbrisPurgeInhbitSw_7033 4;
BA_ "SPN" SG_ 2558918398 SCROprtrInducementOvridSw_6881 6881;
BA_ "SigType" SG_ 2558918398 SCROprtrInducementOvridSw_6881 5;
BA_ "SPN" SG_ 2558918398 PerformanceBiasSelection_6874 6874;
BA_ "SigType" SG_ 2558918398 PerformanceBiasSelection_6874 1;
BA_ "SPN" SG_ 2558918398 EngFan2RqstedPercentSpeed_6730 6730;
BA_ "SigType" SG_ 2558918398 EngFan2RqstedPercentSpeed_6730 1;
BA_ "SPN" SG_ 2558852862 ExhVelocity_6829 6829;
BA_ "SigType" SG_ 2558852862 ExhVelocity_6829 1;
BA_ "SPN" SG_ 2558852862 ExhTemp_6785 6785;
BA_ "SigType" SG_ 2558852862 ExhTemp_6785 1;
BA_ "SPN" SG_ 2558852862 Dewpoint_6784 6784;
BA_ "SigType" SG_ 2558852862 Dewpoint_6784 5;
BA_ "SPN" SG_ 2558852862 RegenReq_6783 6783;
BA_ "SigType" SG_ 2558852862 RegenReq_6783 5;
BA_ "SPN" SG_ 2558852862 ShutdownReq_6782 6782;
BA_ "SigType" SG_ 2558852862 ShutdownReq_6782 5;
BA_ "SPN" SG_ 2558787326 PayloadCorrectionFactorCmd_6873 6873;
BA_ "SigType" SG_ 2558787326 PayloadCorrectionFactorCmd_6873 1;
BA_ "SPN" SG_ 2558787326 PayloadCalibCmdedWeight_6872 6872;
BA_ "SigType" SG_ 2558787326 PayloadCalibCmdedWeight_6872 1;
BA_ "SPN" SG_ 2558787326 PayloadCalibSetPointCmd_6871 6871;
BA_ "SPN" SG_ 2558721790 SnsrEnableSetting_7587 7587;
BA_ "SigType" SG_ 2558721790 SnsrEnableSetting_7587 5;
BA_ "SPN" SG_ 2558721790 OverTempSetting_6978 6978;
BA_ "SigType" SG_ 2558721790 OverTempSetting_6978 1;
BA_ "SPN" SG_ 2558721790 OvrPrssPTSetting_6977 6977;
BA_ "SigType" SG_ 2558721790 OvrPrssPTSetting_6977 1;
BA_ "SPN" SG_ 2558721790 ExtrmUndrPrssPTStting_6976 6976;
BA_ "SigType" SG_ 2558721790 ExtrmUndrPrssPTStting_6976 1;
BA_ "SPN" SG_ 2558721790 UndrPrssPTSetting_6975 6975;
BA_ "SigType" SG_ 2558721790 UndrPrssPTSetting_6975 1;
BA_ "SPN" SG_ 2558721790 ColdInflationPressSetting_6974 6974;
BA_ "SigType" SG_ 2558721790 ColdInflationPressSetting_6974 1;
BA_ "SPN" SG_ 2558721790 TireLocation_6973 6973;
BA_ "SPN" SG_ 2558656254 RqToPermitDEFDosingTestInjection 7516;
BA_ "SPN" SG_ 2558656254 RqToPermitDEFHydStiffnessCheck 7515;
BA_ "SigType" SG_ 2558656254 RqToPermitDEFHydStiffnessCheck 5;
BA_ "SPN" SG_ 2558656254 ThermalManagementInhReq 7331;
BA_ "SigType" SG_ 2558656254 ThermalManagementInhReq 5;
VAL_ 2566687742 PwrSupply 0 "Off" 1 "On" 2 "Error" 3 "Unavailable";
VAL_ 2566687742 DetectionStatus 0 "Initialization for particulate matter detection" 1 "Waiting for dew point" 2 "Particulate matter detection" 3 "Heater is active for particulate sensor regeneration" 4 "Cooling after particulate sensor regeneration" 5 "Heater diagnostics test" 6 "Relearning particulate sensor resistance after particulate sensor regeneration" 7 "Sensor regeneration did not complete due to system parameters out of range" 8 "Halt particulate matter detection" 15 "Not supported";
VAL_ 2365348350 EngLoadShareStatus 0 "Offline" 1 "Master" 2 "Slave" 3 "Loading" 4 "Unloading" 14 "Error" 15 "Unavailable";
VAL_ 2365348350 EngUnloadStatus 0 "Not Requested" 1 "Requested" 2 "Error" 3 "Not Available";
VAL_ 2633782014 BinWeighingErrorStatus 0 "No error" 1 "Bad lift cycle" 2 "Weighing error: bin lifted" 3 "Weighing error: empty bin lifted" 15 "Not available / not applicable";
VAL_ 2365346302 LiftAxle2Status 0 "Down" 1 "Unloading" 2 "Lifting" 3 "Up" 4 "Lowering" 5 "Loading" 6 "Error" 7 "Not available";
VAL_ 2365346302 LiftAxle1Status 0 "Down" 1 "Unloading" 2 "Lifting" 3 "Up" 4 "Lowering" 5 "Loading" 6 "Error" 7 "Not available";
VAL_ 2566672638 DeliveryTransactionStatus 0 "Transaction Not In Progress" 1 "Transaction In Progress" 2 "Transaction Complete" 14 "Error" 15 "Not Available";
VAL_ 2566672638 HaulModeStatus 0 "Not in Haul Mode" 1 "Loading" 2 "Approaching Loaded" 3 "Loaded" 4 "Unloading" 5 "Unloaded" 14 "Error" 15 "Not Available";
VAL_ 2566672382 PayloadWeightSensor8Status 0 "Sensor fully functional" 1 "Sensor degraded" 2 "Error" 3 "Not available";
VAL_ 2566672382 PayloadWeightSensor7Status 0 "Sensor fully functional" 1 "Sensor degraded" 2 "Error" 3 "Not available";
VAL_ 2566672382 PayloadWeightSensor6Status 0 "Sensor fully functional" 1 "Sensor degraded" 2 "Error" 3 "Not available";
VAL_ 2566672382 PayloadWeightSensor5Status 0 "Sensor fully functional" 1 "Sensor degraded" 2 "Error" 3 "Not available";
VAL_ 2566672382 PayloadWeightSensor4Status 0 "Sensor fully functional" 1 "Sensor degraded" 2 "Error" 3 "Not available";
VAL_ 2566672382 PayloadWeightSensor3Status 0 "Sensor fully functional" 1 "Sensor degraded" 2 "Error" 3 "Not available";
VAL_ 2566672382 PayloadWeightSensor2Status 0 "Sensor fully functional" 1 "Sensor degraded" 2 "Error" 3 "Not available";
VAL_ 2566672382 PayloadWeightSensor1Status 0 "Sensor fully functional" 1 "Sensor degraded" 2 "Error" 3 "Not available";
VAL_ 2566671614 SCROprtrInducementOverrideEnable 0 "Override not allowed" 1 "Override allowed" 2 "SAE Reserved" 3 "Not available";
VAL_ 2566671102 SCRSystemCleaningForcedStatus 0 "Not Active" 1 "Active, Forced by Switch" 2 "Active, Forced by Service Tool " 3 "Reserved for SAE Assignment" 4 "Reserved for SAE Assignment" 5 "Reserved for SAE Assignment" 6 "Reserved for SAE Assignment" 7 "not available";
VAL_ 2566671102 SCRSystmClnngAtmtcIntationConfig 0 "not enabled" 1 "enabled" 2 "reserved for SAE assignment" 3 "not available";
VAL_ 2566671102 SCRSystmClnngInhbtdDTVhclSpdBlwA 0 "not inhibited" 1 "inhibited" 2 "reserved for SAE assignment" 3 "not available";
VAL_ 2566671102 SCRSystmClnngInhbtdDTEngNtWrmdUp 0 "not inhibited" 1 "inhibited" 2 "reserved for SAE assignment" 3 "not available";
VAL_ 2566671102 SCRSystmClnngInhbtdDTPrmnntSystm 0 "not inhibited" 1 "inhibited" 2 "reserved for SAE assignment" 3 "not available";
VAL_ 2566671102 SCRSystmClnngInhbtdDTTmprrySystm 0 "not inhibited" 1 "inhibited" 2 "reserved for SAE assignment" 3 "not available";
VAL_ 2566671102 SCRSystmClnngInhbtdDTSystmTmeout 0 "not inhibited" 1 "inhibited" 2 "reserved for SAE assignment" 3 "not available";
VAL_ 2566671102 SCRSystmClnngInhbtdDTSystmFltAct 0 "not inhibited" 1 "inhibited" 2 "reserved for SAE assignment" 3 "not available";
VAL_ 2566671102 SCRSystmClnngInhbtdDTLwExhstTemp 0 "not inhibited" 1 "inhibited" 2 "reserved for SAE assignment" 3 "not available";
VAL_ 2566671102 SCRSystmClnngInhbtdDTPrkngBrkNtS 0 "not inhibited" 1 "inhibited" 2 "reserved for SAE assignment" 3 "not available";
VAL_ 2566671102 SCRSystmClnngInhbtdDTVhclSpdAbvA 0 "not inhibited" 1 "inhibited" 2 "reserved for SAE assignment" 3 "not available";
VAL_ 2566671102 SCRSystmClnngInhbtdDTOtOfNeutral 0 "not inhibited" 1 "inhibited" 2 "reserved for SAE assignment" 3 "not available";
VAL_ 2566671102 SCRSystmClnngInhbtdDTAcclPdlOffI 0 "not inhibited" 1 "inhibited" 2 "reserved for SAE assignment" 3 "not available";
VAL_ 2566671102 SCRSystmClnngInhbtdDeToPTOActive 0 "not inhibited" 1 "inhibited" 2 "reserved for SAE assignment" 3 "not available";
VAL_ 2566671102 SCRSystmClnngInhbtdDTSrvcBrkActv 0 "not inhibited" 1 "inhibited" 2 "reserved for SAE assignment" 3 "not available";
VAL_ 2566671102 SCRSystmClnngInhbtdDTCltchDsnggd 0 "not inhibited" 1 "inhibited" 2 "reserved for SAE assignment" 3 "not available";
VAL_ 2566671102 SCRSystmClnngInhbtdDTInhbtSwitch 0 "not inhibited" 1 "inhibited" 2 "reserved for SAE assignment" 3 "not available";
VAL_ 2566671102 SCRSystemCleaningInhibitedStatus 0 "not inhibited" 1 "inhibited" 2 "reserved for SAE assignment" 3 "not available";
VAL_ 2566671102 SCRSystemCleaningStatus 0 "not active" 1 "active" 2 "SCR system cleaning is needed" 3 "not available";
VAL_ 2566671102 SCRSystemCleaningLampCmd 0 "Off" 1 "On, solid" 2 "reserved for SAE assignment " 3 "reserved for SAE assignment" 4 "On, fast blink" 5 "reserved for SAE assignment" 6 "reserved for SAE assignment" 7 "not available";
VAL_ 2566668030 HtExchngerDebrisPurgeApproaching 0 "Not approaching" 1 "Approaching" 2 "SAE reserved" 3 "Not available";
VAL_ 2566668030 HeatExchangerDebrisPurgeStatus 0 "Inactive" 1 "Active" 2 "SAE reserved" 3 "Not available";
VAL_ 2499556094 HtrPwrSupplyDiagnosticStatus 0 "Tests monitored continuously" 1 "Tests supported but not completed this power cycle" 2 "Enable or pause conditions have allowed tests to execute this power cycle" 3 "Enable or pause conditions have allowed tests to execute this power cycle" 7 "Not Available";
VAL_ 2499556094 PwrSupplyDiagnosticStatus 0 "Tests monitored continuously" 1 "Tests supported but not completed this power cycle" 2 "Enable or pause conditions have allowed tests to execute this power cycle" 3 "Enable or pause conditions have allowed tests to execute this power cycle" 7 "Not Available";
VAL_ 2499556094 InputDiagnosticStatus 0 "Tests monitored continuously" 1 "Tests supported but not completed this power cycle" 2 "Enable or pause conditions have allowed tests to execute this power cycle" 3 "Enable or pause conditions have allowed tests to execute this power cycle" 7 "Not Available";
VAL_ 2499556094 HtrLowSideDriverDiagnosticStatus 0 "Tests monitored continuously" 1 "Tests supported but not completed this power cycle" 2 "Enable or pause conditions have allowed tests to execute this power cycle" 3 "Enable or pause conditions have allowed tests to execute this power cycle" 7 "Not Available";
VAL_ 2499556094 HtrHiSideDriverDiagnosticStatus 0 "Tests monitored continuously" 1 "Tests supported but not completed this power cycle" 2 "Enable or pause conditions have allowed tests to execute this power cycle" 3 "Enable or pause conditions have allowed tests to execute this power cycle" 7 "Not Available";
VAL_ 2566664702 DEFHtrCircuitBreaker 0 "off" 1 "on" 2 "error" 3 "not available";
VAL_ 2566664702 EngLoadReq 0 "No Request" 1 "Aftertreatment Engine Load Desired" 2 "Urgent Aftertreatment Engine Load Desired" 3 "Not Available";
VAL_ 2566664702 EngSpdIncreaseReq 0 "No Request" 1 "Aftertreatment Engine Speed Control Desired" 2 "Urgent Aftertreatment Engine Speed Control Desired" 3 "Not Available";
VAL_ 2566664702 ActiveRegenInhibitedDueToLowEP 0 "Not Inhibited" 1 "Inhibited" 2 "Reserved for SAE assignment" 3 "Not Available";
VAL_ 2566664702 ThermalManagementStatus 0 "Not active" 1 "Active" 2 "Reserved for SAE assignment" 3 "Not available";
VAL_ 2633773310 SCROprtrIndcmntOvrrdRnwlRequired 0 "Not Required" 1 "Required" 2 "Error" 3 "Not Available";
VAL_ 2633773310 SCROpratorInducementOverrideMode 0 "Not Available" 1 "Available" 2 "Active" 3 "Active Extended" 4 "Expired" 7 "Not Available";
VAL_ 2566663934 WastegateAct2MotorCurDis 0 "Do Not Disable" 1 "Disable" 2 "Reserved" 3 "Don't Care/Take No Action";
VAL_ 2566663934 CompressorBypassAct2MotorCurDis 0 "Do Not Disable" 1 "Disable" 2 "Reserved" 3 "Don't Care/Take No Action";
VAL_ 2566663934 CompressorBypassAct1MotorCurDis 0 "Do Not Disable" 1 "Disable" 2 "Reserved" 3 "Don't Care/Take No Action";
VAL_ 2566663934 EngThrttlVlv1MotorCurrentDisable 0 "Do Not Disable" 1 "Disable" 2 "Reserved" 3 "Don't Care/Take No Action";
VAL_ 2566663934 EngCylHdBypssActtr1MtrCrrntDsble 0 "Do Not Disable" 1 "Disable" 2 "Reserved" 3 "Don't Care/Take No Action";
VAL_ 2566663934 EngTrbWstgtActtr1MtrCrrntDisable 0 "Do Not Disable" 1 "Disable" 2 "Reserved" 3 "Don't Care/Take No Action";
VAL_ 2566663934 EngTrbCmprssrBlwffActtr1MtrCrrnt 0 "Do Not Disable" 1 "Disable" 2 "Reserved" 3 "Don't Care/Take No Action";
VAL_ 2566663422 TrlrBrkClprLnngClranceAxle5Right 0 "Caliper lining clearance is adequate" 1 "Caliper lining clearance is low" 2 "Error" 3 "Not available / not applicable";
VAL_ 2566663422 TrlrBrkClprLnngClaranceAxle5Left 0 "Caliper lining clearance is adequate" 1 "Caliper lining clearance is low" 2 "Error" 3 "Not available / not applicable";
VAL_ 2566663422 TrlrBrkClprLnngClranceAxle4Right 0 "Caliper lining clearance is adequate" 1 "Caliper lining clearance is low" 2 "Error" 3 "Not available / not applicable";
VAL_ 2566663422 TrlrBrkClprLnngClaranceAxle4Left 0 "Caliper lining clearance is adequate" 1 "Caliper lining clearance is low" 2 "Error" 3 "Not available / not applicable";
VAL_ 2566663422 TrlrBrkClprLnngClranceAxle3Right 0 "Caliper lining clearance is adequate" 1 "Caliper lining clearance is low" 2 "Error" 3 "Not available / not applicable";
VAL_ 2566663422 TrlrBrkClprLnngClaranceAxle3Left 0 "Caliper lining clearance is adequate" 1 "Caliper lining clearance is low" 2 "Error" 3 "Not available / not applicable";
VAL_ 2566663422 TrlrBrkClprLnngClranceAxle2Right 0 "Caliper lining clearance is adequate" 1 "Caliper lining clearance is low" 2 "Error" 3 "Not available / not applicable";
VAL_ 2566663422 TrlrBrkClprLnngClaranceAxle2Left 0 "Caliper lining clearance is adequate" 1 "Caliper lining clearance is low" 2 "Error" 3 "Not available / not applicable";
VAL_ 2566663422 TrlrBrkClprLnngClranceAxle1Right 0 "Caliper lining clearance is adequate" 1 "Caliper lining clearance is low" 2 "Error" 3 "Not available / not applicable";
VAL_ 2566663422 TrlrBrkClprLnngClaranceAxle1Left 0 "Caliper lining clearance is adequate" 1 "Caliper lining clearance is low" 2 "Error" 3 "Not available / not applicable";
VAL_ 2566663422 TrctrBrkClprLnngClrnceAxle5Right 0 "Caliper lining clearance is adequate" 1 "Caliper lining clearance is low" 2 "Error" 3 "Not available / not applicable";
VAL_ 2566663422 TrctrBrkClprLnngClranceAxle5Left 0 "Caliper lining clearance is adequate" 1 "Caliper lining clearance is low" 2 "Error" 3 "Not available / not applicable";
VAL_ 2566663422 TrctrBrkClprLnngClrnceAxle4Right 0 "Caliper lining clearance is adequate" 1 "Caliper lining clearance is low" 2 "Error" 3 "Not available / not applicable";
VAL_ 2566663422 TrctrBrkClprLnngClranceAxle4Left 0 "Caliper lining clearance is adequate" 1 "Caliper lining clearance is low" 2 "Error" 3 "Not available / not applicable";
VAL_ 2566663422 TrctrBrkClprLnngClrnceAxle3Right 0 "Caliper lining clearance is adequate" 1 "Caliper lining clearance is low" 2 "Error" 3 "Not available / not applicable";
VAL_ 2566663422 TrctrBrkClprLnngClranceAxle3Left 0 "Caliper lining clearance is adequate" 1 "Caliper lining clearance is low" 2 "Error" 3 "Not available / not applicable";
VAL_ 2566663422 TrctrBrkClprLnngClrnceAxle2Right 0 "Caliper lining clearance is adequate" 1 "Caliper lining clearance is low" 2 "Error" 3 "Not available / not applicable";
VAL_ 2566663422 TrctrBrkClprLnngClranceAxle2Left 0 "Caliper lining clearance is adequate" 1 "Caliper lining clearance is low" 2 "Error" 3 "Not available / not applicable";
VAL_ 2566663422 TrctrBrkClprLnngClrnceAxle1Right 0 "Caliper lining clearance is adequate" 1 "Caliper lining clearance is low" 2 "Error" 3 "Not available / not applicable";
VAL_ 2566663422 TrctrBrkClprLnngClranceAxle1Left 0 "Caliper lining clearance is adequate" 1 "Caliper lining clearance is low" 2 "Error" 3 "Not available / not applicable";
VAL_ 2566662654 LaneMarkQualityOnTheRightSide 0 "no lane marks detected" 1 "low reliablity of detected lane marks" 2 "good reliablity of detected lane marks" 3 "perfect recognition of lane marks" 6 "error" 7 "not available or not installed";
VAL_ 2566662654 LaneMarkQualityOnTheLeftSide 0 "no lane marks detected" 1 "low reliablity of detected lane marks" 2 "good reliablity of detected lane marks" 3 "perfect recognition of lane marks" 6 "error" 7 "not available or not installed";
VAL_ 2566662654 LaneDepartureAngleRight 251 "not in range" 252 "not reliable" 253 "reserved / not used" 254 "error" 255 "not available or not installed";
VAL_ 2566662654 LaneDepartureAngleLeft 251 "not in range" 252 "not reliable" 253 "reserved / not used" 254 "error" 255 "not available or not installed";
VAL_ 2566662654 RghtDstncTLnMrkFrmVehiclesMiddle 251 "not in range" 252 "not reliable" 253 "reserved / not used" 254 "error" 255 "not available or not installed";
VAL_ 2566662654 LftDstncTLnMrkFromVehiclesMiddle 251 "not in range" 252 "not reliable" 253 "reserved / not used" 254 "error" 255 "not available or not installed";
VAL_ 2364593150 PrdctvCrsCtrlDrvlnDsnggInhibitRq 0 "No Inhibit Request" 1 "Driveline Disengage Inhibit Request" 2 "Reserved" 3 "Don't care/take no action";
VAL_ 2364593150 VhclSpdCtrlOvrrideEventIndicator 0 "Speed Control event is not active" 1 "Speed Control event is active" 2 "Reserved" 3 "Not available";
VAL_ 2364593150 PrdctvCrsCtrlSpeedEventIndicator 0 "No speed event is active" 1 "Increased speed event is active" 2 "Decreased speed event is active" 3 "Not available";
VAL_ 2364593150 PredictiveCruiseCtrlEventInRange 0 "No PCC event in range" 1 "PCC event in range" 2 "Error" 3 "Not available";
VAL_ 2364593150 VehicleSpeedCtrlOverrideRq 0 "No speed control override requested" 1 "Speed control override requested" 2 "Reserved" 3 "Don't care/take no action";
VAL_ 2364593150 PredictiveCruiseCtrlState 0 "Disabled" 1 "Enabled" 2 "Enabled,  but not functional due to vehicle position not available" 3 "Enabled,  but not functional due to map position not available" 4 "Enabled,  but not functional due to road grade info not available" 5 "Enabled,  but not functional due to predicted path not available" 6 "Enabled,  but not functional due to vehicle speed below speed threshold" 7 "Enabled,  but not functional due to inhibited by driver" 8 "Enabled,  but not functional due to self test" 14 "Error" 15 "Not Available";
VAL_ 2364592894 InAirSourceVlv 0 "Off" 1 "On" 2 "Error" 3 "Not available";
VAL_ 2364592638 EngCylHdBypssActtr1OprtionStatus 0 "Normal" 1 "Alarm" 2 "Alarm High Severity" 3 "Derate Active" 4 "Controlled Shutdown Active" 5 "Uncontrolled Shutdown Active" 6 "Calibration in Progress" 14 "Error" 15 "Not available";
VAL_ 2364592638 EngCylHdBypssActuator1TempStatus 0 "High Most severe" 1 "High Least severe" 2 "In Range" 3 "Low Least severe" 4 "Low Most severe" 5 "Not Defined" 6 "Error" 7 "Not available";
VAL_ 2364592382 EngCyl24ExcludeFromCombustionRq 0 "Exclude from Combustion" 1 "Include for Combustion" 2 "Reserved" 3 "Not available/Do not care";
VAL_ 2364592382 EngCyl23ExcludeFromCombustionRq 0 "Exclude from Combustion" 1 "Include for Combustion" 2 "Reserved" 3 "Not available/Do not care";
VAL_ 2364592382 EngCyl22ExcludeFromCombustionRq 0 "Exclude from Combustion" 1 "Include for Combustion" 2 "Reserved" 3 "Not available/Do not care";
VAL_ 2364592382 EngCyl21ExcludeFromCombustionRq 0 "Exclude from Combustion" 1 "Include for Combustion" 2 "Reserved" 3 "Not available/Do not care";
VAL_ 2364592382 EngCyl20ExcludeFromCombustionRq 0 "Exclude from Combustion" 1 "Include for Combustion" 2 "Reserved" 3 "Not available/Do not care";
VAL_ 2364592382 EngCyl19ExcludeFromCombustionRq 0 "Exclude from Combustion" 1 "Include for Combustion" 2 "Reserved" 3 "Not available/Do not care";
VAL_ 2364592382 EngCyl18ExcludeFromCombustionRq 0 "Exclude from Combustion" 1 "Include for Combustion" 2 "Reserved" 3 "Not available/Do not care";
VAL_ 2364592382 EngCyl17ExcludeFromCombustionRq 0 "Exclude from Combustion" 1 "Include for Combustion" 2 "Reserved" 3 "Not available/Do not care";
VAL_ 2364592382 EngCyl16ExcludeFromCombustionRq 0 "Exclude from Combustion" 1 "Include for Combustion" 2 "Reserved" 3 "Not available/Do not care";
VAL_ 2364592382 EngCyl15ExcludeFromCombustionRq 0 "Exclude from Combustion" 1 "Include for Combustion" 2 "Reserved" 3 "Not available/Do not care";
VAL_ 2364592382 EngCyl14ExcludeFromCombustionRq 0 "Exclude from Combustion" 1 "Include for Combustion" 2 "Reserved" 3 "Not available/Do not care";
VAL_ 2364592382 EngCyl13ExcludeFromCombustionRq 0 "Exclude from Combustion" 1 "Include for Combustion" 2 "Reserved" 3 "Not available/Do not care";
VAL_ 2364592382 EngCyl12ExcludeFromCombustionRq 0 "Exclude from Combustion" 1 "Include for Combustion" 2 "Reserved" 3 "Not available/Do not care";
VAL_ 2364592382 EngCyl11ExcludeFromCombustionRq 0 "Exclude from Combustion" 1 "Include for Combustion" 2 "Reserved" 3 "Not available/Do not care";
VAL_ 2364592382 EngCyl10ExcludeFromCombustionRq 0 "Exclude from Combustion" 1 "Include for Combustion" 2 "Reserved" 3 "Not available/Do not care";
VAL_ 2364592382 EngCyl9ExcludeFromCombustionRq 0 "Exclude from Combustion" 1 "Include for Combustion" 2 "Reserved" 3 "Not available/Do not care";
VAL_ 2364592382 EngCyl8ExcludeFromCombustionRq 0 "Exclude from Combustion" 1 "Include for Combustion" 2 "Reserved" 3 "Not available/Do not care";
VAL_ 2364592382 EngCyl7ExcludeFromCombustionRq 0 "Exclude from Combustion" 1 "Include for Combustion" 2 "Reserved" 3 "Not available/Do not care";
VAL_ 2364592382 EngCyl6ExcludeFromCombustionRq 0 "Exclude from Combustion" 1 "Include for Combustion" 2 "Reserved" 3 "Not available/Do not care";
VAL_ 2364592382 EngCyl5ExcludeFromCombustionRq 0 "Exclude from Combustion" 1 "Include for Combustion" 2 "Reserved" 3 "Not available/Do not care";
VAL_ 2364592382 EngCyl4ExcludeFromCombustionRq 0 "Exclude from Combustion" 1 "Include for Combustion" 2 "Reserved" 3 "Not available/Do not care";
VAL_ 2364592382 EngCyl3ExcludeFromCombustionRq 0 "Exclude from Combustion" 1 "Include for Combustion" 2 "Reserved" 3 "Not available/Do not care";
VAL_ 2364592382 EngCyl2ExcludeFromCombustionRq 0 "Exclude from Combustion" 1 "Include for Combustion" 2 "Reserved" 3 "Not available/Do not care";
VAL_ 2364592382 EngCyl1ExcludeFromCombustionRq 0 "Exclude from Combustion" 1 "Include for Combustion" 2 "Reserved" 3 "Not available/Do not care";
VAL_ 2558918398 TransAutoNeutralEnableSw_7694 0 "Off" 1 "On" 2 "Error" 3 "Not Available";
VAL_ 2558918398 AFTRegenEngSpdAllwdSw_7580 0 "Aftertreatment regeneration is not allowed when engine speed exceeds regeneration threshold" 1 "Aftertreatment regeneration is allowed when engine speed exceeds regeneration threshold" 2 "Error" 3 "Not Available";
VAL_ 2558918398 ElevatedEngSpdAllowedSw_7579 0 "Not allowed to elevate engine speed" 1 "Allowed to elevate engine speed" 2 "Error" 3 "Not Available";
VAL_ 2558918398 PrdctiveCruiseCtrlDactivnRq_7437 0 "Predictive cruise control is not requested to be deactived" 1 "Predictive cruise control is requested to be deactived" 2 "Error" 3 "Not available";
VAL_ 2558918398 PredictiveCruiseCtrlEnblSw_7436 0 "Predictive cruise control is not enabled" 1 "Predictive cruise control is enabled" 2 "Error" 3 "Not available";
VAL_ 2558918398 HtExchngerDebrisPurgForceSw_7034 0 "not active" 1 "active" 2 "error" 3 "not available";
VAL_ 2558918398 HtExchngrDbrisPurgeInhbitSw_7033 0 "not active" 1 "active" 2 "error" 3 "not available";
VAL_ 2558918398 SCROprtrInducementOvridSw_6881 0 "Off" 1 "On" 2 "Error" 3 "Not available";
VAL_ 2558852862 Dewpoint_6784 0 "Dewpoint has not been reached" 1 "Dewpoint has been reached" 2 "SAE reserved" 3 "Not available";
VAL_ 2558852862 RegenReq_6783 0 "Regeneration not requested" 1 "Regeneration requested" 2 "SAE reserved" 3 "Not available";
VAL_ 2558852862 ShutdownReq_6782 0 "Shutdown request not active" 1 "Shutdown request active" 2 "SAE reserved" 3 "Not available";
VAL_ 2558787326 PayloadCalibSetPointCmd_6871 0 "Zero Point" 1 "Calibration Reference Point 1" 2 "Calibration Reference Point 2" 3 "Calibration Reference Point 3" 4 "Calibration Reference Point 4" 5 "Calibration Reference Point 5" 6 "Calibration Reference Point 6" 7 "Calibration Reference Point 7" 8 "Calibration Reference Point 8" 9 "Calibration Reference Point 9" 10 "End Point" 11 "Correction Point" 12 "Reset Calibration" 13 "Reserved" 14 "Error" 15 "Not Available";
VAL_ 2558721790 SnsrEnableSetting_7587 0 "Off / Isolate / Disable" 1 "On / Enable" 2 "Reserved / Not Defined" 3 "Don’t Care / Take No Action";
VAL_ 2558656254 RqToPermitDEFDosingTestInjection 0 "no request" 1 "request to permit DEF Dosing Test Injection or test injection is running" 2 "urgent request to permit DEF Dosing Test Injection or test injection is running" 7 "don't care";
VAL_ 2558656254 RqToPermitDEFHydStiffnessCheck 0 "no request" 1 "request to permit DEF hydraulic stiffness check or stiffness check is running" 2 "reserved" 3 "don't care";
VAL_ 2558656254 ThermalManagementInhReq 0 "Do not inhibit" 1 "Inhibit" 2 "Reserved for SAE assignment" 3 "Not Available";
